VERSION ""

NS_ :

BS_:

BU_: WPC2 RLPSU DPSU APSU PSB SHVU_RR vHS_B2 FCS EMCU SLB ARS RCM CGW_CCU vDummy_HS_B ATS RLHV SGU PFSU ALBCU DSAU SWRC SHVU_FR RCS RRPSU BLTN_CAM SCM DLBCU OHCL RWPC RRHV WPC HOD ASAU

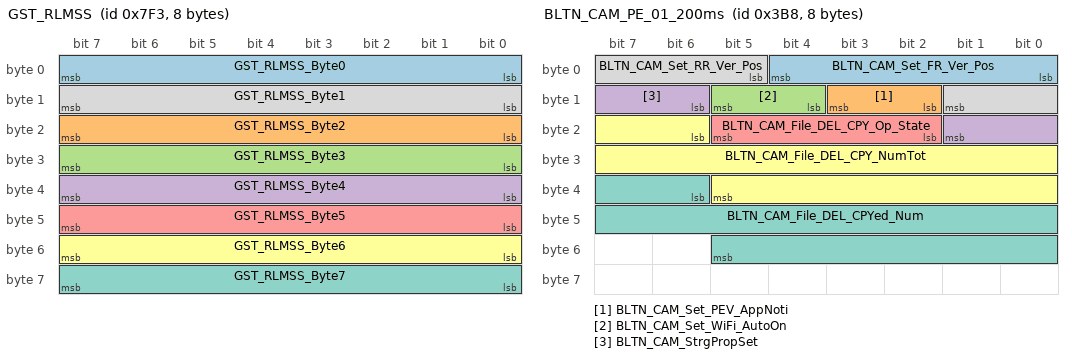
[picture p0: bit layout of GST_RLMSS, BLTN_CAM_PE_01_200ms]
BO_ 2035 GST_RLMSS: 8 CGW_CCU
 SG_ GST_RLMSS_Byte0 : 0|8@1+ (1,0) [0|0] ""  RLPSU
 SG_ GST_RLMSS_Byte2 : 16|8@1+ (1,0) [0|0] ""  RLPSU
 SG_ GST_RLMSS_Byte3 : 24|8@1+ (1,0) [0|0] ""  RLPSU
 SG_ GST_RLMSS_Byte4 : 32|8@1+ (1,0) [0|0] ""  RLPSU
 SG_ GST_RLMSS_Byte5 : 40|8@1+ (1,0) [0|0] ""  RLPSU
 SG_ GST_RLMSS_Byte6 : 48|8@1+ (1,0) [0|0] ""  RLPSU
 SG_ GST_RLMSS_Byte7 : 56|8@1+ (1,0) [0|0] ""  RLPSU
 SG_ GST_RLMSS_Byte1 : 8|8@1+ (1,0) [0|0] ""  RLPSU

BO_ 952 BLTN_CAM_PE_01_200ms: 8 BLTN_CAM
 SG_ BLTN_CAM_Set_FR_Ver_Pos : 0|5@1+ (1,0) [0|0] ""  CGW_CCU
 SG_ BLTN_CAM_Set_PEV_AppNoti : 10|2@1+ (1,0) [0|0] ""  CGW_CCU
 SG_ BLTN_CAM_Set_WiFi_AutoOn : 12|2@1+ (1,0) [0|0] ""  CGW_CCU
 SG_ BLTN_CAM_StrgPropSet : 14|4@1+ (1,0) [0|0] ""  CGW_CCU
 SG_ BLTN_CAM_File_DEL_CPY_Op_State : 18|4@1+ (1,0) [0|0] ""  CGW_CCU
 SG_ BLTN_CAM_File_DEL_CPY_NumTot : 22|16@1+ (1,0) [0|0] ""  CGW_CCU
 SG_ BLTN_CAM_File_DEL_CPYed_Num : 38|16@1+ (1,0) [0|0] ""  CGW_CCU
 SG_ BLTN_CAM_Set_RR_Ver_Pos : 5|5@1+ (1,0) [0|0] ""  CGW_CCU

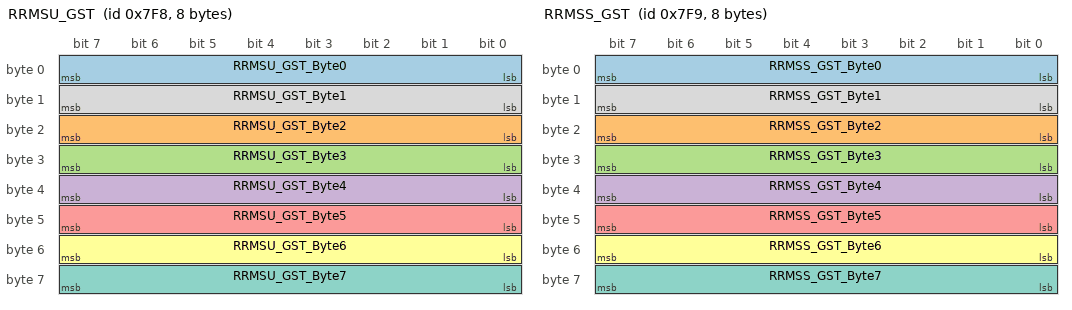
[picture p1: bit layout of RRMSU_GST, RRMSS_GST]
BO_ 2040 RRMSU_GST: 8 RRPSU
 SG_ RRMSU_GST_Byte0 : 0|8@1+ (1,0) [0|0] ""  CGW_CCU
 SG_ RRMSU_GST_Byte2 : 16|8@1+ (1,0) [0|0] ""  CGW_CCU
 SG_ RRMSU_GST_Byte3 : 24|8@1+ (1,0) [0|0] ""  CGW_CCU
 SG_ RRMSU_GST_Byte4 : 32|8@1+ (1,0) [0|0] ""  CGW_CCU
 SG_ RRMSU_GST_Byte5 : 40|8@1+ (1,0) [0|0] ""  CGW_CCU
 SG_ RRMSU_GST_Byte6 : 48|8@1+ (1,0) [0|0] ""  CGW_CCU
 SG_ RRMSU_GST_Byte7 : 56|8@1+ (1,0) [0|0] ""  CGW_CCU
 SG_ RRMSU_GST_Byte1 : 8|8@1+ (1,0) [0|0] ""  CGW_CCU

BO_ 2041 RRMSS_GST: 8 RRPSU
 SG_ RRMSS_GST_Byte0 : 0|8@1+ (1,0) [0|0] ""  CGW_CCU
 SG_ RRMSS_GST_Byte2 : 16|8@1+ (1,0) [0|0] ""  CGW_CCU
 SG_ RRMSS_GST_Byte3 : 24|8@1+ (1,0) [0|0] ""  CGW_CCU
 SG_ RRMSS_GST_Byte4 : 32|8@1+ (1,0) [0|0] ""  CGW_CCU
 SG_ RRMSS_GST_Byte5 : 40|8@1+ (1,0) [0|0] ""  CGW_CCU
 SG_ RRMSS_GST_Byte6 : 48|8@1+ (1,0) [0|0] ""  CGW_CCU
 SG_ RRMSS_GST_Byte7 : 56|8@1+ (1,0) [0|0] ""  CGW_CCU
 SG_ RRMSS_GST_Byte1 : 8|8@1+ (1,0) [0|0] ""  CGW_CCU

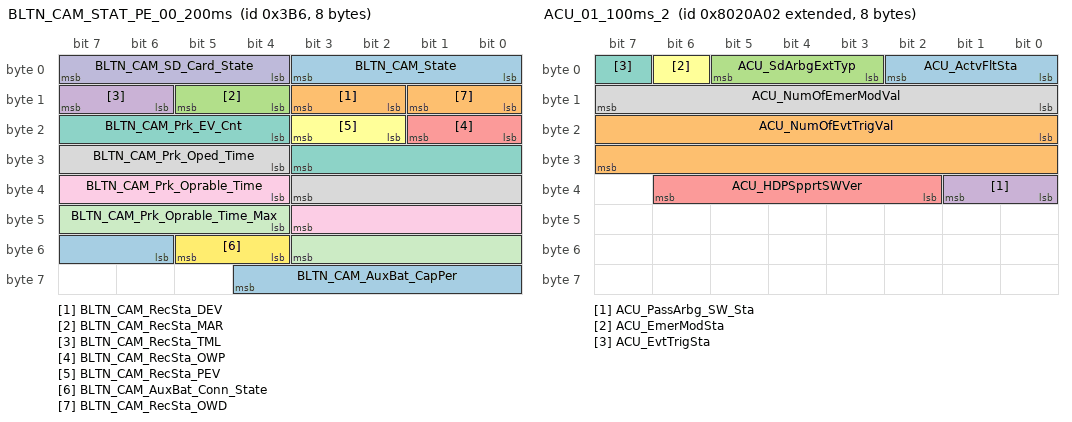
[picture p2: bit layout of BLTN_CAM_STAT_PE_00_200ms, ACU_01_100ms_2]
BO_ 950 BLTN_CAM_STAT_PE_00_200ms: 8 BLTN_CAM
 SG_ BLTN_CAM_State : 0|4@1+ (1,0) [0|0] ""  CGW_CCU
 SG_ BLTN_CAM_RecSta_DEV : 10|2@1+ (1,0) [0|0] ""  CGW_CCU
 SG_ BLTN_CAM_RecSta_MAR : 12|2@1+ (1,0) [0|0] ""  CGW_CCU
 SG_ BLTN_CAM_RecSta_TML : 14|2@1+ (1,0) [0|0] ""  CGW_CCU
 SG_ BLTN_CAM_RecSta_OWP : 16|2@1+ (1,0) [0|0] ""  CGW_CCU
 SG_ BLTN_CAM_RecSta_PEV : 18|2@1+ (1,0) [0|0] ""  CGW_CCU
 SG_ BLTN_CAM_Prk_EV_Cnt : 20|8@1+ (1,0) [0|0] ""  CGW_CCU
 SG_ BLTN_CAM_Prk_Oped_Time : 28|8@1+ (1,0) [0|0] "Hour"  CGW_CCU
 SG_ BLTN_CAM_Prk_Oprable_Time : 36|8@1+ (1,0) [0|0] "Hour"  CGW_CCU
 SG_ BLTN_CAM_SD_Card_State : 4|4@1+ (1,0) [0|0] ""  CGW_CCU
 SG_ BLTN_CAM_Prk_Oprable_Time_Max : 44|8@1+ (1,0) [0|0] "Hour"  CGW_CCU
 SG_ BLTN_CAM_AuxBat_Conn_State : 52|2@1+ (1,0) [0|0] ""  CGW_CCU
 SG_ BLTN_CAM_AuxBat_CapPer : 54|7@1+ (1,0) [0|0] "%"  CGW_CCU
 SG_ BLTN_CAM_RecSta_OWD : 8|2@1+ (1,0) [0|0] ""  CGW_CCU

BO_ 951 BLTN_CAM_PE_00_200ms: 8 BLTN_CAM
 SG_ BLTN_CAM_RecSet_OWD : 0|2@1+ (1,0) [0|0] ""  CGW_CCU
 SG_ BLTN_CAM_Set_Tim_Stm : 10|2@1+ (1,0) [0|0] ""  CGW_CCU
 SG_ BLTN_CAM_Set_Spd_Stm : 12|2@1+ (1,0) [0|0] ""  CGW_CCU
 SG_ BLTN_CAM_Set_Locatn_Stm : 14|2@1+ (1,0) [0|0] ""  CGW_CCU
 SG_ BLTN_CAM_Set_TrnSig_Stm : 16|2@1+ (1,0) [0|0] ""  CGW_CCU
 SG_ BLTN_CAM_Set_AclBrk_Stm : 18|2@1+ (1,0) [0|0] ""  CGW_CCU
 SG_ BLTN_CAM_RecSet_DEV : 2|2@1+ (1,0) [0|0] ""  CGW_CCU
 SG_ BLTN_CAM_Set_GearPos_Stm : 20|2@1+ (1,0) [0|0] ""  CGW_CCU
 SG_ BLTN_CAM_Set_EVSen_Stm : 22|2@1+ (1,0) [0|0] ""  CGW_CCU
 SG_ BLTN_CAM_Set_StrAngl_Stm : 24|2@1+ (1,0) [0|0] ""  CGW_CCU
 SG_ BLTN_CAM_Set_PrkTime : 30|8@1+ (1,0) [0|0] "Hour"  CGW_CCU
 SG_ BLTN_CAM_Set_EV_BfrTime : 38|5@1+ (1,0) [0|0] ""  CGW_CCU
 SG_ BLTN_CAM_RecSet_OWP : 4|2@1+ (1,0) [0|0] ""  CGW_CCU
 SG_ BLTN_CAM_Set_EV_AftTime : 43|5@1+ (1,0) [0|0] ""  CGW_CCU
 SG_ BLTN_CAM_Set_Drv_TML_Int : 48|4@1+ (1,0) [0|0] ""  CGW_CCU
 SG_ BLTN_CAM_SenSet_DEV : 52|4@1+ (1,0) [0|0] ""  CGW_CCU
 SG_ BLTN_CAM_SenSet_PEV : 56|4@1+ (1,0) [0|0] ""  CGW_CCU
 SG_ BLTN_CAM_RecSet_PEV : 6|2@1+ (1,0) [0|0] ""  CGW_CCU
 SG_ BLTN_CAM_AudRec_Set : 8|2@1+ (1,0) [0|0] ""  CGW_CCU

BO_ 2281835010 ACU_01_100ms_2: 8 CGW_CCU
 SG_ ACU_ActvFltSta : 0|3@1+ (1,0) [0|0] "" Vector__XXX
 SG_ ACU_NumOfEvtTrigVal : 16|16@1+ (1,0) [0|0] "" Vector__XXX
 SG_ ACU_SdArbgExtTyp : 3|3@1+ (1,0) [0|0] "" Vector__XXX
 SG_ ACU_PassArbg_SW_Sta : 32|2@1+ (1,0) [0|0] "" Vector__XXX
 SG_ ACU_HDPSpprtSWVer : 34|5@1+ (1,0) [0|0] "" Vector__XXX
 SG_ ACU_EmerModSta : 6|1@1+ (1,0) [0|0] "" Vector__XXX
 SG_ ACU_EvtTrigSta : 7|1@1+ (1,0) [0|0] "" Vector__XXX
 SG_ ACU_NumOfEmerModVal : 8|8@1+ (1,0) [0|0] "" Vector__XXX

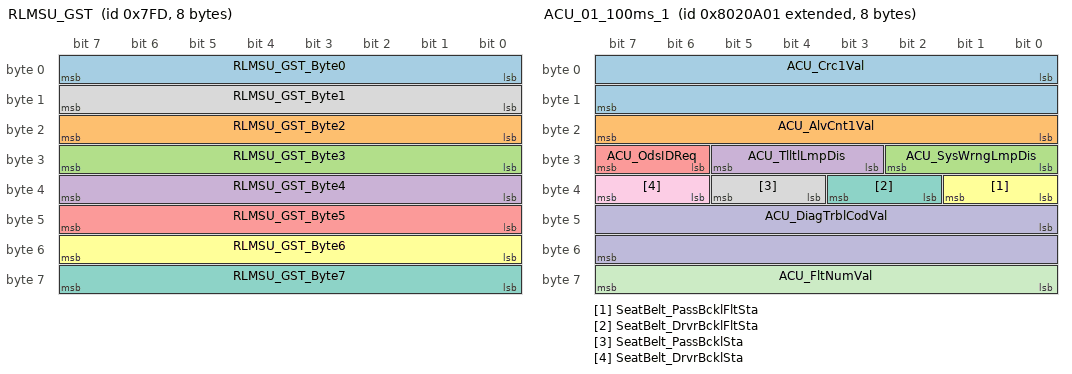
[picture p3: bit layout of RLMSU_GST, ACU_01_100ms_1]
BO_ 2045 RLMSU_GST: 8 RLPSU
 SG_ RLMSU_GST_Byte0 : 0|8@1+ (1,0) [0|0] ""  CGW_CCU
 SG_ RLMSU_GST_Byte2 : 16|8@1+ (1,0) [0|0] ""  CGW_CCU
 SG_ RLMSU_GST_Byte3 : 24|8@1+ (1,0) [0|0] ""  CGW_CCU
 SG_ RLMSU_GST_Byte4 : 32|8@1+ (1,0) [0|0] ""  CGW_CCU
 SG_ RLMSU_GST_Byte5 : 40|8@1+ (1,0) [0|0] ""  CGW_CCU
 SG_ RLMSU_GST_Byte6 : 48|8@1+ (1,0) [0|0] ""  CGW_CCU
 SG_ RLMSU_GST_Byte7 : 56|8@1+ (1,0) [0|0] ""  CGW_CCU
 SG_ RLMSU_GST_Byte1 : 8|8@1+ (1,0) [0|0] ""  CGW_CCU

BO_ 2281835009 ACU_01_100ms_1: 8 CGW_CCU
 SG_ ACU_Crc1Val : 0|16@1+ (1,0) [0|0] ""  OHCL
 SG_ ACU_AlvCnt1Val : 16|8@1+ (1,0) [0|0] ""  OHCL
 SG_ ACU_SysWrngLmpDis : 24|3@1+ (1,0) [0|0] "" Vector__XXX
 SG_ ACU_TlltlLmpDis : 27|3@1+ (1,0) [0|0] ""  OHCL
 SG_ ACU_OdsIDReq : 30|2@1+ (1,0) [0|0] "" Vector__XXX
 SG_ SeatBelt_PassBcklFltSta : 32|2@1+ (1,0) [0|0] ""  PSB
 SG_ SeatBelt_DrvrBcklFltSta : 34|2@1+ (1,0) [0|0] ""  PSB
 SG_ SeatBelt_PassBcklSta : 36|2@1+ (1,0) [0|0] ""  PSB,APSU,ATS
 SG_ SeatBelt_DrvrBcklSta : 38|2@1+ (1,0) [0|0] ""  PSB
 SG_ ACU_DiagTrblCodVal : 40|16@1+ (1,0) [0|0] "" Vector__XXX
 SG_ ACU_FltNumVal : 56|8@1+ (1,0) [0|0] "" Vector__XXX

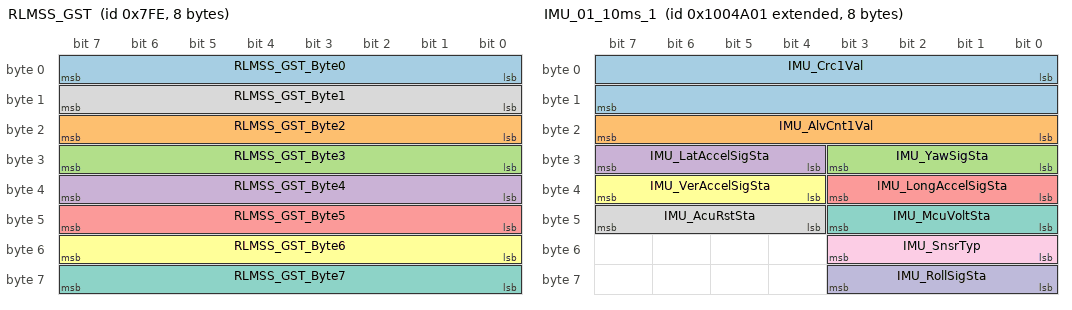
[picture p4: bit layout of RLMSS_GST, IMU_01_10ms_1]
BO_ 2046 RLMSS_GST: 8 RLPSU
 SG_ RLMSS_GST_Byte0 : 0|8@1+ (1,0) [0|0] ""  CGW_CCU
 SG_ RLMSS_GST_Byte2 : 16|8@1+ (1,0) [0|0] ""  CGW_CCU
 SG_ RLMSS_GST_Byte3 : 24|8@1+ (1,0) [0|0] ""  CGW_CCU
 SG_ RLMSS_GST_Byte4 : 32|8@1+ (1,0) [0|0] ""  CGW_CCU
 SG_ RLMSS_GST_Byte5 : 40|8@1+ (1,0) [0|0] ""  CGW_CCU
 SG_ RLMSS_GST_Byte6 : 48|8@1+ (1,0) [0|0] ""  CGW_CCU
 SG_ RLMSS_GST_Byte7 : 56|8@1+ (1,0) [0|0] ""  CGW_CCU
 SG_ RLMSS_GST_Byte1 : 8|8@1+ (1,0) [0|0] ""  CGW_CCU

BO_ 2164279809 IMU_01_10ms_1: 8 CGW_CCU
 SG_ IMU_Crc1Val : 0|16@1+ (1,0) [0|0] "" Vector__XXX
 SG_ IMU_AlvCnt1Val : 16|8@1+ (1,0) [0|0] "" Vector__XXX
 SG_ IMU_YawSigSta : 24|4@1+ (1,0) [0|0] ""  PSB
 SG_ IMU_LatAccelSigSta : 28|4@1+ (1,0) [0|0] ""  PSB
 SG_ IMU_LongAccelSigSta : 32|4@1+ (1,0) [0|0] ""  PSB
 SG_ IMU_VerAccelSigSta : 36|4@1+ (1,0) [0|0] "" Vector__XXX
 SG_ IMU_McuVoltSta : 40|4@1+ (1,0) [0|0] "" Vector__XXX
 SG_ IMU_AcuRstSta : 44|4@1+ (1,0) [0|0] "" Vector__XXX
 SG_ IMU_SnsrTyp : 48|4@1+ (1,0) [0|0] "" Vector__XXX
 SG_ IMU_RollSigSta : 56|4@1+ (1,0) [0|0] "" Vector__XXX

BO_ 2164279811 IMU_01_10ms_3: 8 CGW_CCU
 SG_ IMU_SeralNumVal : 0|48@1+ (1,0) [0|0] "" Vector__XXX

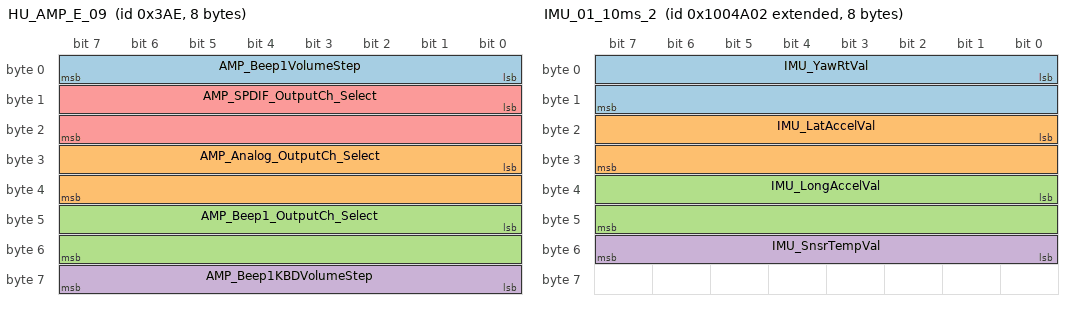
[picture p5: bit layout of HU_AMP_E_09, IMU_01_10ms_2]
BO_ 942 HU_AMP_E_09: 8 CGW_CCU
 SG_ AMP_Beep1VolumeStep : 0|8@1+ (1,0) [0|0] ""  ATS
 SG_ AMP_Analog_OutputCh_Select : 24|16@1+ (1,0) [0|0] "" Vector__XXX
 SG_ AMP_Beep1_OutputCh_Select : 40|16@1+ (1,0) [0|0] "" Vector__XXX
 SG_ AMP_Beep1KBDVolumeStep : 56|8@1+ (1,0) [0|0] "" Vector__XXX
 SG_ AMP_SPDIF_OutputCh_Select : 8|16@1+ (1,0) [0|0] "" Vector__XXX

BO_ 2164279810 IMU_01_10ms_2: 8 CGW_CCU
 SG_ IMU_YawRtVal : 0|16@1+ (0.005,-163.84) [0|0] "¢ª/s"  PSB
 SG_ IMU_LatAccelVal : 16|16@1+ (0.000127465,-4.17677312) [0|0] "g"  PSB
 SG_ IMU_LongAccelVal : 32|16@1+ (0.000127465,-4.17677312) [0|0] "g"  PSB
 SG_ IMU_SnsrTempVal : 48|8@1+ (1,-68) [0|0] "¡É" Vector__XXX

BO_ 2164279812 IMU_01_10ms_4: 8 CGW_CCU
 SG_ IMU_RollRtVal : 0|16@1+ (0.005,-163.84) [0|0] "¢ª/s" Vector__XXX
 SG_ IMU_VerAccelVal : 16|16@1+ (0.000127465,-4.17677312) [0|0] "g" Vector__XXX

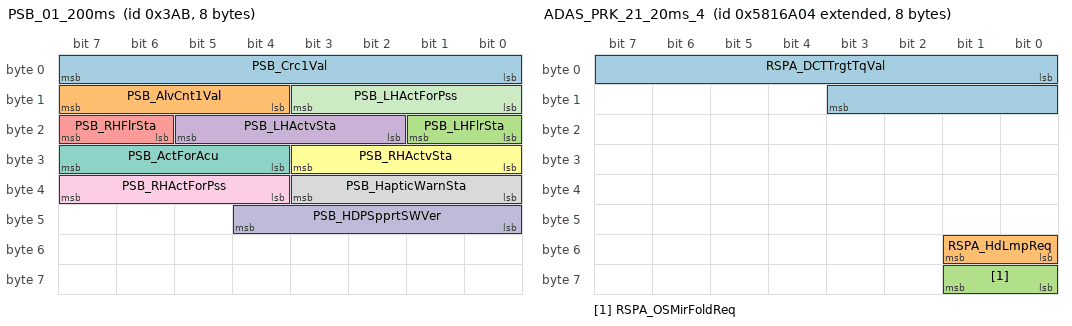
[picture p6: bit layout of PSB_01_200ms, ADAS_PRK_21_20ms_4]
BO_ 939 PSB_01_200ms: 8 PSB
 SG_ PSB_Crc1Val : 0|8@1+ (1,0) [0|0] ""  CGW_CCU
 SG_ PSB_AlvCnt1Val : 12|4@1+ (1,0) [0|0] ""  CGW_CCU
 SG_ PSB_LHFlrSta : 16|2@1+ (1,0) [0|0] ""  CGW_CCU
 SG_ PSB_LHActvSta : 18|4@1+ (1,0) [0|0] ""  CGW_CCU
 SG_ PSB_RHFlrSta : 22|2@1+ (1,0) [0|0] ""  CGW_CCU
 SG_ PSB_RHActvSta : 24|4@1+ (1,0) [0|0] ""  APSU,CGW_CCU
 SG_ PSB_ActForAcu : 28|4@1+ (1,0) [0|0] ""  CGW_CCU
 SG_ PSB_HapticWarnSta : 32|4@1+ (1,0) [0|0] ""  CGW_CCU
 SG_ PSB_RHActForPss : 36|4@1+ (1,0) [0|0] ""  APSU,RLPSU,RRPSU
 SG_ PSB_HDPSpprtSWVer : 40|5@1+ (1,0) [0|0] ""  CGW_CCU
 SG_ PSB_LHActForPss : 8|4@1+ (1,0) [0|0] ""  RLPSU,RRPSU

BO_ 2239851012 ADAS_PRK_21_20ms_4: 8 CGW_CCU
 SG_ RSPA_DCTTrgtTqVal : 0|12@1- (1,0) [0|0] "Nm" Vector__XXX
 SG_ RSPA_HdLmpReq : 48|2@1+ (1,0) [0|0] "" Vector__XXX
 SG_ RSPA_OSMirFoldReq : 56|2@1+ (1,0) [0|0] "" Vector__XXX

BO_ 934 PTGM_01_200ms: 8 CGW_CCU
 SG_ PTGM_Crc1Val : 0|8@1+ (1,0) [0|0] "" Vector__XXX
 SG_ PTGM_AlvCnt1Val : 12|4@1+ (1,0) [0|0] "" Vector__XXX
 SG_ PTGM_HazardSta : 16|2@1+ (1,0) [0|0] "" Vector__XXX
 SG_ PTGM_ModSta : 18|2@1+ (1,0) [0|0] "" Vector__XXX
 SG_ PTGM_MovSta : 20|2@1+ (1,0) [0|0] "" Vector__XXX
 SG_ PTGM_OptTyp : 22|2@1+ (1,0) [0|0] "" Vector__XXX
 SG_ PTGM_ReleaseRlySta : 24|2@1+ (1,0) [0|0] ""  APSU,PFSU
 SG_ PTGM_TrnkLkSwSta : 26|2@1+ (1,0) [0|0] "" Vector__XXX
 SG_ PTGM_UsmSetSta : 28|2@1+ (1,0) [0|0] "" Vector__XXX
 SG_ PTGM_HeightRValue : 32|3@1+ (1,0) [0|0] "" Vector__XXX
 SG_ PTGM_OpnClsState : 35|4@1+ (1,0) [0|0] "" Vector__XXX
 SG_ PTGM_CmdWarn : 40|3@1+ (1,0) [0|0] "" Vector__XXX
 SG_ PTGM_AntiPinchSnsr : 43|2@1+ (1,0) [0|0] "" Vector__XXX
 SG_ PTGM_AutoWashModeSta : 45|3@1+ (1,0) [0|0] "" Vector__XXX
 SG_ PTGM_FobSrch_Req : 52|2@1+ (1,0) [0|0] "" Vector__XXX
 SG_ PTGM_TlgtAwayCloseRValue : 54|2@1+ (1,0) [0|0] "" Vector__XXX
 SG_ PTGM_TrnkTlgtOption : 56|2@1+ (1,0) [0|0] "" Vector__XXX
 SG_ PTGM_LatchType : 58|2@1+ (1,0) [0|0] "" Vector__XXX
 SG_ PTGM_SpeedRValue : 8|4@1+ (1,0) [0|0] "" Vector__XXX

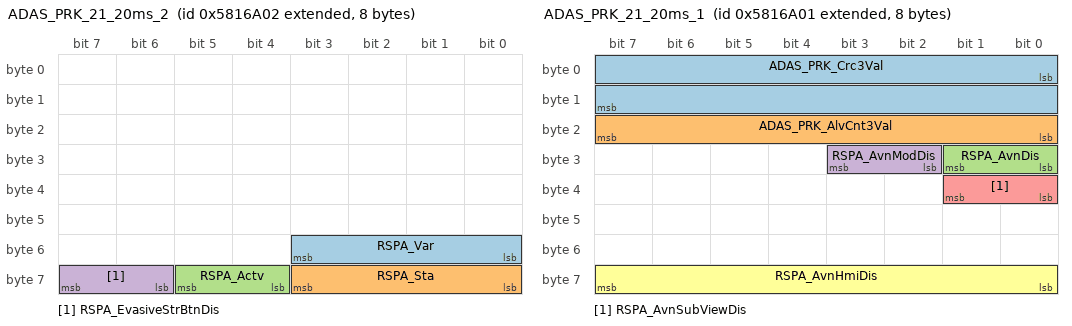
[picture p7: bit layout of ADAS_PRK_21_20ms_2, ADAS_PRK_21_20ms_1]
BO_ 2239851010 ADAS_PRK_21_20ms_2: 8 CGW_CCU
 SG_ RSPA_Var : 48|4@1+ (1,0) [0|0] "" Vector__XXX
 SG_ RSPA_Sta : 56|4@1+ (1,0) [0|0] "" Vector__XXX
 SG_ RSPA_Actv : 60|2@1+ (1,0) [0|0] "" Vector__XXX
 SG_ RSPA_EvasiveStrBtnDis : 62|2@1+ (1,0) [0|0] "" Vector__XXX

BO_ 929 SCM_03_200ms: 8 SCM
 SG_ SCM_Opt : 0|2@1+ (1,0) [0|0] ""  DPSU,CGW_CCU
 SG_ Tilt_VirtualLimExist : 10|2@1+ (1,0) [0|0] ""  CGW_CCU
 SG_ Tele_SnsrErr : 12|2@1+ (1,0) [0|0] ""  CGW_CCU
 SG_ Tele_VirtualLim : 14|2@1+ (1,0) [0|0] ""  CGW_CCU
 SG_ Tele_VirtualLimExist : 16|2@1+ (1,0) [0|0] ""  CGW_CCU
 SG_ TiltTele_Profile1MemoryExist : 18|2@1+ (1,0) [0|0] ""  CGW_CCU
 SG_ Tilt_MnlSwSta : 2|2@1+ (1,0) [0|0] ""  CGW_CCU
 SG_ TiltTele_Profile2MemoryExist : 20|2@1+ (1,0) [0|0] ""  CGW_CCU
 SG_ TiltTele_GuestMemoryExist : 22|2@1+ (1,0) [0|0] ""  CGW_CCU
 SG_ TiltTele_IMS1MemoryExist : 24|2@1+ (1,0) [0|0] ""  CGW_CCU
 SG_ TiltTele_IMS2MemoryExist : 26|2@1+ (1,0) [0|0] ""  CGW_CCU
 SG_ TiltTele_IMS3MemoryExist : 28|2@1+ (1,0) [0|0] ""  CGW_CCU
 SG_ TiltTele_ReturnMemoryExist : 30|2@1+ (1,0) [0|0] ""  CGW_CCU
 SG_ Tilt_OpSta : 32|2@1+ (1,0) [0|0] ""  CGW_CCU
 SG_ Tele_OpSta : 34|2@1+ (1,0) [0|0] ""  CGW_CCU
 SG_ Tele_MnlSwSta : 4|2@1+ (1,0) [0|0] ""  CGW_CCU
 SG_ Tilt_SnsrErr : 6|2@1+ (1,0) [0|0] ""  CGW_CCU
 SG_ Tilt_VirtualLim : 8|2@1+ (1,0) [0|0] ""  CGW_CCU

BO_ 2239851011 ADAS_PRK_21_20ms_3: 8 CGW_CCU
 SG_ RSPA_TrgtGearSta : 0|3@1+ (1,0) [0|0] "" Vector__XXX
 SG_ RSPA_IdOutWarnReq : 10|2@1+ (1,0) [0|0] ""  DPSU
 SG_ RSPA_IndBlnkReq : 12|3@1+ (1,0) [0|0] "" Vector__XXX
 SG_ RSPA_SysOff : 15|1@1+ (1,0) [0|0] "" Vector__XXX
 SG_ RSPA_DccCmd : 16|2@1+ (1,0) [0|0] "" Vector__XXX
 SG_ RSPA_StopReq : 18|2@1+ (1,0) [0|0] "" Vector__XXX
 SG_ RSPA_SelDevInfo : 20|2@1+ (1,0) [0|0] "" Vector__XXX
 SG_ RSPA_SelFuncInfo : 22|2@1+ (1,0) [0|0] "" Vector__XXX
 SG_ RSPA_TrgtVehSpdVal : 24|10@1+ (0.01,0) [0|0] "km/h" Vector__XXX
 SG_ RSPA_EpbReq : 3|2@1+ (1,0) [0|0] "" Vector__XXX
 SG_ RSPA_AddtnlAccelActv : 34|2@1+ (1,0) [0|0] "" Vector__XXX
 SG_ RSPA_Opt : 36|2@1+ (1,0) [0|0] "" Vector__XXX
 SG_ RSPA_RmtPrlExitDis : 38|2@1+ (1,0) [0|0] "" Vector__XXX
 SG_ RSPA_TrgtTqVal : 40|12@1- (1,0) [0|0] "Nm" Vector__XXX
 SG_ RSPA_ExtLampReq : 5|3@1+ (1,0) [0|0] "" Vector__XXX
 SG_ RSPA_UppLtTypDis : 52|3@1+ (1,0) [0|0] "" Vector__XXX
 SG_ RSPA_LwrLtTypDis : 55|3@1+ (1,0) [0|0] "" Vector__XXX
 SG_ RSPA_UppRtTypDis : 58|3@1+ (1,0) [0|0] "" Vector__XXX
 SG_ RSPA_LwrRtTypDis : 61|3@1+ (1,0) [0|0] "" Vector__XXX
 SG_ RSPA_CrankingReq : 8|2@1+ (1,0) [0|0] "" Vector__XXX

BO_ 2239851009 ADAS_PRK_21_20ms_1: 8 CGW_CCU
 SG_ ADAS_PRK_Crc3Val : 0|16@1+ (1,0) [0|0] "" Vector__XXX
 SG_ ADAS_PRK_AlvCnt3Val : 16|8@1+ (1,0) [0|0] "" Vector__XXX
 SG_ RSPA_AvnDis : 24|2@1+ (1,0) [0|0] "" Vector__XXX
 SG_ RSPA_AvnModDis : 26|2@1+ (1,0) [0|0] "" Vector__XXX
 SG_ RSPA_AvnSubViewDis : 32|2@1+ (1,0) [0|0] "" Vector__XXX
 SG_ RSPA_AvnHmiDis : 56|8@1+ (1,0) [0|0] "" Vector__XXX

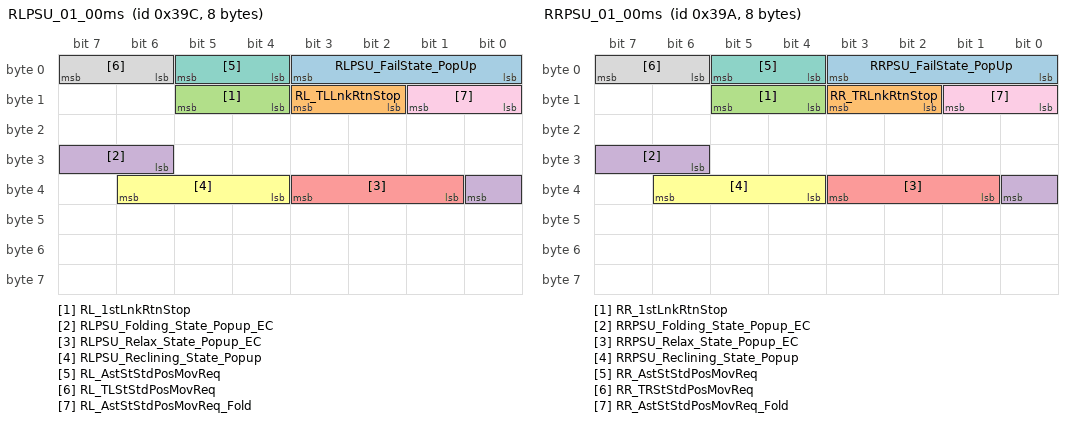
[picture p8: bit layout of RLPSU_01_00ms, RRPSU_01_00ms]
BO_ 924 RLPSU_01_00ms: 8 RRPSU
 SG_ RLPSU_FailState_PopUp : 0|4@1+ (1,0) [0|0] ""  CGW_CCU
 SG_ RL_TLLnkRtnStop : 10|2@1+ (1,0) [0|0] ""  PFSU
 SG_ RL_1stLnkRtnStop : 12|2@1+ (1,0) [0|0] ""  APSU,DPSU
 SG_ RLPSU_Folding_State_Popup_EC : 30|3@1+ (1,0) [0|0] ""  CGW_CCU
 SG_ RLPSU_Relax_State_Popup_EC : 33|3@1+ (1,0) [0|0] "" Vector__XXX
 SG_ RLPSU_Reclining_State_Popup : 36|3@1+ (1,0) [0|0] "" Vector__XXX
 SG_ RL_AstStStdPosMovReq : 4|2@1+ (1,0) [0|0] ""  APSU
 SG_ RL_TLStStdPosMovReq : 6|2@1+ (1,0) [0|0] ""  PFSU
 SG_ RL_AstStStdPosMovReq_Fold : 8|2@1+ (1,0) [0|0] ""  APSU

BO_ 922 RRPSU_01_00ms: 8 RRPSU
 SG_ RRPSU_FailState_PopUp : 0|4@1+ (1,0) [0|0] ""  CGW_CCU
 SG_ RR_TRLnkRtnStop : 10|2@1+ (1,0) [0|0] ""  PFSU
 SG_ RR_1stLnkRtnStop : 12|2@1+ (1,0) [0|0] ""  APSU,DPSU
 SG_ RRPSU_Folding_State_Popup_EC : 30|3@1+ (1,0) [0|0] ""  CGW_CCU
 SG_ RRPSU_Relax_State_Popup_EC : 33|3@1+ (1,0) [0|0] "" Vector__XXX
 SG_ RRPSU_Reclining_State_Popup : 36|3@1+ (1,1) [0|0] "" Vector__XXX
 SG_ RR_AstStStdPosMovReq : 4|2@1+ (1,0) [0|0] ""  APSU
 SG_ RR_TRStStdPosMovReq : 6|2@1+ (1,0) [0|0] ""  PFSU
 SG_ RR_AstStStdPosMovReq_Fold : 8|2@1+ (1,0) [0|0] ""  APSU

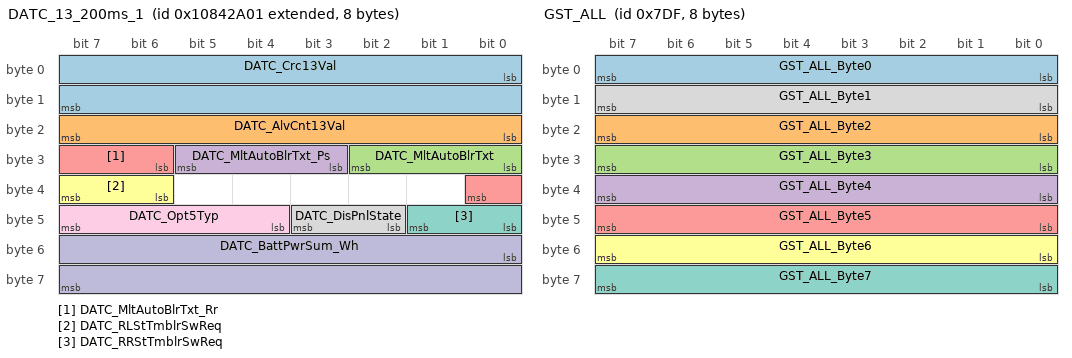
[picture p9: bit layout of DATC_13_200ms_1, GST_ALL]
BO_ 2424580609 DATC_13_200ms_1: 8 CGW_CCU
 SG_ DATC_Crc13Val : 0|16@1+ (1,0) [0|0] "" Vector__XXX
 SG_ DATC_AlvCnt13Val : 16|8@1+ (1,0) [0|0] "" Vector__XXX
 SG_ DATC_MltAutoBlrTxt : 24|3@1+ (1,0) [0|0] ""  ATS
 SG_ DATC_MltAutoBlrTxt_Ps : 27|3@1+ (1,0) [0|0] ""  ATS
 SG_ DATC_MltAutoBlrTxt_Rr : 30|3@1+ (1,0) [0|0] ""  ATS
 SG_ DATC_RLStTmblrSwReq : 38|2@1+ (1,0) [0|0] ""  RLHV,RRHV,SHVU_FR,SHVU_RR,RLPSU
 SG_ DATC_RRStTmblrSwReq : 40|2@1+ (1,0) [0|0] ""  RRHV,SHVU_FR,SHVU_RR,RRPSU
 SG_ DATC_DisPnlState : 42|2@1+ (1,0) [0|0] "" Vector__XXX
 SG_ DATC_Opt5Typ : 44|4@1+ (1,0) [0|0] ""  ATS
 SG_ DATC_BattPwrSum_Wh : 48|16@1+ (1,0) [0|0] "Wh" Vector__XXX

BO_ 2015 GST_ALL: 8 CGW_CCU
 SG_ GST_ALL_Byte0 : 0|8@1+ (1,0) [0|0] ""  FCS,SCM,WPC,RWPC,PSB,SLB,ARS,SWRC,APSU,RLHV,RRHV,SHVU_FR,SHVU_RR,DPSU,DLBCU,PFSU,RCS,RRPSU,RLPSU,HOD,ATS,DSAU,ASAU,RCM,EMCU,SGU,ALBCU,WPC2
 SG_ GST_ALL_Byte2 : 16|8@1+ (1,0) [0|0] ""  FCS,SCM,WPC,RWPC,PSB,SLB,ARS,SWRC,APSU,RLHV,RRHV,SHVU_FR,SHVU_RR,DPSU,DLBCU,PFSU,RCS,RRPSU,RLPSU,HOD,ATS,DSAU,ASAU,RCM,EMCU,SGU,ALBCU,WPC2
 SG_ GST_ALL_Byte3 : 24|8@1+ (1,0) [0|0] ""  FCS,SCM,WPC,RWPC,PSB,SLB,ARS,SWRC,APSU,RLHV,RRHV,SHVU_FR,SHVU_RR,DPSU,DLBCU,PFSU,RCS,RRPSU,RLPSU,HOD,ATS,DSAU,ASAU,RCM,EMCU,SGU,ALBCU,WPC2
 SG_ GST_ALL_Byte4 : 32|8@1+ (1,0) [0|0] ""  FCS,SCM,WPC,RWPC,PSB,SLB,ARS,SWRC,APSU,RLHV,RRHV,SHVU_FR,SHVU_RR,DPSU,DLBCU,PFSU,RCS,RRPSU,RLPSU,HOD,ATS,DSAU,ASAU,RCM,EMCU,SGU,ALBCU,WPC2
 SG_ GST_ALL_Byte5 : 40|8@1+ (1,0) [0|0] ""  FCS,SCM,WPC,RWPC,PSB,SLB,ARS,SWRC,APSU,RLHV,RRHV,SHVU_FR,SHVU_RR,DPSU,DLBCU,PFSU,RCS,RRPSU,RLPSU,HOD,ATS,DSAU,ASAU,RCM,EMCU,SGU,ALBCU,WPC2
 SG_ GST_ALL_Byte6 : 48|8@1+ (1,0) [0|0] ""  FCS,SCM,WPC,RWPC,PSB,SLB,ARS,SWRC,APSU,RLHV,RRHV,SHVU_FR,SHVU_RR,DPSU,DLBCU,PFSU,RCS,RRPSU,RLPSU,HOD,ATS,DSAU,ASAU,RCM,EMCU,SGU,ALBCU,WPC2
 SG_ GST_ALL_Byte7 : 56|8@1+ (1,0) [0|0] ""  FCS,SCM,WPC,RWPC,PSB,SLB,ARS,SWRC,APSU,RLHV,RRHV,SHVU_FR,SHVU_RR,DPSU,DLBCU,PFSU,RCS,RRPSU,RLPSU,HOD,ATS,DSAU,ASAU,RCM,EMCU,SGU,ALBCU,WPC2
 SG_ GST_ALL_Byte1 : 8|8@1+ (1,0) [0|0] ""  FCS,SCM,WPC,RWPC,PSB,SLB,ARS,SWRC,APSU,RLHV,RRHV,SHVU_FR,SHVU_RR,DPSU,DLBCU,PFSU,RCS,RRPSU,RLPSU,HOD,ATS,DSAU,ASAU,RCM,EMCU,SGU,ALBCU,WPC2

BO_ 915 BCM_18_200ms: 8 CGW_CCU
 SG_ BCM_Crc18Val : 0|8@1+ (1,0) [0|0] "" Vector__XXX
 SG_ BCM_AlvCnt18Val : 12|4@1+ (1,0) [0|0] "" Vector__XXX
 SG_ Trunk_IBU_OpnDiagSetSta : 16|2@1+ (1,0) [0|0] "" Vector__XXX
 SG_ Trunk_TrnkTlgtReleaseRly : 18|2@1+ (1,0) [0|0] "" Vector__XXX
 SG_ Trunk_TrnkTlgtOpenOutput_PTGM : 20|2@1+ (1,0) [0|0] "" Vector__XXX
 SG_ Trunk_TrnkTlgtOpenOutput_ICU : 22|2@1+ (1,0) [0|0] "" Vector__XXX
 SG_ Trunk_TrnkPassiveOpenOutput : 24|2@1+ (1,0) [0|0] "" Vector__XXX
 SG_ TiltTele_CurProfileState : 26|3@1+ (1,0) [0|0] ""  SCM
 SG_ TiltTele_USMEsyAcsSetState : 29|2@1+ (1,0) [0|0] ""  DPSU
 SG_ TiltTele_PreEsyAcsProfile : 31|3@1+ (1,0) [0|0] ""  SCM
 SG_ Tilt_MnlInitCmd : 34|2@1+ (1,0) [0|0] ""  SCM
 SG_ Tilt_MnlOpCmd : 36|2@1+ (1,0) [0|0] ""  SCM
 SG_ Tele_MnlInitCmd : 38|2@1+ (1,0) [0|0] ""  SCM
 SG_ Tilt_AutoOpCmd : 40|4@1+ (1,0) [0|0] ""  SCM
 SG_ TiltTele_PlyBckState : 44|4@1+ (1,0) [0|0] ""  DPSU
 SG_ Tele_MnlOpCmd : 48|2@1+ (1,0) [0|0] ""  SCM
 SG_ Tele_AutoOpCmd : 52|4@1+ (1,0) [0|0] ""  SCM

BO_ 912 HU_BLTN_CAM_PE_00_200ms: 8 CGW_CCU
 SG_ HU_BLTN_CAM_UI_Mode : 0|4@1+ (1,0) [0|0] ""  BLTN_CAM
 SG_ HU_BLTN_CAM_Display : 4|3@1+ (1,0) [0|0] ""  BLTN_CAM

BO_TX_BU_ 924 : RRPSU,RLPSU;
CM_ BO_ 2035 "[TP] Transport Protocol";
CM_ BO_ 952 "[PE] Periodic and On Event";
CM_ SG_ 952 BLTN_CAM_Set_FR_Ver_Pos "Front Camera Vertical position setting value.";
CM_ SG_ 952 BLTN_CAM_Set_PEV_AppNoti "Parked Event notification to Connectivity Phone App. On/Off";
CM_ SG_ 952 BLTN_CAM_Set_WiFi_AutoOn "Wifi On/Off User setting";
CM_ SG_ 952 BLTN_CAM_StrgPropSet "Propotion of built-in Cam SD card Propotion set of the Recording Categories";
CM_ SG_ 952 BLTN_CAM_File_DEL_CPY_Op_State "Bulil in Cam Fily copy and delete operating state.";
CM_ SG_ 952 BLTN_CAM_File_DEL_CPY_NumTot "Number of Copied or Deleted files.";
CM_ SG_ 952 BLTN_CAM_File_DEL_CPYed_Num "Total number of the copy or delete file.";
CM_ SG_ 952 BLTN_CAM_Set_RR_Ver_Pos "Rear Camera Vertical position setting value.";
CM_ BO_ 2040 "[TP] Transport Protocol";
CM_ BO_ 2041 "[TP] Transport Protocol";
CM_ BO_ 950 "[PE] Periodic and On Event";
CM_ SG_ 950 BLTN_CAM_State "This Signal is for cluster warning popup.";
CM_ SG_ 950 BLTN_CAM_RecSta_DEV "This Signal inform recording status of Driving Event.";
CM_ SG_ 950 BLTN_CAM_RecSta_MAR "This Signal inform recording status of Manual Recording.";
CM_ SG_ 950 BLTN_CAM_RecSta_TML "This Signal inform recording status of Time-lapse.";
CM_ SG_ 950 BLTN_CAM_RecSta_OWP "This Signal inform recording status of On While Parked.";
CM_ SG_ 950 BLTN_CAM_RecSta_PEV "This Signal inform recording status of Parked Event.";
CM_ SG_ 950 BLTN_CAM_Prk_EV_Cnt "The count number of a parked Event.";
CM_ SG_ 950 BLTN_CAM_Prk_Oped_Time "The Parked Opreated time ingormation";
CM_ SG_ 950 BLTN_CAM_Prk_Oprable_Time "The hours of Park Mode Operatable, the time is limited by user max oper. Set.";
CM_ SG_ 950 BLTN_CAM_SD_Card_State "This Signal is for SD card Status in Built-in App menu and CCS Phone App.";
CM_ SG_ 950 BLTN_CAM_Prk_Oprable_Time_Max "The hours of Park Mode Operatable, the time has no limit.";
CM_ SG_ 950 BLTN_CAM_AuxBat_Conn_State "0x0 : Default / 0x1 : Auxiliary Battery is connected.(P-LBM or B-LBM) / 0x2 : Auxiliary Battery Is not connected. - Auxiliary Battery applicable on this vehicle model / 0x3:  Auxiliary Battery is not connected. ? Auxiliary Battery not applicable on this vehicle model";
CM_ SG_ 950 BLTN_CAM_AuxBat_CapPer "The percentage of Aux. Bat.";
CM_ SG_ 950 BLTN_CAM_RecSta_OWD "This Signal inform recording status of On While Driving.";
CM_ BO_ 951 "[PE] Periodic and On Event";
CM_ SG_ 951 BLTN_CAM_RecSet_OWD "Record On/Off Set of On While Driving";
CM_ SG_ 951 BLTN_CAM_Set_Tim_Stm "Record Set of Date and Time Stamp";
CM_ SG_ 951 BLTN_CAM_Set_Spd_Stm "Record Set of Speed Stamp";
CM_ SG_ 951 BLTN_CAM_Set_Locatn_Stm "Record Set of Location Stamp";
CM_ SG_ 951 BLTN_CAM_Set_TrnSig_Stm "Record Set of Turn Signal Stamp";
CM_ SG_ 951 BLTN_CAM_Set_AclBrk_Stm "Record Set of Accelerator Brake Stamp";
CM_ SG_ 951 BLTN_CAM_RecSet_DEV "Record On/Off Set of Driving Event";
CM_ SG_ 951 BLTN_CAM_Set_GearPos_Stm "Record Set of Gear Position Stamp";
CM_ SG_ 951 BLTN_CAM_Set_EVSen_Stm "Record Set of Event Sensitivity Stamp";
CM_ SG_ 951 BLTN_CAM_Set_StrAngl_Stm "Record Set of Steering Angle Stamp";
CM_ SG_ 951 BLTN_CAM_Set_PrkTime "Parking Operation Setting Time, Resolution : hr";
CM_ SG_ 951 BLTN_CAM_Set_EV_BfrTime "Driving Event Time Setting - Before, Resolution : sec";
CM_ SG_ 951 BLTN_CAM_RecSet_OWP "Record On/Off Set of On While Parked, 0x0(Default) : Parking recording function not supported";
CM_ SG_ 951 BLTN_CAM_Set_EV_AftTime "Driving Event Time Setting - After, Resolution : sec";
CM_ SG_ 951 BLTN_CAM_Set_Drv_TML_Int "Record Set of Time-lapse Interval, Resolution : sec";
CM_ SG_ 951 BLTN_CAM_SenSet_DEV "Set of Event  Detection Sensitivity of Driving Mode";
CM_ SG_ 951 BLTN_CAM_SenSet_PEV "Set of Event  Detection Sensitivity of Parking Mode";
CM_ SG_ 951 BLTN_CAM_RecSet_PEV "Record Set of Parked Event, 0x0(Default) : Parking recording function not supported";
CM_ SG_ 951 BLTN_CAM_AudRec_Set "Audio Record On/Off Set";
CM_ BO_ 2281835010 "[P] Periodic";
CM_ SG_ 2281835010 ACU_ActvFltSta "ACU_ActiveFaultStatus ##2G##ACU - ACU11 - CF_Acu_FltStat";
CM_ SG_ 2281835010 ACU_NumOfEvtTrigVal "EDR trigger counter";
CM_ SG_ 2281835010 ACU_SdArbgExtTyp "ACU_SideAirbagExistanceType ##2G##ACU - ACU11 - CF_Acu_ExtOfSab";
CM_ SG_ 2281835010 ACU_PassArbg_SW_Sta "PAB ON_OFF S/W state for USM";
CM_ SG_ 2281835010 ACU_HDPSpprtSWVer "Software version information of signals related to HDP cooperative control";
CM_ SG_ 2281835010 ACU_EvtTrigSta "EDR triggered information bit";
CM_ SG_ 2281835010 ACU_NumOfEmerModVal "Emergency mode counter";
CM_ BO_ 2045 "[TP] Transport Protocol";
CM_ BO_ 2281835009 "[P] Periodic";
CM_ SG_ 2281835009 ACU_Crc1Val "ACU_CyclicRedundancyCheck1Value";
CM_ SG_ 2281835009 ACU_AlvCnt1Val "ACU_AliveCounter1Value";
CM_ SG_ 2281835009 ACU_SysWrngLmpDis "ACU_SystemWarningLampDisplay ##2G##ACU - ACU14 - CF_SWL_Ind";
CM_ SG_ 2281835009 ACU_TlltlLmpDis "PAB ON OFF Lamp indication bit. 00X : PAB OFF LAMP, 0YO : PAB ON LAMP";
CM_ SG_ 2281835009 ACU_OdsIDReq "ACU_OdsIDRequest ##2G##ACU - ACU11 - CF_Ods_IDRcv";
CM_ SG_ 2281835009 SeatBelt_PassBcklFltSta "SeatBelt_PassengerBuckleFaultStatus ##2G##ACU - ACU11 - CF_PasBkl_FltStat";
CM_ SG_ 2281835009 SeatBelt_DrvrBcklFltSta "SeatBelt_DriverBuckleFaultStatus ##2G##ACU - ACU11 - CF_DriBkl_FltStat";
CM_ SG_ 2281835009 SeatBelt_PassBcklSta "SeatBelt_PassengerBuckleStatus ##2G##ACU - ACU11 - CF_PasBkl_Stat";
CM_ SG_ 2281835009 SeatBelt_DrvrBcklSta "SeatBelt_DriverBuckleStatus ##2G##ACU - ACU11 - CF_DriBkl_Stat";
CM_ SG_ 2281835009 ACU_DiagTrblCodVal "ACU_DiagnosticTroubleCodeValue ##2G##ACU - ACU11 - CF_Acu_Dtc";
CM_ SG_ 2281835009 ACU_FltNumVal "ACU_FaultNumberValue ##2G##ACU - ACU11 - CF_Acu_NumOfFlt";
CM_ BO_ 2046 "[TP] Transport Protocol";
CM_ BO_ 2164279809 "[P] Periodic";
CM_ SG_ 2164279809 IMU_Crc1Val "IMU_CyclicRedundancyCheck1Value";
CM_ SG_ 2164279809 IMU_AlvCnt1Val "IMU_AliveCounter1Value";
CM_ SG_ 2164279809 IMU_YawSigSta "IMU_YawSignalStatus ##2G##YRS - YRS11 - CF_Yrs_YrStat";
CM_ SG_ 2164279809 IMU_LatAccelSigSta "IMU_LateralAccelerationSignalStatus ##2G##YRS - YRS11 - CF_Yrs_LatAcStat";
CM_ SG_ 2164279809 IMU_LongAccelSigSta "IMU_LongitudinalAccelerationSignalStatus ##2G##YRS - YRS12 - CF_Yrs_LongAcStat";
CM_ SG_ 2164279809 IMU_VerAccelSigSta "IMU_Vertial Acceleration Signal Status";
CM_ SG_ 2164279809 IMU_McuVoltSta "IMU_McuVoltageStatus ##2G##YRS - YRS11 - CF_Yrs_MCUStat";
CM_ SG_ 2164279809 IMU_AcuRstSta "IMU_AcuResetStatus ##2G##YRS - YRS12 - CF_IMU_ResetStat";
CM_ SG_ 2164279809 IMU_SnsrTyp "IMU SensorType (Axis information)##2G##YRS - YRS12 - CF_Yrs_Type";
CM_ SG_ 2164279809 IMU_RollSigSta "IMU Rollrate signal status";
CM_ BO_ 2164279811 "[P] Periodic";
CM_ SG_ 2164279811 IMU_SeralNumVal "IMU_SerialNumberValue ##2G##YRS - YRS13 - YRS_SeralNo";
CM_ BO_ 942 "[EC] On Event and On Change";
CM_ SG_ 942 AMP_Beep1VolumeStep "Command for Touch Beep Sound Volume Setting 
-range : 0 ~ max
-max : value of AMP_MaxBeep1VolumeState(0x087)
Harman AMP Only
-This Signal's Feedback is AMP_Beep1VolumeState(0x08A)@AMP";
CM_ BO_ 2164279810 "[P] Periodic";
CM_ SG_ 2164279810 IMU_YawRtVal "IMU_YawRateValue ##2G##YRS - YRS11 - CR_Yrs_Yr";
CM_ SG_ 2164279810 IMU_LatAccelVal "IMU_LateralAccelerationValue ##2G##YRS - YRS11 - CR_Yrs_LatAc";
CM_ SG_ 2164279810 IMU_LongAccelVal "IMU_LongitudinalAccelerationValue ##2G##YRS - YRS12 - CR_Yrs_LongAc";
CM_ SG_ 2164279810 IMU_SnsrTempVal "IMU_SensorTemperatureValue ##2G##YRS - YRS12 - YRS_Temp";
CM_ BO_ 2164279812 "[P] Periodic";
CM_ SG_ 2164279812 IMU_RollRtVal "IMU_Roll rate signal value";
CM_ SG_ 2164279812 IMU_VerAccelVal "IMU_Vertial Acceleration value";
CM_ BO_ 939 "[P] Periodic";
CM_ SG_ 939 PSB_Crc1Val "PSB_CyclicRedundancyCheck1Value";
CM_ SG_ 939 PSB_AlvCnt1Val "PSB_AliveCounter1Value";
CM_ SG_ 939 PSB_LHFlrSta "PSB_LeftHandedFailureStatus";
CM_ SG_ 939 PSB_LHActvSta "PSB_LeftHandedActiveStatus";
CM_ SG_ 939 PSB_RHFlrSta "PSB_RightHandedFailureStatus";
CM_ SG_ 939 PSB_RHActvSta "PSB_RightHandedActiveStatus";
CM_ SG_ 939 PSB_ActForAcu "PSB_ActiveForAcu";
CM_ SG_ 939 PSB_HapticWarnSta "PSB_Haptic_Warning_Status";
CM_ SG_ 939 PSB_RHActForPss "PSB_RightHandedActiveStatus_forPss";
CM_ SG_ 939 PSB_HDPSpprtSWVer "Requirement Spec Version about PSB haptic active by HDP";
CM_ SG_ 939 PSB_LHActForPss "PSB_LeftHandedActiveStatus_forPss";
CM_ BO_ 2239851012 "[P] Periodic";
CM_ SG_ 2239851012 RSPA_DCTTrgtTqVal "RSPA_DCTTargetTorqueValue";
CM_ SG_ 2239851012 RSPA_HdLmpReq "RSPA Head Lamp Request";
CM_ SG_ 2239851012 RSPA_OSMirFoldReq "RSPA_OSMirrorFoldRequest";
CM_ BO_ 934 "[PE] Periodic and On Event";
CM_ SG_ 934 PTGM_Crc1Val "PTGM_CyclicRedundancyCheck1Value";
CM_ SG_ 934 PTGM_AlvCnt1Val "PTGM_AliveCounter1Value";
CM_ SG_ 934 PTGM_HazardSta "PTGM_HazardStatus";
CM_ SG_ 934 PTGM_ModSta "PTGM_ModuleStatus";
CM_ SG_ 934 PTGM_MovSta "PTGM_MovingStatus";
CM_ SG_ 934 PTGM_OptTyp "PTGM_OptionType";
CM_ SG_ 934 PTGM_ReleaseRlySta "PTGM_ReleaseRelayStatus";
CM_ SG_ 934 PTGM_TrnkLkSwSta "PTGM_TrunkLockSwitchStatus";
CM_ SG_ 934 PTGM_UsmSetSta "PTGM_UsmSettingStatus";
CM_ SG_ 934 PTGM_FobSrch_Req "FOB Search Request";
CM_ SG_ 934 PTGM_TlgtAwayCloseRValue "PTGM_TailgateAwayCloseRValue";
CM_ SG_ 934 PTGM_TrnkTlgtOption "PTGM_TrnkTlgtOption";
CM_ SG_ 934 PTGM_LatchType "PTGM_LatchType";
CM_ BO_ 2239851010 "[P] Periodic";
CM_ SG_ 2239851010 RSPA_Var "RSPA_Variation";
CM_ SG_ 2239851010 RSPA_Sta "RSPA_Status";
CM_ SG_ 2239851010 RSPA_Actv "RSPA_Actvation";
CM_ SG_ 2239851010 RSPA_EvasiveStrBtnDis "RSPA_EvasiveSteeringButtonDisplay";
CM_ BO_ 929 "[PE] Periodic and On Event";
CM_ BO_ 2239851011 "[P] Periodic";
CM_ SG_ 2239851011 RSPA_TrgtGearSta "RSPA_TargetGearStatus";
CM_ SG_ 2239851011 RSPA_IdOutWarnReq "RSPA_IdOutWarningRequest";
CM_ SG_ 2239851011 RSPA_IndBlnkReq "RSPA_IndicatorBlinkingRequest";
CM_ SG_ 2239851011 RSPA_SysOff "RSPA System status flag";
CM_ SG_ 2239851011 RSPA_DccCmd "RSPA_DccelerationCommand";
CM_ SG_ 2239851011 RSPA_StopReq "RSPA_StopRequest";
CM_ SG_ 2239851011 RSPA_SelDevInfo "Selected Remote Device Information";
CM_ SG_ 2239851011 RSPA_SelFuncInfo "Selected RSPA Function Information";
CM_ SG_ 2239851011 RSPA_TrgtVehSpdVal "RSPA_TargetVehicleSpeedValue";
CM_ SG_ 2239851011 RSPA_EpbReq "RSPA_EPBRequest";
CM_ SG_ 2239851011 RSPA_AddtnlAccelActv "RSPA_AdditionalAccelarationActivation";
CM_ SG_ 2239851011 RSPA_Opt "RSPA_Option";
CM_ SG_ 2239851011 RSPA_RmtPrlExitDis "RSPA_RemoteParallelExitDisplay";
CM_ SG_ 2239851011 RSPA_TrgtTqVal "RSPA_TargetTorqueValue";
CM_ SG_ 2239851011 RSPA_ExtLampReq "RSPA_ExternalLampRequest";
CM_ SG_ 2239851011 RSPA_UppLtTypDis "RSPA_UpperLeftTypeDisplay";
CM_ SG_ 2239851011 RSPA_LwrLtTypDis "RSPA_LowerLeftTypeDisplay";
CM_ SG_ 2239851011 RSPA_UppRtTypDis "RSPA_UpperRightTypeDisplay";
CM_ SG_ 2239851011 RSPA_LwrRtTypDis "RSPA_LowerRightTypeDisplay";
CM_ SG_ 2239851011 RSPA_CrankingReq "RSPA_CrankingRequest";
CM_ BO_ 2239851009 "[P] Periodic";
CM_ SG_ 2239851009 ADAS_PRK_Crc3Val "ADAS_PRK_CyclicRedundancyCheck3Value";
CM_ SG_ 2239851009 ADAS_PRK_AlvCnt3Val "ADAS_PRK_AliveCounter3Value";
CM_ SG_ 2239851009 RSPA_AvnDis "RSPA_AvnDisplay";
CM_ SG_ 2239851009 RSPA_AvnModDis "RSPA_AvnModeDisplay";
CM_ SG_ 2239851009 RSPA_AvnSubViewDis "RSPA_AvnSubViewDisplay";
CM_ SG_ 2239851009 RSPA_AvnHmiDis "RSPA_AvnHmiDisplay";
CM_ BO_ 924 "[EC] On Event and On Change";
CM_ SG_ 924 RLPSU_FailState_PopUp "Rear LH Seat Operating Finish or Operating Disable Information for AVN Display";
CM_ SG_ 924 RLPSU_Folding_State_Popup_EC "Rear LH seat Folding State information";
CM_ SG_ 924 RLPSU_Relax_State_Popup_EC "Rear LH seat Relax State information";
CM_ SG_ 924 RLPSU_Reclining_State_Popup "(2nd Left Seat Power Seat) OSD Indicator Signal for Inoperable State";
CM_ BO_ 922 "[EC] On Event and On Change";
CM_ SG_ 922 RRPSU_FailState_PopUp "2nd RH Seat Operating Finish or Operating Disable Information for AVN Display";
CM_ SG_ 922 RRPSU_Folding_State_Popup_EC "Rear RH seat Folding State information";
CM_ SG_ 922 RRPSU_Relax_State_Popup_EC "Rear RH seat Relax State information";
CM_ SG_ 922 RRPSU_Reclining_State_Popup "(2nd Right Seat Power Seat) ODS Indicator Siganl for Inoperable State";
CM_ BO_ 2424580609 "[PE] Periodic and On Event";
CM_ SG_ 2424580609 DATC_Crc13Val "DATC_CyclicRedundancyCheck13Value";
CM_ SG_ 2424580609 DATC_AlvCnt13Val "DATC_AliveCounter13Value";
CM_ SG_ 2424580609 DATC_MltAutoBlrTxt "This signal is to display text of Multi Auto Blower step";
CM_ SG_ 2424580609 DATC_MltAutoBlrTxt_Ps "This signal is to display text of Multi Auto Blower step";
CM_ SG_ 2424580609 DATC_MltAutoBlrTxt_Rr "This signal is to display text of Multi Auto Blower step";
CM_ SG_ 2424580609 DATC_RLStTmblrSwReq "DATC_RearLeftSeatTumblerSwitchRequest";
CM_ SG_ 2424580609 DATC_RRStTmblrSwReq "DATC_RearRightSeatTumblerSwitchRequest";
CM_ SG_ 2424580609 DATC_DisPnlState "This signal indicate whether FRONT Climate Display State or REAR Climate Display State";
CM_ SG_ 2424580609 DATC_Opt5Typ "HTR CONTROL OPTION";
CM_ SG_ 2424580609 DATC_BattPwrSum_Wh "accumulated energy consumption of battery while driving(200ms)";
CM_ BO_ 2015 "[TP] Transport Protocol";
CM_ BO_ 915 "[PE] Periodic and On Event";
CM_ SG_ 915 BCM_Crc18Val "BCM_CyclicRedundancyCheck18Value";
CM_ SG_ 915 BCM_AlvCnt18Val "BCM_AliveCounter18Value";
CM_ SG_ 915 Trunk_IBU_OpnDiagSetSta "Trunk_OpenDiagnosticSettingStatus ##2G## -  - C_TrunkOpenDiagSet";
CM_ SG_ 915 Trunk_TrnkTlgtOpenOutput_PTGM "Trunk_TrunkTailgateOpenOutput for PTGM Trunk/Tailgate Open Command";
CM_ SG_ 915 Trunk_TrnkTlgtOpenOutput_ICU "Trunk_TrunkTailgateOpenOutput for ICU Trunk/Tailgate Open Command in PTG";
CM_ SG_ 915 Trunk_TrnkPassiveOpenOutput "Passive Trunk Open Output for ICU Passive Trunk Release Relay Command";
CM_ BO_ 912 "[PE] Periodic and On Event";
CM_ SG_ 912 HU_BLTN_CAM_UI_Mode "Display control of Built-in Cam UI mode. This Signal for Ethernet Type Built-in Cam.";
CM_ SG_ 912 HU_BLTN_CAM_Display "Display control of Built-in Cam UI mode. This Signal for CAN Type Built-in Cam.(with Standard 5th Wide AVNT)";
BA_DEF_ BO_  "DiagState" ENUM  "No","Yes";
BA_DEF_ BO_  "DiagResponse" ENUM  "No","Yes";
BA_DEF_ BO_  "DiagRequest" ENUM  "No","Yes";
BA_DEF_ BO_  "TpMessage" ENUM  "No","Yes";
BA_DEF_ BO_  "UsrMsgIDSforwardDeviation" INT 0 100;
BA_DEF_ BO_  "UsrMsgIDSbackwardDeviation" INT 50 1000;
BA_DEF_ BO_  "GenMsgCycleTime" INT 0 2000;
BA_DEF_ BO_  "GenMsgStartDelayTime" INT 0 2000;
BA_DEF_ BO_  "GenMsgSendType" ENUM  "Cyclic","NoMsgSendType";
BA_DEF_ BO_  "GenMsgCycleTimeFast" INT 0 500;
BA_DEF_ BO_  "GenMsgDelayTime" INT 0 20;
BA_DEF_ BO_  "GenMsgILSupport" ENUM  "No","Yes";
BA_DEF_ BO_  "GenMsgNrOfRepetition" INT 0 3;
BA_DEF_ BO_  "NmMessage" ENUM  "No","Yes";
BA_DEF_ BO_  "NWM-Botschaft" ENUM  "No","Yes";
BA_DEF_ BO_  "TpTxIndex" INT 0 65535;
BA_DEF_ BO_  "VFrameFormat" ENUM  "StandardCAN","ExtendedCAN","reserved","reserved","reserved","reserved","reserved","reserved","reserved","reserved","reserved","reserved","reserved","reserved","StandardCAN_FD","ExtendedCAN_FD";
BA_DEF_ SG_  "UserSigValidity" ENUM  "B+","ACC","IG","IG1","IG2","IG3","IG1 or IG2","IG1 or IG3","Undef";
BA_DEF_ SG_  "TimeoutValue" STRING ;
BA_DEF_ SG_  "UsrSigPurpose" ENUM  "Undef","FN","DIAG","DIAG(Req)","DIAG(Res)","DIAG(Phy)","DEV","CCP(Req)","CCP(Res)","NM","TP";
BA_DEF_ SG_  "GenSigStartValue" INT 0 1215752192;
BA_DEF_ SG_  "NetworkRequest" ENUM  "Yes","No";
BA_DEF_ SG_  "NetworkRequestHoldingTime" INT 0 65535;
BA_DEF_ SG_  "Description" STRING ;
BA_DEF_ SG_  "Version" STRING ;
BA_DEF_ SG_  "GenSigEnvVarType" ENUM  "Int","Float","Undef";
BA_DEF_ SG_  "GenSigSendType" ENUM  "Cyclic","OnWrite","OnWriteWithRepetition","OnChange","OnChangeWithRepetition","IfActive","IfActiveWithRepetition","NoSigSendType","OnChangeAndIfActive","OnChangeAndIfActiveWithRepetition";
BA_DEF_ SG_  "GwSigLatencyTime" INT 0 65536;
BA_DEF_ SG_  "GwSigMissingSourceType" ENUM  "Undef","OldValue","DefaultValue","InitialValue";
BA_DEF_ SG_  "NWM-WakeupAllowed" ENUM  "<n.a.>";
BA_DEF_ SG_  "RoutingFactor" INT 1 1215752192;
BA_DEF_ SG_  "SystemSignalLongSymbol" STRING ;
BA_DEF_REL_ BU_SG_REL_  "GenSigTimeoutTime" INT 0 7000;
BA_DEF_DEF_  "DiagState" "No";
BA_DEF_DEF_  "DiagResponse" "No";
BA_DEF_DEF_  "DiagRequest" "No";
BA_DEF_DEF_  "TpMessage" "No";
BA_DEF_DEF_  "UsrMsgIDSforwardDeviation" 10;
BA_DEF_DEF_  "UsrMsgIDSbackwardDeviation" 100;
BA_DEF_DEF_  "GenMsgCycleTime" 200;
BA_DEF_DEF_  "GenMsgStartDelayTime" 0;
BA_DEF_DEF_  "GenMsgSendType" "NoMsgSendType";
BA_DEF_DEF_  "GenMsgCycleTimeFast" 40;
BA_DEF_DEF_  "GenMsgDelayTime" 20;
BA_DEF_DEF_  "GenMsgILSupport" "Yes";
BA_DEF_DEF_  "GenMsgNrOfRepetition" 3;
BA_DEF_DEF_  "NmMessage" "No";
BA_DEF_DEF_  "NWM-Botschaft" "No";
BA_DEF_DEF_  "TpTxIndex" 0;
BA_DEF_DEF_  "VFrameFormat" "StandardCAN";
BA_DEF_DEF_  "UserSigValidity" "IG";
BA_DEF_DEF_  "TimeoutValue" "";
BA_DEF_DEF_  "UsrSigPurpose" "FN";
BA_DEF_DEF_  "GenSigStartValue" 0;
BA_DEF_DEF_  "NetworkRequest" "No";
BA_DEF_DEF_  "NetworkRequestHoldingTime" 0;
BA_DEF_DEF_  "Description" "";
BA_DEF_DEF_  "Version" "";
BA_DEF_DEF_  "GenSigEnvVarType" "Undef";
BA_DEF_DEF_  "GenSigSendType" "NoSigSendType";
BA_DEF_DEF_  "GwSigLatencyTime" 40;
BA_DEF_DEF_  "GwSigMissingSourceType" "Undef";
BA_DEF_DEF_  "NWM-WakeupAllowed" "<n.a.>";
BA_DEF_DEF_  "RoutingFactor" 1;
BA_DEF_DEF_REL_ "GenSigTimeoutTime" 500;
BA_DEF_DEF_  "SystemSignalLongSymbol" "";
BA_ "GenMsgCycleTime" BO_ 2035 0;
BA_ "GenMsgCycleTimeFast" BO_ 2035 0;
BA_ "GenMsgNrOfRepetition" BO_ 2035 0;
BA_ "DiagRequest" BO_ 2035 1;
BA_ "GenMsgILSupport" BO_ 2035 0;
BA_ "TpMessage" BO_ 2035 1;
BA_ "TpTxIndex" BO_ 2035 263;
BA_ "GenMsgSendType" BO_ 952 0;
BA_ "GenMsgCycleTime" BO_ 2040 0;
BA_ "GenMsgCycleTimeFast" BO_ 2040 0;
BA_ "GenMsgNrOfRepetition" BO_ 2040 0;
BA_ "DiagResponse" BO_ 2040 1;
BA_ "GenMsgILSupport" BO_ 2040 0;
BA_ "TpMessage" BO_ 2040 1;
BA_ "TpTxIndex" BO_ 2040 260;
BA_ "GenMsgCycleTime" BO_ 2041 0;
BA_ "GenMsgCycleTimeFast" BO_ 2041 0;
BA_ "GenMsgNrOfRepetition" BO_ 2041 0;
BA_ "DiagResponse" BO_ 2041 1;
BA_ "GenMsgILSupport" BO_ 2041 0;
BA_ "TpMessage" BO_ 2041 1;
BA_ "TpTxIndex" BO_ 2041 261;
BA_ "GenMsgSendType" BO_ 950 0;
BA_ "GenMsgSendType" BO_ 951 0;
BA_ "GenMsgSendType" BO_ 2281835010 0;
BA_ "GenMsgCycleTime" BO_ 2281835010 100;
BA_ "GenMsgCycleTimeFast" BO_ 2281835010 0;
BA_ "GenMsgNrOfRepetition" BO_ 2281835010 0;
BA_ "VFrameFormat" BO_ 2281835010 1;
BA_ "GenMsgCycleTime" BO_ 2045 0;
BA_ "GenMsgCycleTimeFast" BO_ 2045 0;
BA_ "GenMsgNrOfRepetition" BO_ 2045 0;
BA_ "DiagResponse" BO_ 2045 1;
BA_ "GenMsgILSupport" BO_ 2045 0;
BA_ "TpMessage" BO_ 2045 1;
BA_ "TpTxIndex" BO_ 2045 262;
BA_ "GenMsgSendType" BO_ 2281835009 0;
BA_ "GenMsgCycleTime" BO_ 2281835009 100;
BA_ "GenMsgCycleTimeFast" BO_ 2281835009 0;
BA_ "GenMsgNrOfRepetition" BO_ 2281835009 0;
BA_ "VFrameFormat" BO_ 2281835009 1;
BA_ "GenMsgCycleTime" BO_ 2046 0;
BA_ "GenMsgCycleTimeFast" BO_ 2046 0;
BA_ "GenMsgNrOfRepetition" BO_ 2046 0;
BA_ "DiagResponse" BO_ 2046 1;
BA_ "GenMsgILSupport" BO_ 2046 0;
BA_ "TpMessage" BO_ 2046 1;
BA_ "TpTxIndex" BO_ 2046 263;
BA_ "GenMsgSendType" BO_ 2164279809 0;
BA_ "GenMsgCycleTime" BO_ 2164279809 50;
BA_ "GenMsgCycleTimeFast" BO_ 2164279809 0;
BA_ "GenMsgNrOfRepetition" BO_ 2164279809 0;
BA_ "VFrameFormat" BO_ 2164279809 1;
BA_ "GenMsgSendType" BO_ 2164279811 0;
BA_ "GenMsgCycleTime" BO_ 2164279811 50;
BA_ "GenMsgCycleTimeFast" BO_ 2164279811 0;
BA_ "GenMsgNrOfRepetition" BO_ 2164279811 0;
BA_ "VFrameFormat" BO_ 2164279811 1;
BA_ "GenMsgCycleTime" BO_ 942 0;
BA_ "GenMsgSendType" BO_ 2164279810 0;
BA_ "GenMsgCycleTime" BO_ 2164279810 50;
BA_ "GenMsgCycleTimeFast" BO_ 2164279810 0;
BA_ "GenMsgNrOfRepetition" BO_ 2164279810 0;
BA_ "VFrameFormat" BO_ 2164279810 1;
BA_ "GenMsgSendType" BO_ 2164279812 0;
BA_ "GenMsgCycleTime" BO_ 2164279812 50;
BA_ "GenMsgCycleTimeFast" BO_ 2164279812 0;
BA_ "GenMsgNrOfRepetition" BO_ 2164279812 0;
BA_ "VFrameFormat" BO_ 2164279812 1;
BA_ "GenMsgSendType" BO_ 939 0;
BA_ "GenMsgCycleTimeFast" BO_ 939 0;
BA_ "GenMsgNrOfRepetition" BO_ 939 0;
BA_ "GenMsgSendType" BO_ 2239851012 0;
BA_ "GenMsgCycleTime" BO_ 2239851012 100;
BA_ "GenMsgCycleTimeFast" BO_ 2239851012 0;
BA_ "GenMsgNrOfRepetition" BO_ 2239851012 0;
BA_ "VFrameFormat" BO_ 2239851012 1;
BA_ "GenMsgSendType" BO_ 934 0;
BA_ "GenMsgSendType" BO_ 2239851010 0;
BA_ "GenMsgCycleTime" BO_ 2239851010 100;
BA_ "GenMsgCycleTimeFast" BO_ 2239851010 0;
BA_ "GenMsgNrOfRepetition" BO_ 2239851010 0;
BA_ "VFrameFormat" BO_ 2239851010 1;
BA_ "GenMsgSendType" BO_ 929 0;
BA_ "GenMsgSendType" BO_ 2239851011 0;
BA_ "GenMsgCycleTime" BO_ 2239851011 100;
BA_ "GenMsgCycleTimeFast" BO_ 2239851011 0;
BA_ "GenMsgNrOfRepetition" BO_ 2239851011 0;
BA_ "VFrameFormat" BO_ 2239851011 1;
BA_ "GenMsgSendType" BO_ 2239851009 0;
BA_ "GenMsgCycleTime" BO_ 2239851009 100;
BA_ "GenMsgCycleTimeFast" BO_ 2239851009 0;
BA_ "GenMsgNrOfRepetition" BO_ 2239851009 0;
BA_ "VFrameFormat" BO_ 2239851009 1;
BA_ "GenMsgCycleTime" BO_ 924 0;
BA_ "GenMsgCycleTime" BO_ 922 0;
BA_ "GenMsgSendType" BO_ 2424580609 0;
BA_ "VFrameFormat" BO_ 2424580609 1;
BA_ "GenMsgCycleTime" BO_ 2015 0;
BA_ "GenMsgCycleTimeFast" BO_ 2015 0;
BA_ "GenMsgNrOfRepetition" BO_ 2015 0;
BA_ "DiagState" BO_ 2015 1;
BA_ "GenMsgILSupport" BO_ 2015 0;
BA_ "TpMessage" BO_ 2015 1;
BA_ "GenMsgSendType" BO_ 915 0;
BA_ "GenMsgSendType" BO_ 912 0;
BA_ "Description" SG_ 2035 GST_RLMSS_Byte0 "TP Index : 263";
BA_ "UsrSigPurpose" SG_ 2035 GST_RLMSS_Byte0 3;
BA_ "UserSigValidity" SG_ 2035 GST_RLMSS_Byte0 0;
BA_ "NetworkRequest" SG_ 2035 GST_RLMSS_Byte0 0;
BA_ "NetworkRequestHoldingTime" SG_ 2035 GST_RLMSS_Byte0 5000;
BA_ "Version" SG_ 2035 GST_RLMSS_Byte0 "22.04.02";
BA_ "Description" SG_ 2035 GST_RLMSS_Byte2 "TP Index : 263";
BA_ "UsrSigPurpose" SG_ 2035 GST_RLMSS_Byte2 3;
BA_ "UserSigValidity" SG_ 2035 GST_RLMSS_Byte2 0;
BA_ "NetworkRequest" SG_ 2035 GST_RLMSS_Byte2 0;
BA_ "NetworkRequestHoldingTime" SG_ 2035 GST_RLMSS_Byte2 5000;
BA_ "Version" SG_ 2035 GST_RLMSS_Byte2 "22.04.02";
BA_ "Description" SG_ 2035 GST_RLMSS_Byte3 "TP Index : 263";
BA_ "UsrSigPurpose" SG_ 2035 GST_RLMSS_Byte3 3;
BA_ "UserSigValidity" SG_ 2035 GST_RLMSS_Byte3 0;
BA_ "NetworkRequest" SG_ 2035 GST_RLMSS_Byte3 0;
BA_ "NetworkRequestHoldingTime" SG_ 2035 GST_RLMSS_Byte3 5000;
BA_ "Version" SG_ 2035 GST_RLMSS_Byte3 "22.04.02";
BA_ "Description" SG_ 2035 GST_RLMSS_Byte4 "TP Index : 263";
BA_ "UsrSigPurpose" SG_ 2035 GST_RLMSS_Byte4 3;
BA_ "UserSigValidity" SG_ 2035 GST_RLMSS_Byte4 0;
BA_ "NetworkRequest" SG_ 2035 GST_RLMSS_Byte4 0;
BA_ "NetworkRequestHoldingTime" SG_ 2035 GST_RLMSS_Byte4 5000;
BA_ "Version" SG_ 2035 GST_RLMSS_Byte4 "22.04.02";
BA_ "Description" SG_ 2035 GST_RLMSS_Byte5 "TP Index : 263";
BA_ "UsrSigPurpose" SG_ 2035 GST_RLMSS_Byte5 3;
BA_ "UserSigValidity" SG_ 2035 GST_RLMSS_Byte5 0;
BA_ "NetworkRequest" SG_ 2035 GST_RLMSS_Byte5 0;
BA_ "NetworkRequestHoldingTime" SG_ 2035 GST_RLMSS_Byte5 5000;
BA_ "Version" SG_ 2035 GST_RLMSS_Byte5 "22.04.02";
BA_ "Description" SG_ 2035 GST_RLMSS_Byte6 "TP Index : 263";
BA_ "UsrSigPurpose" SG_ 2035 GST_RLMSS_Byte6 3;
BA_ "UserSigValidity" SG_ 2035 GST_RLMSS_Byte6 0;
BA_ "NetworkRequest" SG_ 2035 GST_RLMSS_Byte6 0;
BA_ "NetworkRequestHoldingTime" SG_ 2035 GST_RLMSS_Byte6 5000;
BA_ "Version" SG_ 2035 GST_RLMSS_Byte6 "22.04.02";
BA_ "Description" SG_ 2035 GST_RLMSS_Byte7 "TP Index : 263";
BA_ "UsrSigPurpose" SG_ 2035 GST_RLMSS_Byte7 3;
BA_ "UserSigValidity" SG_ 2035 GST_RLMSS_Byte7 0;
BA_ "NetworkRequest" SG_ 2035 GST_RLMSS_Byte7 0;
BA_ "NetworkRequestHoldingTime" SG_ 2035 GST_RLMSS_Byte7 5000;
BA_ "Version" SG_ 2035 GST_RLMSS_Byte7 "22.04.02";
BA_ "Description" SG_ 2035 GST_RLMSS_Byte1 "TP Index : 263";
BA_ "UsrSigPurpose" SG_ 2035 GST_RLMSS_Byte1 3;
BA_ "UserSigValidity" SG_ 2035 GST_RLMSS_Byte1 0;
BA_ "NetworkRequest" SG_ 2035 GST_RLMSS_Byte1 0;
BA_ "NetworkRequestHoldingTime" SG_ 2035 GST_RLMSS_Byte1 5000;
BA_ "Version" SG_ 2035 GST_RLMSS_Byte1 "22.04.02";
BA_ "Description" SG_ 952 BLTN_CAM_Set_FR_Ver_Pos "Front Camera Vertical position setting value.";
BA_ "GenSigSendType" SG_ 952 BLTN_CAM_Set_FR_Ver_Pos 4;
BA_ "UserSigValidity" SG_ 952 BLTN_CAM_Set_FR_Ver_Pos 0;
BA_ "RoutingFactor" SG_ 952 BLTN_CAM_Set_FR_Ver_Pos 0;
BA_ "Version" SG_ 952 BLTN_CAM_Set_FR_Ver_Pos "22.07.06";
BA_ "Description" SG_ 952 BLTN_CAM_Set_PEV_AppNoti "Parked Event notification to Connectivity Phone App. On/Off";
BA_ "GenSigSendType" SG_ 952 BLTN_CAM_Set_PEV_AppNoti 4;
BA_ "UserSigValidity" SG_ 952 BLTN_CAM_Set_PEV_AppNoti 0;
BA_ "RoutingFactor" SG_ 952 BLTN_CAM_Set_PEV_AppNoti 0;
BA_ "Version" SG_ 952 BLTN_CAM_Set_PEV_AppNoti "21.05.02";
BA_ "Description" SG_ 952 BLTN_CAM_Set_WiFi_AutoOn "Wifi On/Off User setting";
BA_ "GenSigSendType" SG_ 952 BLTN_CAM_Set_WiFi_AutoOn 4;
BA_ "UserSigValidity" SG_ 952 BLTN_CAM_Set_WiFi_AutoOn 0;
BA_ "RoutingFactor" SG_ 952 BLTN_CAM_Set_WiFi_AutoOn 0;
BA_ "Version" SG_ 952 BLTN_CAM_Set_WiFi_AutoOn "21.05.02";
BA_ "Description" SG_ 952 BLTN_CAM_StrgPropSet "Propotion of built-in Cam SD card Propotion set of the Recording Categories";
BA_ "GenSigSendType" SG_ 952 BLTN_CAM_StrgPropSet 4;
BA_ "UserSigValidity" SG_ 952 BLTN_CAM_StrgPropSet 0;
BA_ "RoutingFactor" SG_ 952 BLTN_CAM_StrgPropSet 0;
BA_ "Version" SG_ 952 BLTN_CAM_StrgPropSet "21.05.02";
BA_ "Description" SG_ 952 BLTN_CAM_File_DEL_CPY_Op_State "Bulil in Cam Fily copy and delete operating state.";
BA_ "GenSigSendType" SG_ 952 BLTN_CAM_File_DEL_CPY_Op_State 4;
BA_ "UserSigValidity" SG_ 952 BLTN_CAM_File_DEL_CPY_Op_State 0;
BA_ "RoutingFactor" SG_ 952 BLTN_CAM_File_DEL_CPY_Op_State 0;
BA_ "Version" SG_ 952 BLTN_CAM_File_DEL_CPY_Op_State "21.05.02";
BA_ "Description" SG_ 952 BLTN_CAM_File_DEL_CPY_NumTot "Number of Copied or Deleted files.";
BA_ "GenSigSendType" SG_ 952 BLTN_CAM_File_DEL_CPY_NumTot 4;
BA_ "UserSigValidity" SG_ 952 BLTN_CAM_File_DEL_CPY_NumTot 0;
BA_ "RoutingFactor" SG_ 952 BLTN_CAM_File_DEL_CPY_NumTot 0;
BA_ "Version" SG_ 952 BLTN_CAM_File_DEL_CPY_NumTot "21.05.02";
BA_ "Description" SG_ 952 BLTN_CAM_File_DEL_CPYed_Num "Total number of the copy or delete file.";
BA_ "GenSigSendType" SG_ 952 BLTN_CAM_File_DEL_CPYed_Num 4;
BA_ "UserSigValidity" SG_ 952 BLTN_CAM_File_DEL_CPYed_Num 0;
BA_ "RoutingFactor" SG_ 952 BLTN_CAM_File_DEL_CPYed_Num 0;
BA_ "Version" SG_ 952 BLTN_CAM_File_DEL_CPYed_Num "21.05.02";
BA_ "Description" SG_ 952 BLTN_CAM_Set_RR_Ver_Pos "Rear Camera Vertical position setting value.";
BA_ "GenSigSendType" SG_ 952 BLTN_CAM_Set_RR_Ver_Pos 4;
BA_ "UserSigValidity" SG_ 952 BLTN_CAM_Set_RR_Ver_Pos 0;
BA_ "RoutingFactor" SG_ 952 BLTN_CAM_Set_RR_Ver_Pos 0;
BA_ "Version" SG_ 952 BLTN_CAM_Set_RR_Ver_Pos "22.07.06";
BA_ "Description" SG_ 2040 RRMSU_GST_Byte0 "TP Index : 260";
BA_ "UsrSigPurpose" SG_ 2040 RRMSU_GST_Byte0 4;
BA_ "UserSigValidity" SG_ 2040 RRMSU_GST_Byte0 0;
BA_ "Version" SG_ 2040 RRMSU_GST_Byte0 "22.04.02";
BA_ "Description" SG_ 2040 RRMSU_GST_Byte2 "TP Index : 260";
BA_ "UsrSigPurpose" SG_ 2040 RRMSU_GST_Byte2 4;
BA_ "UserSigValidity" SG_ 2040 RRMSU_GST_Byte2 0;
BA_ "Version" SG_ 2040 RRMSU_GST_Byte2 "22.04.02";
BA_ "Description" SG_ 2040 RRMSU_GST_Byte3 "TP Index : 260";
BA_ "UsrSigPurpose" SG_ 2040 RRMSU_GST_Byte3 4;
BA_ "UserSigValidity" SG_ 2040 RRMSU_GST_Byte3 0;
BA_ "Version" SG_ 2040 RRMSU_GST_Byte3 "22.04.02";
BA_ "Description" SG_ 2040 RRMSU_GST_Byte4 "TP Index : 260";
BA_ "UsrSigPurpose" SG_ 2040 RRMSU_GST_Byte4 4;
BA_ "UserSigValidity" SG_ 2040 RRMSU_GST_Byte4 0;
BA_ "Version" SG_ 2040 RRMSU_GST_Byte4 "22.04.02";
BA_ "Description" SG_ 2040 RRMSU_GST_Byte5 "TP Index : 260";
BA_ "UsrSigPurpose" SG_ 2040 RRMSU_GST_Byte5 4;
BA_ "UserSigValidity" SG_ 2040 RRMSU_GST_Byte5 0;
BA_ "Version" SG_ 2040 RRMSU_GST_Byte5 "22.04.02";
BA_ "Description" SG_ 2040 RRMSU_GST_Byte6 "TP Index : 260";
BA_ "UsrSigPurpose" SG_ 2040 RRMSU_GST_Byte6 4;
BA_ "UserSigValidity" SG_ 2040 RRMSU_GST_Byte6 0;
BA_ "Version" SG_ 2040 RRMSU_GST_Byte6 "22.04.02";
BA_ "Description" SG_ 2040 RRMSU_GST_Byte7 "TP Index : 260";
BA_ "UsrSigPurpose" SG_ 2040 RRMSU_GST_Byte7 4;
BA_ "UserSigValidity" SG_ 2040 RRMSU_GST_Byte7 0;
BA_ "Version" SG_ 2040 RRMSU_GST_Byte7 "22.04.02";
BA_ "Description" SG_ 2040 RRMSU_GST_Byte1 "TP Index : 260";
BA_ "UsrSigPurpose" SG_ 2040 RRMSU_GST_Byte1 4;
BA_ "UserSigValidity" SG_ 2040 RRMSU_GST_Byte1 0;
BA_ "Version" SG_ 2040 RRMSU_GST_Byte1 "22.04.02";
BA_ "Description" SG_ 2041 RRMSS_GST_Byte0 "TP Index : 261";
BA_ "UsrSigPurpose" SG_ 2041 RRMSS_GST_Byte0 4;
BA_ "UserSigValidity" SG_ 2041 RRMSS_GST_Byte0 0;
BA_ "Version" SG_ 2041 RRMSS_GST_Byte0 "22.04.02";
BA_ "Description" SG_ 2041 RRMSS_GST_Byte2 "TP Index : 261";
BA_ "UsrSigPurpose" SG_ 2041 RRMSS_GST_Byte2 4;
BA_ "UserSigValidity" SG_ 2041 RRMSS_GST_Byte2 0;
BA_ "Version" SG_ 2041 RRMSS_GST_Byte2 "22.04.02";
BA_ "Description" SG_ 2041 RRMSS_GST_Byte3 "TP Index : 261";
BA_ "UsrSigPurpose" SG_ 2041 RRMSS_GST_Byte3 4;
BA_ "UserSigValidity" SG_ 2041 RRMSS_GST_Byte3 0;
BA_ "Version" SG_ 2041 RRMSS_GST_Byte3 "22.04.02";
BA_ "Description" SG_ 2041 RRMSS_GST_Byte4 "TP Index : 261";
BA_ "UsrSigPurpose" SG_ 2041 RRMSS_GST_Byte4 4;
BA_ "UserSigValidity" SG_ 2041 RRMSS_GST_Byte4 0;
BA_ "Version" SG_ 2041 RRMSS_GST_Byte4 "22.04.02";
BA_ "Description" SG_ 2041 RRMSS_GST_Byte5 "TP Index : 261";
BA_ "UsrSigPurpose" SG_ 2041 RRMSS_GST_Byte5 4;
BA_ "UserSigValidity" SG_ 2041 RRMSS_GST_Byte5 0;
BA_ "Version" SG_ 2041 RRMSS_GST_Byte5 "22.04.02";
BA_ "Description" SG_ 2041 RRMSS_GST_Byte6 "TP Index : 261";
BA_ "UsrSigPurpose" SG_ 2041 RRMSS_GST_Byte6 4;
BA_ "UserSigValidity" SG_ 2041 RRMSS_GST_Byte6 0;
BA_ "Version" SG_ 2041 RRMSS_GST_Byte6 "22.04.02";
BA_ "Description" SG_ 2041 RRMSS_GST_Byte7 "TP Index : 261";
BA_ "UsrSigPurpose" SG_ 2041 RRMSS_GST_Byte7 4;
BA_ "UserSigValidity" SG_ 2041 RRMSS_GST_Byte7 0;
BA_ "Version" SG_ 2041 RRMSS_GST_Byte7 "22.04.02";
BA_ "Description" SG_ 2041 RRMSS_GST_Byte1 "TP Index : 261";
BA_ "UsrSigPurpose" SG_ 2041 RRMSS_GST_Byte1 4;
BA_ "UserSigValidity" SG_ 2041 RRMSS_GST_Byte1 0;
BA_ "Version" SG_ 2041 RRMSS_GST_Byte1 "22.04.02";
BA_ "Description" SG_ 950 BLTN_CAM_State "This Signal is for cluster warning popup.";
BA_ "UsrSigPurpose" SG_ 950 BLTN_CAM_State 0;
BA_ "GenSigSendType" SG_ 950 BLTN_CAM_State 4;
BA_ "UserSigValidity" SG_ 950 BLTN_CAM_State 1;
BA_ "RoutingFactor" SG_ 950 BLTN_CAM_State 0;
BA_ "Version" SG_ 950 BLTN_CAM_State "21.05.02";
BA_ "Description" SG_ 950 BLTN_CAM_RecSta_DEV "This Signal inform recording status of Driving Event.";
BA_ "UsrSigPurpose" SG_ 950 BLTN_CAM_RecSta_DEV 0;
BA_ "GenSigSendType" SG_ 950 BLTN_CAM_RecSta_DEV 4;
BA_ "UserSigValidity" SG_ 950 BLTN_CAM_RecSta_DEV 1;
BA_ "RoutingFactor" SG_ 950 BLTN_CAM_RecSta_DEV 0;
BA_ "Version" SG_ 950 BLTN_CAM_RecSta_DEV "21.05.02";
BA_ "Description" SG_ 950 BLTN_CAM_RecSta_MAR "This Signal inform recording status of Manual Recording.";
BA_ "UsrSigPurpose" SG_ 950 BLTN_CAM_RecSta_MAR 0;
BA_ "GenSigSendType" SG_ 950 BLTN_CAM_RecSta_MAR 4;
BA_ "UserSigValidity" SG_ 950 BLTN_CAM_RecSta_MAR 1;
BA_ "RoutingFactor" SG_ 950 BLTN_CAM_RecSta_MAR 0;
BA_ "Version" SG_ 950 BLTN_CAM_RecSta_MAR "21.05.02";
BA_ "Description" SG_ 950 BLTN_CAM_RecSta_TML "This Signal inform recording status of Time-lapse.";
BA_ "UsrSigPurpose" SG_ 950 BLTN_CAM_RecSta_TML 0;
BA_ "GenSigSendType" SG_ 950 BLTN_CAM_RecSta_TML 4;
BA_ "UserSigValidity" SG_ 950 BLTN_CAM_RecSta_TML 1;
BA_ "RoutingFactor" SG_ 950 BLTN_CAM_RecSta_TML 0;
BA_ "Version" SG_ 950 BLTN_CAM_RecSta_TML "21.05.02";
BA_ "Description" SG_ 950 BLTN_CAM_RecSta_OWP "This Signal inform recording status of On While Parked.";
BA_ "UsrSigPurpose" SG_ 950 BLTN_CAM_RecSta_OWP 0;
BA_ "GenSigSendType" SG_ 950 BLTN_CAM_RecSta_OWP 4;
BA_ "UserSigValidity" SG_ 950 BLTN_CAM_RecSta_OWP 1;
BA_ "RoutingFactor" SG_ 950 BLTN_CAM_RecSta_OWP 0;
BA_ "Version" SG_ 950 BLTN_CAM_RecSta_OWP "21.05.02";
BA_ "Description" SG_ 950 BLTN_CAM_RecSta_PEV "This Signal inform recording status of Parked Event.";
BA_ "UsrSigPurpose" SG_ 950 BLTN_CAM_RecSta_PEV 0;
BA_ "GenSigSendType" SG_ 950 BLTN_CAM_RecSta_PEV 4;
BA_ "UserSigValidity" SG_ 950 BLTN_CAM_RecSta_PEV 1;
BA_ "RoutingFactor" SG_ 950 BLTN_CAM_RecSta_PEV 0;
BA_ "Version" SG_ 950 BLTN_CAM_RecSta_PEV "21.05.02";
BA_ "Description" SG_ 950 BLTN_CAM_Prk_EV_Cnt "The count number of a parked Event.";
BA_ "UsrSigPurpose" SG_ 950 BLTN_CAM_Prk_EV_Cnt 0;
BA_ "GenSigSendType" SG_ 950 BLTN_CAM_Prk_EV_Cnt 4;
BA_ "UserSigValidity" SG_ 950 BLTN_CAM_Prk_EV_Cnt 1;
BA_ "RoutingFactor" SG_ 950 BLTN_CAM_Prk_EV_Cnt 0;
BA_ "Version" SG_ 950 BLTN_CAM_Prk_EV_Cnt "21.05.02";
BA_ "Description" SG_ 950 BLTN_CAM_Prk_Oped_Time "The Parked Opreated time ingormation";
BA_ "UsrSigPurpose" SG_ 950 BLTN_CAM_Prk_Oped_Time 0;
BA_ "GenSigSendType" SG_ 950 BLTN_CAM_Prk_Oped_Time 4;
BA_ "UserSigValidity" SG_ 950 BLTN_CAM_Prk_Oped_Time 1;
BA_ "RoutingFactor" SG_ 950 BLTN_CAM_Prk_Oped_Time 0;
BA_ "Version" SG_ 950 BLTN_CAM_Prk_Oped_Time "22.07.05";
BA_ "Description" SG_ 950 BLTN_CAM_Prk_Oprable_Time "The hours of Park Mode Operatable, the time is limited by user max oper. Set.";
BA_ "UsrSigPurpose" SG_ 950 BLTN_CAM_Prk_Oprable_Time 0;
BA_ "GenSigSendType" SG_ 950 BLTN_CAM_Prk_Oprable_Time 4;
BA_ "UserSigValidity" SG_ 950 BLTN_CAM_Prk_Oprable_Time 1;
BA_ "RoutingFactor" SG_ 950 BLTN_CAM_Prk_Oprable_Time 0;
BA_ "Version" SG_ 950 BLTN_CAM_Prk_Oprable_Time "22.07.05";
BA_ "Description" SG_ 950 BLTN_CAM_SD_Card_State "This Signal is for SD card Status in Built-in App menu and CCS Phone App.";
BA_ "UsrSigPurpose" SG_ 950 BLTN_CAM_SD_Card_State 0;
BA_ "GenSigSendType" SG_ 950 BLTN_CAM_SD_Card_State 4;
BA_ "UserSigValidity" SG_ 950 BLTN_CAM_SD_Card_State 0;
BA_ "NetworkRequest" SG_ 950 BLTN_CAM_SD_Card_State 0;
BA_ "NetworkRequestHoldingTime" SG_ 950 BLTN_CAM_SD_Card_State 1000;
BA_ "RoutingFactor" SG_ 950 BLTN_CAM_SD_Card_State 0;
BA_ "Version" SG_ 950 BLTN_CAM_SD_Card_State "22.05.02";
BA_ "Description" SG_ 950 BLTN_CAM_Prk_Oprable_Time_Max "The hours of Park Mode Operatable, the time has no limit.";
BA_ "UsrSigPurpose" SG_ 950 BLTN_CAM_Prk_Oprable_Time_Max 0;
BA_ "GenSigSendType" SG_ 950 BLTN_CAM_Prk_Oprable_Time_Max 4;
BA_ "UserSigValidity" SG_ 950 BLTN_CAM_Prk_Oprable_Time_Max 1;
BA_ "RoutingFactor" SG_ 950 BLTN_CAM_Prk_Oprable_Time_Max 0;
BA_ "Version" SG_ 950 BLTN_CAM_Prk_Oprable_Time_Max "22.07.05";
BA_ "Description" SG_ 950 BLTN_CAM_AuxBat_Conn_State "The auxiliary Battery conntction information.";
BA_ "UsrSigPurpose" SG_ 950 BLTN_CAM_AuxBat_Conn_State 0;
BA_ "GenSigSendType" SG_ 950 BLTN_CAM_AuxBat_Conn_State 4;
BA_ "UserSigValidity" SG_ 950 BLTN_CAM_AuxBat_Conn_State 0;
BA_ "RoutingFactor" SG_ 950 BLTN_CAM_AuxBat_Conn_State 0;
BA_ "Version" SG_ 950 BLTN_CAM_AuxBat_Conn_State "21.07.04";
BA_ "Description" SG_ 950 BLTN_CAM_AuxBat_CapPer "The percentage of Aux. Bat.";
BA_ "UsrSigPurpose" SG_ 950 BLTN_CAM_AuxBat_CapPer 0;
BA_ "GenSigSendType" SG_ 950 BLTN_CAM_AuxBat_CapPer 4;
BA_ "UserSigValidity" SG_ 950 BLTN_CAM_AuxBat_CapPer 1;
BA_ "RoutingFactor" SG_ 950 BLTN_CAM_AuxBat_CapPer 0;
BA_ "Version" SG_ 950 BLTN_CAM_AuxBat_CapPer "21.05.02";
BA_ "Description" SG_ 950 BLTN_CAM_RecSta_OWD "This Signal inform recording status of On While Driving.";
BA_ "UsrSigPurpose" SG_ 950 BLTN_CAM_RecSta_OWD 0;
BA_ "GenSigSendType" SG_ 950 BLTN_CAM_RecSta_OWD 4;
BA_ "UserSigValidity" SG_ 950 BLTN_CAM_RecSta_OWD 1;
BA_ "RoutingFactor" SG_ 950 BLTN_CAM_RecSta_OWD 0;
BA_ "Version" SG_ 950 BLTN_CAM_RecSta_OWD "21.05.02";
BA_ "Description" SG_ 951 BLTN_CAM_RecSet_OWD "Record On/Off Set of On While Driving";
BA_ "GenSigSendType" SG_ 951 BLTN_CAM_RecSet_OWD 4;
BA_ "UserSigValidity" SG_ 951 BLTN_CAM_RecSet_OWD 0;
BA_ "Version" SG_ 951 BLTN_CAM_RecSet_OWD "21.05.02";
BA_ "Description" SG_ 951 BLTN_CAM_Set_Tim_Stm "Record Set of Date and Time Stamp";
BA_ "GenSigSendType" SG_ 951 BLTN_CAM_Set_Tim_Stm 4;
BA_ "UserSigValidity" SG_ 951 BLTN_CAM_Set_Tim_Stm 0;
BA_ "Version" SG_ 951 BLTN_CAM_Set_Tim_Stm "21.05.02";
BA_ "Description" SG_ 951 BLTN_CAM_Set_Spd_Stm "Record Set of Speed Stamp";
BA_ "GenSigSendType" SG_ 951 BLTN_CAM_Set_Spd_Stm 4;
BA_ "UserSigValidity" SG_ 951 BLTN_CAM_Set_Spd_Stm 0;
BA_ "Version" SG_ 951 BLTN_CAM_Set_Spd_Stm "21.11.07";
BA_ "Description" SG_ 951 BLTN_CAM_Set_Locatn_Stm "Record Set of Location Stamp";
BA_ "GenSigSendType" SG_ 951 BLTN_CAM_Set_Locatn_Stm 4;
BA_ "UserSigValidity" SG_ 951 BLTN_CAM_Set_Locatn_Stm 0;
BA_ "Version" SG_ 951 BLTN_CAM_Set_Locatn_Stm "21.05.02";
BA_ "Description" SG_ 951 BLTN_CAM_Set_TrnSig_Stm "Record Set of Turn Signal Stamp";
BA_ "GenSigSendType" SG_ 951 BLTN_CAM_Set_TrnSig_Stm 4;
BA_ "UserSigValidity" SG_ 951 BLTN_CAM_Set_TrnSig_Stm 0;
BA_ "Version" SG_ 951 BLTN_CAM_Set_TrnSig_Stm "21.05.02";
BA_ "Description" SG_ 951 BLTN_CAM_Set_AclBrk_Stm "Record Set of Accelerator Brake Stamp";
BA_ "GenSigSendType" SG_ 951 BLTN_CAM_Set_AclBrk_Stm 4;
BA_ "UserSigValidity" SG_ 951 BLTN_CAM_Set_AclBrk_Stm 0;
BA_ "Version" SG_ 951 BLTN_CAM_Set_AclBrk_Stm "21.11.07";
BA_ "Description" SG_ 951 BLTN_CAM_RecSet_DEV "Record On/Off Set of Driving Event";
BA_ "GenSigSendType" SG_ 951 BLTN_CAM_RecSet_DEV 4;
BA_ "UserSigValidity" SG_ 951 BLTN_CAM_RecSet_DEV 0;
BA_ "Version" SG_ 951 BLTN_CAM_RecSet_DEV "21.05.02";
BA_ "Description" SG_ 951 BLTN_CAM_Set_GearPos_Stm "Record Set of Gear Position Stamp";
BA_ "GenSigSendType" SG_ 951 BLTN_CAM_Set_GearPos_Stm 4;
BA_ "UserSigValidity" SG_ 951 BLTN_CAM_Set_GearPos_Stm 0;
BA_ "Version" SG_ 951 BLTN_CAM_Set_GearPos_Stm "21.05.02";
BA_ "Description" SG_ 951 BLTN_CAM_Set_EVSen_Stm "Record Set of Event Sensitivity Stamp";
BA_ "GenSigSendType" SG_ 951 BLTN_CAM_Set_EVSen_Stm 4;
BA_ "UserSigValidity" SG_ 951 BLTN_CAM_Set_EVSen_Stm 0;
BA_ "Version" SG_ 951 BLTN_CAM_Set_EVSen_Stm "21.05.02";
BA_ "Description" SG_ 951 BLTN_CAM_Set_StrAngl_Stm "Record Set of Steering Angle Stamp";
BA_ "GenSigSendType" SG_ 951 BLTN_CAM_Set_StrAngl_Stm 4;
BA_ "UserSigValidity" SG_ 951 BLTN_CAM_Set_StrAngl_Stm 0;
BA_ "Version" SG_ 951 BLTN_CAM_Set_StrAngl_Stm "21.07.05";
BA_ "Description" SG_ 951 BLTN_CAM_Set_PrkTime "Parking Operation Setting Time, Resolution : hr";
BA_ "GenSigSendType" SG_ 951 BLTN_CAM_Set_PrkTime 4;
BA_ "UserSigValidity" SG_ 951 BLTN_CAM_Set_PrkTime 0;
BA_ "Version" SG_ 951 BLTN_CAM_Set_PrkTime "21.11.07";
BA_ "Description" SG_ 951 BLTN_CAM_Set_EV_BfrTime "Driving Event Time Setting - Before, Resolution : sec";
BA_ "GenSigSendType" SG_ 951 BLTN_CAM_Set_EV_BfrTime 4;
BA_ "UserSigValidity" SG_ 951 BLTN_CAM_Set_EV_BfrTime 0;
BA_ "Version" SG_ 951 BLTN_CAM_Set_EV_BfrTime "21.05.02";
BA_ "Description" SG_ 951 BLTN_CAM_RecSet_OWP "Record On/Off Set of On While Parked, 0x0(Default) : Parking recording function not supported";
BA_ "GenSigSendType" SG_ 951 BLTN_CAM_RecSet_OWP 4;
BA_ "UserSigValidity" SG_ 951 BLTN_CAM_RecSet_OWP 0;
BA_ "Version" SG_ 951 BLTN_CAM_RecSet_OWP "21.05.02";
BA_ "Description" SG_ 951 BLTN_CAM_Set_EV_AftTime "Driving Event Time Setting - After, Resolution : sec";
BA_ "GenSigSendType" SG_ 951 BLTN_CAM_Set_EV_AftTime 4;
BA_ "UserSigValidity" SG_ 951 BLTN_CAM_Set_EV_AftTime 0;
BA_ "Version" SG_ 951 BLTN_CAM_Set_EV_AftTime "21.05.02";
BA_ "Description" SG_ 951 BLTN_CAM_Set_Drv_TML_Int "Record Set of Time-lapse Interval, Resolution : sec";
BA_ "GenSigSendType" SG_ 951 BLTN_CAM_Set_Drv_TML_Int 4;
BA_ "UserSigValidity" SG_ 951 BLTN_CAM_Set_Drv_TML_Int 0;
BA_ "Version" SG_ 951 BLTN_CAM_Set_Drv_TML_Int "21.05.02";
BA_ "Description" SG_ 951 BLTN_CAM_SenSet_DEV "Set of Event  Detection Sensitivity of Driving Mode";
BA_ "GenSigSendType" SG_ 951 BLTN_CAM_SenSet_DEV 4;
BA_ "UserSigValidity" SG_ 951 BLTN_CAM_SenSet_DEV 0;
BA_ "Version" SG_ 951 BLTN_CAM_SenSet_DEV "21.05.02";
BA_ "Description" SG_ 951 BLTN_CAM_SenSet_PEV "Set of Event  Detection Sensitivity of Parking Mode";
BA_ "GenSigSendType" SG_ 951 BLTN_CAM_SenSet_PEV 4;
BA_ "UserSigValidity" SG_ 951 BLTN_CAM_SenSet_PEV 0;
BA_ "Version" SG_ 951 BLTN_CAM_SenSet_PEV "21.05.02";
BA_ "Description" SG_ 951 BLTN_CAM_RecSet_PEV "Record Set of Parked Event, 0x0(Default) : Parking recording function not supported";
BA_ "GenSigSendType" SG_ 951 BLTN_CAM_RecSet_PEV 4;
BA_ "UserSigValidity" SG_ 951 BLTN_CAM_RecSet_PEV 0;
BA_ "Version" SG_ 951 BLTN_CAM_RecSet_PEV "21.05.02";
BA_ "Description" SG_ 951 BLTN_CAM_AudRec_Set "Audio Record On/Off Set";
BA_ "GenSigSendType" SG_ 951 BLTN_CAM_AudRec_Set 4;
BA_ "UserSigValidity" SG_ 951 BLTN_CAM_AudRec_Set 0;
BA_ "Version" SG_ 951 BLTN_CAM_AudRec_Set "21.05.02";
BA_ "Description" SG_ 2281835010 ACU_ActvFltSta "This signal means information regarding fault status, whether it is an active fault or not.



1) Default value : 0x2

2) Default value Transmit condition

    - When the input condition is not supported.";
BA_ "GenSigStartValue" SG_ 2281835010 ACU_ActvFltSta 2;
BA_ "UserSigValidity" SG_ 2281835010 ACU_ActvFltSta 3;
BA_ "Version" SG_ 2281835010 ACU_ActvFltSta "17.12.00";
BA_ "Description" SG_ 2281835010 ACU_NumOfEvtTrigVal "This signal is incremented by one each time when ACU meet EDR trigger condition

The last value is kept in the next cycle.



1) Value in EOL : always 0x0";
BA_ "UserSigValidity" SG_ 2281835010 ACU_NumOfEvtTrigVal 3;
BA_ "Version" SG_ 2281835010 ACU_NumOfEvtTrigVal "18.04.00";
BA_ "Description" SG_ 2281835010 ACU_SdArbgExtTyp "This signal does not specify the types or variations of the side restraints such as the front side airbag only or both the front and the rear side airbag. If any side restraint is equipped, the signal responds as 'exists'.

¡ØInitial value shall be actua";
BA_ "UserSigValidity" SG_ 2281835010 ACU_SdArbgExtTyp 3;
BA_ "Version" SG_ 2281835010 ACU_SdArbgExtTyp "19.07.06";
BA_ "Description" SG_ 2281835010 ACU_PassArbg_SW_Sta "This signal indicates that the state of passenger airbag on/off switch

¡ØBefore EOL : 0x0(NOT APPLIED) transmit,    (Default value : 0x0)";
BA_ "UserSigValidity" SG_ 2281835010 ACU_PassArbg_SW_Sta 3;
BA_ "Version" SG_ 2281835010 ACU_PassArbg_SW_Sta "20.08.07";
BA_ "Description" SG_ 2281835010 ACU_HDPSpprtSWVer "This signal means the software version information of signals related to HDP cooperative control.

If the ACU signal related to HDP cooperative control is modified, this signal is changed.

0x0 : Not Support(intit)

After IGN On, 0x0 is transmitted in th";
BA_ "UserSigValidity" SG_ 2281835010 ACU_HDPSpprtSWVer 3;
BA_ "Version" SG_ 2281835010 ACU_HDPSpprtSWVer "21.12.07";
BA_ "Description" SG_ 2281835010 ACU_EmerModSta "This signal is set when  ACU detect Emergency mode status 

 (e.g : During driving, IGN1+ is disconnected)  

1)Value in EOL :  always 0x0 

2)Emergency mode details in ES95910-02";
BA_ "UserSigValidity" SG_ 2281835010 ACU_EmerModSta 3;
BA_ "Version" SG_ 2281835010 ACU_EmerModSta "18.04.00";
BA_ "Description" SG_ 2281835010 ACU_EvtTrigSta "This signal is set when  ACU meet EDR trigger condition.

Event trigger condition is same as EDR Regulation definition(49 CFR PART 563)

This signal is set to '1'  then kept for the current IGN cycle as '1'



1)Value in EOL :  always 0x0";
BA_ "UserSigValidity" SG_ 2281835010 ACU_EvtTrigSta 3;
BA_ "Version" SG_ 2281835010 ACU_EvtTrigSta "18.04.00";
BA_ "Description" SG_ 2281835010 ACU_NumOfEmerModVal "This signal is incremented by one each time when ACU enters into emergency mode.

The last value is kept in the next cycle.



1) Value in EOL : always 0x0

2)Emergency mode details in ES95910-02";
BA_ "UserSigValidity" SG_ 2281835010 ACU_NumOfEmerModVal 3;
BA_ "Version" SG_ 2281835010 ACU_NumOfEmerModVal "18.04.00";
BA_ "Description" SG_ 2045 RLMSU_GST_Byte0 "TP Index : 262";
BA_ "UsrSigPurpose" SG_ 2045 RLMSU_GST_Byte0 4;
BA_ "UserSigValidity" SG_ 2045 RLMSU_GST_Byte0 0;
BA_ "Version" SG_ 2045 RLMSU_GST_Byte0 "22.04.02";
BA_ "Description" SG_ 2045 RLMSU_GST_Byte2 "TP Index : 262";
BA_ "UsrSigPurpose" SG_ 2045 RLMSU_GST_Byte2 4;
BA_ "UserSigValidity" SG_ 2045 RLMSU_GST_Byte2 0;
BA_ "Version" SG_ 2045 RLMSU_GST_Byte2 "22.04.02";
BA_ "Description" SG_ 2045 RLMSU_GST_Byte3 "TP Index : 262";
BA_ "UsrSigPurpose" SG_ 2045 RLMSU_GST_Byte3 4;
BA_ "UserSigValidity" SG_ 2045 RLMSU_GST_Byte3 0;
BA_ "Version" SG_ 2045 RLMSU_GST_Byte3 "22.04.02";
BA_ "Description" SG_ 2045 RLMSU_GST_Byte4 "TP Index : 262";
BA_ "UsrSigPurpose" SG_ 2045 RLMSU_GST_Byte4 4;
BA_ "UserSigValidity" SG_ 2045 RLMSU_GST_Byte4 0;
BA_ "Version" SG_ 2045 RLMSU_GST_Byte4 "22.04.02";
BA_ "Description" SG_ 2045 RLMSU_GST_Byte5 "TP Index : 262";
BA_ "UsrSigPurpose" SG_ 2045 RLMSU_GST_Byte5 4;
BA_ "UserSigValidity" SG_ 2045 RLMSU_GST_Byte5 0;
BA_ "Version" SG_ 2045 RLMSU_GST_Byte5 "22.04.02";
BA_ "Description" SG_ 2045 RLMSU_GST_Byte6 "TP Index : 262";
BA_ "UsrSigPurpose" SG_ 2045 RLMSU_GST_Byte6 4;
BA_ "UserSigValidity" SG_ 2045 RLMSU_GST_Byte6 0;
BA_ "Version" SG_ 2045 RLMSU_GST_Byte6 "22.04.02";
BA_ "Description" SG_ 2045 RLMSU_GST_Byte7 "TP Index : 262";
BA_ "UsrSigPurpose" SG_ 2045 RLMSU_GST_Byte7 4;
BA_ "UserSigValidity" SG_ 2045 RLMSU_GST_Byte7 0;
BA_ "Version" SG_ 2045 RLMSU_GST_Byte7 "22.04.02";
BA_ "Description" SG_ 2045 RLMSU_GST_Byte1 "TP Index : 262";
BA_ "UsrSigPurpose" SG_ 2045 RLMSU_GST_Byte1 4;
BA_ "UserSigValidity" SG_ 2045 RLMSU_GST_Byte1 0;
BA_ "Version" SG_ 2045 RLMSU_GST_Byte1 "22.04.02";
BA_ "Description" SG_ 2281835009 ACU_Crc1Val "The data area for CRC calculation is based on the data length (DLC) of the message DB.

The CRC shall be calculated over the entire data block (excluding the CRC bytes) including the user data, alive counter and Data ID



- CRC Polynomial (0x1021) , Ini";
BA_ "GenSigStartValue" SG_ 2281835009 ACU_Crc1Val 65535;
BA_ "UserSigValidity" SG_ 2281835009 ACU_Crc1Val 3;
BA_ "Version" SG_ 2281835009 ACU_Crc1Val "21.09.03";
BA_ "Description" SG_ 2281835009 ACU_AlvCnt1Val "For the first transmission request for a data element the counter shall be initialized with 0 and shall be incremented by 1 for every subsequent send request. 

When the counter reaches the maximum value(0xFF), then it shall restart with 0 for the next s";
BA_ "UserSigValidity" SG_ 2281835009 ACU_AlvCnt1Val 3;
BA_ "Version" SG_ 2281835009 ACU_AlvCnt1Val "21.09.03";
BA_ "Description" SG_ 2281835009 ACU_SysWrngLmpDis "This signal means information regarding ACU diagnostic information result & discrimination.



1) Default value : 0x1

2) Default value Transmit condition

    - When the input condition is not determined.

    - When the input condition is not supported";
BA_ "GenSigStartValue" SG_ 2281835009 ACU_SysWrngLmpDis 1;
BA_ "UserSigValidity" SG_ 2281835009 ACU_SysWrngLmpDis 3;
BA_ "Version" SG_ 2281835009 ACU_SysWrngLmpDis "18.11.05";
BA_ "Description" SG_ 2281835009 ACU_TlltlLmpDis "This signal means information regarding Occupant status.

0) 00Xb : X position means PAB OFF Lamp indication. When this bit set as 1 PAB OFF lamp turns ON. 

    0Y0b : Y position means PAB ON Lamp indication. When this bit set as 1 PAB ON lamp turns ON.";
BA_ "GenSigStartValue" SG_ 2281835009 ACU_TlltlLmpDis 3;
BA_ "UserSigValidity" SG_ 2281835009 ACU_TlltlLmpDis 3;
BA_ "Version" SG_ 2281835009 ACU_TlltlLmpDis "20.03.02";
BA_ "Description" SG_ 2281835009 ACU_OdsIDReq "It s a Request to send ODS Identifier. If the Bit is equal to `0` the ODS-B module will transmit the ODS identifier message. ACU sets ¡°ODS ID Received¡± to ¡®1¡¯ after getting the valid ODS ID two times.



1) Default value : 0x0

2) Default value Trans";
BA_ "UserSigValidity" SG_ 2281835009 ACU_OdsIDReq 3;
BA_ "Version" SG_ 2281835009 ACU_OdsIDReq "17.12.00";
BA_ "Description" SG_ 2281835009 SeatBelt_PassBcklFltSta "Information of Passenger Seat Belt Buckle switch Fault condition.



1) Default value : 0x0

2) Default value Transmit condition

    - When the input condition is not supported.

¡ØThis signal is valid (updated) only that buckle is connected to ACU dire";
BA_ "UserSigValidity" SG_ 2281835009 SeatBelt_PassBcklFltSta 3;
BA_ "Version" SG_ 2281835009 SeatBelt_PassBcklFltSta "19.01.08";
BA_ "Description" SG_ 2281835009 SeatBelt_DrvrBcklFltSta "Information of Driver Seat Belt Buckle switch Fault condition.



1) Default value : 0x0

2) Default value Transmit condition

    - When the input condition is not supported.

¡ØThis signal is valid (updated) only that buckle is connected to ACU directl";
BA_ "UserSigValidity" SG_ 2281835009 SeatBelt_DrvrBcklFltSta 3;
BA_ "Version" SG_ 2281835009 SeatBelt_DrvrBcklFltSta "19.01.08";
BA_ "Description" SG_ 2281835009 SeatBelt_PassBcklSta "Information of Passenger Seat Belt Buckle switch Status, whether its Latched or Not .



1) Default value : 0x1

2) Default value Transmit condition

    - When the input condition is not determined.

    - When the input condition is not supported.

¡ØT";
BA_ "GenSigStartValue" SG_ 2281835009 SeatBelt_PassBcklSta 1;
BA_ "UserSigValidity" SG_ 2281835009 SeatBelt_PassBcklSta 3;
BA_ "Version" SG_ 2281835009 SeatBelt_PassBcklSta "19.01.08";
BA_ "Description" SG_ 2281835009 SeatBelt_DrvrBcklSta "Information of Driver Seat Belt Buckle switch Status, whether its Latched or Not.



1) Default value : 0x1

2) Default value Transmit condition

    - When the input condition is not determined.

    - When the input condition is not supported.

¡ØThis ";
BA_ "GenSigStartValue" SG_ 2281835009 SeatBelt_DrvrBcklSta 1;
BA_ "UserSigValidity" SG_ 2281835009 SeatBelt_DrvrBcklSta 3;
BA_ "Version" SG_ 2281835009 SeatBelt_DrvrBcklSta "19.01.08";
BA_ "Description" SG_ 2281835009 ACU_DiagTrblCodVal "This signal means information regarding a diagnostic trouble code number.



1) Default value : 0x0

2) Default value Transmit condition

    - When Fault does not exist.";
BA_ "UserSigValidity" SG_ 2281835009 ACU_DiagTrblCodVal 3;
BA_ "Version" SG_ 2281835009 ACU_DiagTrblCodVal "17.12.00";
BA_ "Description" SG_ 2281835009 ACU_FltNumVal "This signal means information regarding number of fault in ACU memory, including active and historic faults.



1) Default value : 0x0

2) Default value Transmit condition

    - When Fault does not exist.";
BA_ "UserSigValidity" SG_ 2281835009 ACU_FltNumVal 3;
BA_ "Version" SG_ 2281835009 ACU_FltNumVal "17.12.00";
BA_ "Description" SG_ 2046 RLMSS_GST_Byte0 "TP Index : 263";
BA_ "UsrSigPurpose" SG_ 2046 RLMSS_GST_Byte0 4;
BA_ "UserSigValidity" SG_ 2046 RLMSS_GST_Byte0 0;
BA_ "Version" SG_ 2046 RLMSS_GST_Byte0 "22.04.02";
BA_ "Description" SG_ 2046 RLMSS_GST_Byte2 "TP Index : 263";
BA_ "UsrSigPurpose" SG_ 2046 RLMSS_GST_Byte2 4;
BA_ "UserSigValidity" SG_ 2046 RLMSS_GST_Byte2 0;
BA_ "Version" SG_ 2046 RLMSS_GST_Byte2 "22.04.02";
BA_ "Description" SG_ 2046 RLMSS_GST_Byte3 "TP Index : 263";
BA_ "UsrSigPurpose" SG_ 2046 RLMSS_GST_Byte3 4;
BA_ "UserSigValidity" SG_ 2046 RLMSS_GST_Byte3 0;
BA_ "Version" SG_ 2046 RLMSS_GST_Byte3 "22.04.02";
BA_ "Description" SG_ 2046 RLMSS_GST_Byte4 "TP Index : 263";
BA_ "UsrSigPurpose" SG_ 2046 RLMSS_GST_Byte4 4;
BA_ "UserSigValidity" SG_ 2046 RLMSS_GST_Byte4 0;
BA_ "Version" SG_ 2046 RLMSS_GST_Byte4 "22.04.02";
BA_ "Description" SG_ 2046 RLMSS_GST_Byte5 "TP Index : 263";
BA_ "UsrSigPurpose" SG_ 2046 RLMSS_GST_Byte5 4;
BA_ "UserSigValidity" SG_ 2046 RLMSS_GST_Byte5 0;
BA_ "Version" SG_ 2046 RLMSS_GST_Byte5 "22.04.02";
BA_ "Description" SG_ 2046 RLMSS_GST_Byte6 "TP Index : 263";
BA_ "UsrSigPurpose" SG_ 2046 RLMSS_GST_Byte6 4;
BA_ "UserSigValidity" SG_ 2046 RLMSS_GST_Byte6 0;
BA_ "Version" SG_ 2046 RLMSS_GST_Byte6 "22.04.02";
BA_ "Description" SG_ 2046 RLMSS_GST_Byte7 "TP Index : 263";
BA_ "UsrSigPurpose" SG_ 2046 RLMSS_GST_Byte7 4;
BA_ "UserSigValidity" SG_ 2046 RLMSS_GST_Byte7 0;
BA_ "Version" SG_ 2046 RLMSS_GST_Byte7 "22.04.02";
BA_ "Description" SG_ 2046 RLMSS_GST_Byte1 "TP Index : 263";
BA_ "UsrSigPurpose" SG_ 2046 RLMSS_GST_Byte1 4;
BA_ "UserSigValidity" SG_ 2046 RLMSS_GST_Byte1 0;
BA_ "Version" SG_ 2046 RLMSS_GST_Byte1 "22.04.02";
BA_ "Description" SG_ 2164279809 IMU_Crc1Val "The data area for CRC calculation is based on the data length (DLC) of the message DB.

The CRC shall be calculated over the entire data block (excluding the CRC bytes) including the user data, alive counter and Data ID



- CRC Polynomial (0x1021) , Ini";
BA_ "GenSigStartValue" SG_ 2164279809 IMU_Crc1Val 65535;
BA_ "UserSigValidity" SG_ 2164279809 IMU_Crc1Val 3;
BA_ "RoutingFactor" SG_ 2164279809 IMU_Crc1Val 5;
BA_ "Version" SG_ 2164279809 IMU_Crc1Val "21.09.03";
BA_ "Description" SG_ 2164279809 IMU_AlvCnt1Val "For the first transmission request for a data element the counter shall be initialized with 0 and shall be incremented by 1 for every subsequent send request. 

When the counter reaches the maximum value(0xFF), then it shall restart with 0 for the next s";
BA_ "UserSigValidity" SG_ 2164279809 IMU_AlvCnt1Val 3;
BA_ "RoutingFactor" SG_ 2164279809 IMU_AlvCnt1Val 5;
BA_ "Version" SG_ 2164279809 IMU_AlvCnt1Val "21.09.03";
BA_ "Description" SG_ 2164279809 IMU_YawSigSta "This signal indicates failure status of yaw rate signal and yaw rate sensing element.



0000B : No failure 



xxx1B : IMU_Yawrate_failure



xx1xB : Initialization is running



x1xxB : Reserved



1xxxB : Reserved



This signal represents the physica";
BA_ "GenSigStartValue" SG_ 2164279809 IMU_YawSigSta 2;
BA_ "UserSigValidity" SG_ 2164279809 IMU_YawSigSta 3;
BA_ "RoutingFactor" SG_ 2164279809 IMU_YawSigSta 5;
BA_ "Version" SG_ 2164279809 IMU_YawSigSta "20.03.05";
BA_ "Description" SG_ 2164279809 IMU_LatAccelSigSta "This signal indicates failure status of lateral acceleration signal and sensing element.



0000B : No failure



xxx1B : IMU_Lateral acceleration failure



xx1xB : Initialization is running



x1xxB : Reserved



1xxxB : Reserved



This signal represe";
BA_ "GenSigStartValue" SG_ 2164279809 IMU_LatAccelSigSta 2;
BA_ "UserSigValidity" SG_ 2164279809 IMU_LatAccelSigSta 3;
BA_ "RoutingFactor" SG_ 2164279809 IMU_LatAccelSigSta 5;
BA_ "Version" SG_ 2164279809 IMU_LatAccelSigSta "20.03.05";
BA_ "Description" SG_ 2164279809 IMU_LongAccelSigSta "This signal indicates failure status of longitudinal acceleration signal and sensing element.



0000B : No failure 



xxx1B : IMU_Longitudial acceleration failure



xx1xB : Initialization is running



x1xxB : Reserved



1xxxB : Reserved



This sign";
BA_ "GenSigStartValue" SG_ 2164279809 IMU_LongAccelSigSta 2;
BA_ "UserSigValidity" SG_ 2164279809 IMU_LongAccelSigSta 3;
BA_ "RoutingFactor" SG_ 2164279809 IMU_LongAccelSigSta 5;
BA_ "Version" SG_ 2164279809 IMU_LongAccelSigSta "20.03.05";
BA_ "Description" SG_ 2164279809 IMU_VerAccelSigSta "This signal indicates failure status of  vertial acceleration signal and yaw rate sensing element.



0000B : No failure 



xxx1B : IMU_Vertial acceleration failure



xx1xB : Initialization is running



x1xxB : Reserved



1xxxB : Reserved



This sig";
BA_ "GenSigStartValue" SG_ 2164279809 IMU_VerAccelSigSta 2;
BA_ "UserSigValidity" SG_ 2164279809 IMU_VerAccelSigSta 3;
BA_ "RoutingFactor" SG_ 2164279809 IMU_VerAccelSigSta 5;
BA_ "Version" SG_ 2164279809 IMU_VerAccelSigSta "20.03.05";
BA_ "Description" SG_ 2164279809 IMU_McuVoltSta "This signal indicates the failure status of MCU.



0000B : No failure



xxx1B : MCU failure



xx1xB : Under voltage detected



x1xxB : Over voltage detected



1xxxB : Bus off failure



The status information(xxx1B) occurs when MCU error is detected";
BA_ "UserSigValidity" SG_ 2164279809 IMU_McuVoltSta 3;
BA_ "RoutingFactor" SG_ 2164279809 IMU_McuVoltSta 5;
BA_ "Version" SG_ 2164279809 IMU_McuVoltSta "20.03.05";
BA_ "Description" SG_ 2164279809 IMU_AcuRstSta "This signal indicates the status of IMU.



0000B : Normal mode 



xxx1B : IMU Reset mode



xx1xB : Reserved



x1xxB : Reserved



1xxxB : Reserved



If ACU reset is required, ACU will send IMU RESET bit(XXX1B) up to 30 times and perform a reset. If ";
BA_ "UserSigValidity" SG_ 2164279809 IMU_AcuRstSta 3;
BA_ "RoutingFactor" SG_ 2164279809 IMU_AcuRstSta 5;
BA_ "Version" SG_ 2164279809 IMU_AcuRstSta "20.03.05";
BA_ "Description" SG_ 2164279809 IMU_SnsrTyp "This signal indicates supported signals that are correspond to sensor type.

0001B = IMU (yaw rate and lateral acceleration)

0010B = IMU (yaw rate, lateral and longitudinal acceleration)

0100B = IMU (yaw / roll rate, lateral and longitudinal accelerati";
BA_ "GenSigStartValue" SG_ 2164279809 IMU_SnsrTyp 2;
BA_ "UserSigValidity" SG_ 2164279809 IMU_SnsrTyp 3;
BA_ "RoutingFactor" SG_ 2164279809 IMU_SnsrTyp 5;
BA_ "Version" SG_ 2164279809 IMU_SnsrTyp "20.03.05";
BA_ "Description" SG_ 2164279809 IMU_RollSigSta "This signal indicates failure status of roll rate signal and roll rate sensing element.



0000B : No failure 



xxx1B : IMU_Roll rate failure



xx1xB : Initialization is running



x1xxB : Reserved



1xxxB : Reserved



This signal represents the phy";
BA_ "GenSigStartValue" SG_ 2164279809 IMU_RollSigSta 2;
BA_ "UserSigValidity" SG_ 2164279809 IMU_RollSigSta 3;
BA_ "RoutingFactor" SG_ 2164279809 IMU_RollSigSta 5;
BA_ "Version" SG_ 2164279809 IMU_RollSigSta "20.03.05";
BA_ "Description" SG_ 2164279811 IMU_SeralNumVal "IMU serial number in range of 



0x000000000000 = 0......0xFFFFFFFFFFFF

¡ØInitial value shall be actual value

¡ØThis information is only for chipset with yaw sensor.";
BA_ "UserSigValidity" SG_ 2164279811 IMU_SeralNumVal 3;
BA_ "RoutingFactor" SG_ 2164279811 IMU_SeralNumVal 5;
BA_ "Version" SG_ 2164279811 IMU_SeralNumVal "20.03.05";
BA_ "Description" SG_ 942 AMP_Beep1VolumeStep "16.03.03_";
BA_ "GenSigSendType" SG_ 942 AMP_Beep1VolumeStep 4;
BA_ "GenSigStartValue" SG_ 942 AMP_Beep1VolumeStep 255;
BA_ "UserSigValidity" SG_ 942 AMP_Beep1VolumeStep 1;
BA_ "NetworkRequest" SG_ 942 AMP_Beep1VolumeStep 0;
BA_ "Version" SG_ 942 AMP_Beep1VolumeStep "19.02.03";
BA_ "Description" SG_ 942 AMP_Analog_OutputCh_Select "Command for Set Analog Output Channel to identify which Speakers will output Sound

- per bit, 0 means 'Not Output Channel' and 1 means 'Output Channel'

bit0 : FL / bit1 : FR / bit2 : RL / bit3 : RR / bit4 : CTR / bit5 : Surround L /

bit6 : Surround R ";
BA_ "GenSigSendType" SG_ 942 AMP_Analog_OutputCh_Select 4;
BA_ "UserSigValidity" SG_ 942 AMP_Analog_OutputCh_Select 1;
BA_ "Version" SG_ 942 AMP_Analog_OutputCh_Select "20.01.01";
BA_ "Description" SG_ 942 AMP_Beep1_OutputCh_Select "Command for Set Beep1 Output Channel to identify which Speakers will output Sound

- per bit, 0 means 'Not Output Channel' and 1 means 'Output Channel'

bit0 : FL / bit1 : FR / bit2 : RL / bit3 : RR / bit4 : CTR / bit5 : Surround L /

bit6 : Surround R /";
BA_ "GenSigSendType" SG_ 942 AMP_Beep1_OutputCh_Select 4;
BA_ "GenSigStartValue" SG_ 942 AMP_Beep1_OutputCh_Select 65535;
BA_ "UserSigValidity" SG_ 942 AMP_Beep1_OutputCh_Select 1;
BA_ "Version" SG_ 942 AMP_Beep1_OutputCh_Select "19.12.08";
BA_ "Description" SG_ 942 AMP_Beep1KBDVolumeStep "Command for AVN keyboard Touch Beep Sound Volume Setting 

-range : 0 ~ max

-max : value of AMP_MaxBeep1VolumeState

This Signal's Feedback is AMP_Beep1KBDVolumeState@AMP";
BA_ "GenSigSendType" SG_ 942 AMP_Beep1KBDVolumeStep 4;
BA_ "GenSigStartValue" SG_ 942 AMP_Beep1KBDVolumeStep 255;
BA_ "UserSigValidity" SG_ 942 AMP_Beep1KBDVolumeStep 1;
BA_ "Version" SG_ 942 AMP_Beep1KBDVolumeStep "20.06.01";
BA_ "Description" SG_ 942 AMP_SPDIF_OutputCh_Select "Command for Set SPDIF Output Channel to identify which Speakers will output Sound

- per bit, 0 means 'Not Output Channel' and 1 means 'Output Channel'

bit0 : FL / bit1 : FR / bit2 : RL / bit3 : RR / bit4 : CTR / bit5 : Surround L /

bit6 : Surround R /";
BA_ "GenSigSendType" SG_ 942 AMP_SPDIF_OutputCh_Select 4;
BA_ "GenSigStartValue" SG_ 942 AMP_SPDIF_OutputCh_Select 255;
BA_ "UserSigValidity" SG_ 942 AMP_SPDIF_OutputCh_Select 1;
BA_ "Version" SG_ 942 AMP_SPDIF_OutputCh_Select "19.12.02";
BA_ "Description" SG_ 2164279810 IMU_YawRtVal "This signal indicates Information regarding yaw rate.



physical range : -163.84..163.83 ¢ª/s = 0000H..FFFEh



Conversion : (PH) = ((HEX)-8000H)*0.005[¢ª/s/digit]



                            = (HEX)*0.005[¢ª/s/digit] - 163.84[¢ª/s]



              ";
BA_ "GenSigStartValue" SG_ 2164279810 IMU_YawRtVal 32768;
BA_ "UserSigValidity" SG_ 2164279810 IMU_YawRtVal 3;
BA_ "RoutingFactor" SG_ 2164279810 IMU_YawRtVal 5;
BA_ "Version" SG_ 2164279810 IMU_YawRtVal "20.03.05";
BA_ "Description" SG_ 2164279810 IMU_LatAccelVal "This signal indicates Information regarding lateral acceleration.



physical range : -4.1768g..4.1765g = 0000H..FFFEh



Conversion : (PH) = ((HEX)-8000H)*0.000127465[g/digit]



                            = (HEX)*0.000127465[g/digit] - 4.17677312[g]

";
BA_ "GenSigStartValue" SG_ 2164279810 IMU_LatAccelVal 32768;
BA_ "UserSigValidity" SG_ 2164279810 IMU_LatAccelVal 3;
BA_ "RoutingFactor" SG_ 2164279810 IMU_LatAccelVal 5;
BA_ "Version" SG_ 2164279810 IMU_LatAccelVal "20.03.05";
BA_ "Description" SG_ 2164279810 IMU_LongAccelVal "This signal indicates information regarding longitudinal acceleration.



physical range : -4.1768g..4.1765g = 0000H..FFFEh



Conversion : (PH) = ((HEX)-8000H)*0.000127465[g/digit]



                            = (HEX)*0.000127465[g/digit] - 4.17677312";
BA_ "GenSigStartValue" SG_ 2164279810 IMU_LongAccelVal 32768;
BA_ "UserSigValidity" SG_ 2164279810 IMU_LongAccelVal 3;
BA_ "RoutingFactor" SG_ 2164279810 IMU_LongAccelVal 5;
BA_ "Version" SG_ 2164279810 IMU_LongAccelVal "20.03.05";
BA_ "Description" SG_ 2164279810 IMU_SnsrTempVal "The temperature is measured on sensing element chip in ACU, so it may be different from the display indicator temperature of the vehicle.



Physical range: -68¡ÆC = 00h, +60 ¡ÆC = 80h, +187¡ÆC = FFh



Quantization LSB: 1[¡ÆC/digit]



Temperature [¡ÆC]";
BA_ "GenSigStartValue" SG_ 2164279810 IMU_SnsrTempVal 68;
BA_ "UserSigValidity" SG_ 2164279810 IMU_SnsrTempVal 3;
BA_ "RoutingFactor" SG_ 2164279810 IMU_SnsrTempVal 5;
BA_ "Version" SG_ 2164279810 IMU_SnsrTempVal "20.03.05";
BA_ "Description" SG_ 2164279812 IMU_RollRtVal "This signal indicates Information regarding Roll rate.



physical range : -163.84..163.83 ¢ª/s = 0000H..FFFEh



Conversion : (PH) = ((HEX)-8000H)*0.005[¢ª/s/digit]



                            = (HEX)*0.005[¢ª/s/digit] - 163.84[¢ª/s]



             ";
BA_ "GenSigStartValue" SG_ 2164279812 IMU_RollRtVal 32768;
BA_ "UserSigValidity" SG_ 2164279812 IMU_RollRtVal 3;
BA_ "RoutingFactor" SG_ 2164279812 IMU_RollRtVal 5;
BA_ "Version" SG_ 2164279812 IMU_RollRtVal "20.03.05";
BA_ "Description" SG_ 2164279812 IMU_VerAccelVal "This signal indicates Information regarding Vertical acceleration.



physical range : -4.1768g..4.1765g = 0000H..FFFEh



Conversion : (PH) = ((HEX)-8000H)*0.000127465[g/digit]



                            = (HEX)*0.000127465[g/digit] - 4.17677312[g]

";
BA_ "GenSigStartValue" SG_ 2164279812 IMU_VerAccelVal 32768;
BA_ "UserSigValidity" SG_ 2164279812 IMU_VerAccelVal 3;
BA_ "RoutingFactor" SG_ 2164279812 IMU_VerAccelVal 5;
BA_ "Version" SG_ 2164279812 IMU_VerAccelVal "20.03.05";
BA_ "Description" SG_ 939 PSB_Crc1Val "The data area for CRC calculation is based on the data length (DLC) of the message DB.

The CRC shall be calculated over the entire data block (excluding the CRC bytes) including the user data, alive counter and Data ID 

 

- CRC Polynomial (0x1D) , Ini";
BA_ "UserSigValidity" SG_ 939 PSB_Crc1Val 0;
BA_ "Version" SG_ 939 PSB_Crc1Val "18.11.08";
BA_ "Description" SG_ 939 PSB_AlvCnt1Val "For the first transmission request for a data element the counter shall be initialized with 0 and shall be incremented by 1

for every subsequent send request. When the counter reaches the maximum value(0xE), then it shall restart with 0 for the next sen";
BA_ "UserSigValidity" SG_ 939 PSB_AlvCnt1Val 0;
BA_ "Version" SG_ 939 PSB_AlvCnt1Val "18.11.08";
BA_ "Description" SG_ 939 PSB_LHFlrSta "Information about availability of PSB_LH (LH Pre-Safe S/Belt).";
BA_ "UserSigValidity" SG_ 939 PSB_LHFlrSta 0;
BA_ "Version" SG_ 939 PSB_LHFlrSta "18.02.03";
BA_ "Description" SG_ 939 PSB_LHActvSta "Seat belt active state. This signal is for the monitoring of Pre-Safe S/Belt.

If there is a request, but no realization by the Pre-Safe S/Belt -> failure entry in the SCC(Radar).";
BA_ "UserSigValidity" SG_ 939 PSB_LHActvSta 0;
BA_ "Version" SG_ 939 PSB_LHActvSta "18.02.03";
BA_ "Description" SG_ 939 PSB_RHFlrSta "Information about availability of PSB_RH (LH Pre-Safe S/Belt).";
BA_ "UserSigValidity" SG_ 939 PSB_RHFlrSta 0;
BA_ "Version" SG_ 939 PSB_RHFlrSta "18.02.03";
BA_ "Description" SG_ 939 PSB_RHActvSta "Seat belt active state. This signal is for the monitoring of Pre-Safe S/Belt.

If there is a request, but no realization by the Pre-Safe S/Belt -> failure entry in the SCC(Radar).";
BA_ "UserSigValidity" SG_ 939 PSB_RHActvSta 0;
BA_ "Version" SG_ 939 PSB_RHActvSta "18.02.03";
BA_ "Description" SG_ 939 PSB_ActForAcu "This signal indicates status of Pre-Safe S/Belt activation by ACU commends.";
BA_ "UserSigValidity" SG_ 939 PSB_ActForAcu 0;
BA_ "Version" SG_ 939 PSB_ActForAcu "18.02.03";
BA_ "Description" SG_ 939 PSB_HapticWarnSta "This signal indicates sattus of Pre-active S/Belt Haptic activation by HDP commends";
BA_ "UserSigValidity" SG_ 939 PSB_HapticWarnSta 0;
BA_ "Version" SG_ 939 PSB_HapticWarnSta "22.04.02";
BA_ "Description" SG_ 939 PSB_RHActForPss "Seat belt active state. 

This signal is for the monitoring of Pre-Safe S/Belt  in conjunction with PSS.

If there is a request, but no realization by the Pre-Safe S/Belt -> failure entry in the SCC(Radar).";
BA_ "UserSigValidity" SG_ 939 PSB_RHActForPss 0;
BA_ "Version" SG_ 939 PSB_RHActForPss "21.04.00";
BA_ "Description" SG_ 939 PSB_HDPSpprtSWVer "This signal indicates Requirement Spec Version about PSB haptic active by HDP";
BA_ "UserSigValidity" SG_ 939 PSB_HDPSpprtSWVer 0;
BA_ "Version" SG_ 939 PSB_HDPSpprtSWVer "22.04.02";
BA_ "Description" SG_ 939 PSB_LHActForPss "Seat belt active state. 

This signal is for the monitoring of Pre-Safe S/Belt in conjunction with PSS.

If there is a request, but no realization by the Pre-Safe S/Belt -> failure entry in the SCC(Radar).";
BA_ "UserSigValidity" SG_ 939 PSB_LHActForPss 0;
BA_ "Version" SG_ 939 PSB_LHActForPss "21.04.00";
BA_ "Description" SG_ 2239851012 RSPA_DCTTrgtTqVal "RSPA request DCT torque value (Nm)

Init value : 00h

If MSB is 1, this signal is - value.

else, this signal is +value.

0~10bit is used for absolute value.";
BA_ "UserSigValidity" SG_ 2239851012 RSPA_DCTTrgtTqVal 3;
BA_ "RoutingFactor" SG_ 2239851012 RSPA_DCTTrgtTqVal 5;
BA_ "Version" SG_ 2239851012 RSPA_DCTTrgtTqVal "19.06.00";
BA_ "Description" SG_ 2239851012 RSPA_HdLmpReq "Head lamp request of RSPA";
BA_ "UserSigValidity" SG_ 2239851012 RSPA_HdLmpReq 3;
BA_ "RoutingFactor" SG_ 2239851012 RSPA_HdLmpReq 5;
BA_ "Version" SG_ 2239851012 RSPA_HdLmpReq "20.10.00";
BA_ "Description" SG_ 2239851012 RSPA_OSMirFoldReq "OS Mirror folding/unfolding request of RSPA";
BA_ "UserSigValidity" SG_ 2239851012 RSPA_OSMirFoldReq 3;
BA_ "RoutingFactor" SG_ 2239851012 RSPA_OSMirFoldReq 5;
BA_ "Version" SG_ 2239851012 RSPA_OSMirFoldReq "19.08.08";
BA_ "Description" SG_ 934 PTGM_Crc1Val "The data area for CRC calculation is based on the data length (DLC) of the message DB.

The CRC shall be calculated over the entire data block (excluding the CRC bytes) including the user data, alive counter and Data ID 

 

- CRC Polynomial (0x1D) , Ini";
BA_ "GenSigSendType" SG_ 934 PTGM_Crc1Val 4;
BA_ "GenSigStartValue" SG_ 934 PTGM_Crc1Val 255;
BA_ "UserSigValidity" SG_ 934 PTGM_Crc1Val 0;
BA_ "Version" SG_ 934 PTGM_Crc1Val "18.11.08";
BA_ "Description" SG_ 934 PTGM_AlvCnt1Val "For the first transmission request for a data element the counter shall be initialized with 0 and shall be incremented by 1

for every subsequent send request. When the counter reaches the maximum value(0xE), then it shall restart with 0 for the next sen";
BA_ "GenSigSendType" SG_ 934 PTGM_AlvCnt1Val 4;
BA_ "UserSigValidity" SG_ 934 PTGM_AlvCnt1Val 0;
BA_ "Version" SG_ 934 PTGM_AlvCnt1Val "18.11.08";
BA_ "Description" SG_ 934 PTGM_HazardSta "-(Old)C_PTHazard";
BA_ "GenSigSendType" SG_ 934 PTGM_HazardSta 4;
BA_ "GenSigStartValue" SG_ 934 PTGM_HazardSta 2;
BA_ "UserSigValidity" SG_ 934 PTGM_HazardSta 0;
BA_ "NetworkRequest" SG_ 934 PTGM_HazardSta 0;
BA_ "NetworkRequestHoldingTime" SG_ 934 PTGM_HazardSta 5000;
BA_ "Version" SG_ 934 PTGM_HazardSta "21.07.05";
BA_ "Description" SG_ 934 PTGM_ModSta "PTGM Moudule Status";
BA_ "GenSigSendType" SG_ 934 PTGM_ModSta 4;
BA_ "UserSigValidity" SG_ 934 PTGM_ModSta 0;
BA_ "NetworkRequest" SG_ 934 PTGM_ModSta 0;
BA_ "NetworkRequestHoldingTime" SG_ 934 PTGM_ModSta 5000;
BA_ "Version" SG_ 934 PTGM_ModSta "21.07.05";
BA_ "Description" SG_ 934 PTGM_MovSta "PTGM Status (stop or moving)";
BA_ "GenSigSendType" SG_ 934 PTGM_MovSta 4;
BA_ "UserSigValidity" SG_ 934 PTGM_MovSta 0;
BA_ "NetworkRequest" SG_ 934 PTGM_MovSta 0;
BA_ "NetworkRequestHoldingTime" SG_ 934 PTGM_MovSta 5000;
BA_ "Version" SG_ 934 PTGM_MovSta "21.07.05";
BA_ "GenSigSendType" SG_ 934 PTGM_OptTyp 4;
BA_ "UserSigValidity" SG_ 934 PTGM_OptTyp 0;
BA_ "NetworkRequest" SG_ 934 PTGM_OptTyp 0;
BA_ "NetworkRequestHoldingTime" SG_ 934 PTGM_OptTyp 5000;
BA_ "Version" SG_ 934 PTGM_OptTyp "21.07.05";
BA_ "GenSigSendType" SG_ 934 PTGM_ReleaseRlySta 4;
BA_ "UserSigValidity" SG_ 934 PTGM_ReleaseRlySta 0;
BA_ "NetworkRequest" SG_ 934 PTGM_ReleaseRlySta 0;
BA_ "NetworkRequestHoldingTime" SG_ 934 PTGM_ReleaseRlySta 5000;
BA_ "Version" SG_ 934 PTGM_ReleaseRlySta "21.07.05";
BA_ "Description" SG_ 934 PTGM_TrnkLkSwSta "-(Old)C_Trunk_Lock_Sw";
BA_ "GenSigSendType" SG_ 934 PTGM_TrnkLkSwSta 4;
BA_ "UserSigValidity" SG_ 934 PTGM_TrnkLkSwSta 0;
BA_ "NetworkRequest" SG_ 934 PTGM_TrnkLkSwSta 0;
BA_ "NetworkRequestHoldingTime" SG_ 934 PTGM_TrnkLkSwSta 5000;
BA_ "Version" SG_ 934 PTGM_TrnkLkSwSta "21.07.05";
BA_ "Description" SG_ 934 PTGM_UsmSetSta "PTGM USM Setting Signal";
BA_ "GenSigSendType" SG_ 934 PTGM_UsmSetSta 4;
BA_ "UserSigValidity" SG_ 934 PTGM_UsmSetSta 3;
BA_ "NetworkRequest" SG_ 934 PTGM_UsmSetSta 0;
BA_ "NetworkRequestHoldingTime" SG_ 934 PTGM_UsmSetSta 5000;
BA_ "Version" SG_ 934 PTGM_UsmSetSta "17.11.00";
BA_ "Description" SG_ 934 PTGM_HeightRValue "PTG Opening Height USM Setting Signal";
BA_ "GenSigSendType" SG_ 934 PTGM_HeightRValue 4;
BA_ "UserSigValidity" SG_ 934 PTGM_HeightRValue 0;
BA_ "NetworkRequest" SG_ 934 PTGM_HeightRValue 0;
BA_ "Version" SG_ 934 PTGM_HeightRValue "21.07.05";
BA_ "Description" SG_ 934 PTGM_OpnClsState "This signal indicates PTGM Open/Close Status";
BA_ "GenSigSendType" SG_ 934 PTGM_OpnClsState 4;
BA_ "UserSigValidity" SG_ 934 PTGM_OpnClsState 0;
BA_ "Version" SG_ 934 PTGM_OpnClsState "21.07.05";
BA_ "Description" SG_ 934 PTGM_CmdWarn "This signal indicates PTGM Warning Status";
BA_ "GenSigSendType" SG_ 934 PTGM_CmdWarn 4;
BA_ "UserSigValidity" SG_ 934 PTGM_CmdWarn 3;
BA_ "Version" SG_ 934 PTGM_CmdWarn "21.07.05";
BA_ "Description" SG_ 934 PTGM_AntiPinchSnsr "This signal indicates Anti-Pinch Sensor Applied Status";
BA_ "GenSigSendType" SG_ 934 PTGM_AntiPinchSnsr 4;
BA_ "UserSigValidity" SG_ 934 PTGM_AntiPinchSnsr 0;
BA_ "Version" SG_ 934 PTGM_AntiPinchSnsr "18.02.03";
BA_ "Description" SG_ 934 PTGM_AutoWashModeSta "PTGM Auto Wash Mode Status Signal";
BA_ "GenSigSendType" SG_ 934 PTGM_AutoWashModeSta 4;
BA_ "TimeoutValue" SG_ 934 PTGM_AutoWashModeSta "0x0";
BA_ "UserSigValidity" SG_ 934 PTGM_AutoWashModeSta 0;
BA_ "Version" SG_ 934 PTGM_AutoWashModeSta "22.01.03";
BA_ "Description" SG_ 934 PTGM_FobSrch_Req "FOB Search Request";
BA_ "GenSigSendType" SG_ 934 PTGM_FobSrch_Req 4;
BA_ "UserSigValidity" SG_ 934 PTGM_FobSrch_Req 0;
BA_ "NetworkRequest" SG_ 934 PTGM_FobSrch_Req 0;
BA_ "NetworkRequestHoldingTime" SG_ 934 PTGM_FobSrch_Req 5000;
BA_ "Version" SG_ 934 PTGM_FobSrch_Req "19.01.11";
BA_ "Description" SG_ 934 PTGM_TlgtAwayCloseRValue "Tailgate Away Close USM On/Off Setting Signal";
BA_ "GenSigSendType" SG_ 934 PTGM_TlgtAwayCloseRValue 4;
BA_ "UserSigValidity" SG_ 934 PTGM_TlgtAwayCloseRValue 0;
BA_ "NetworkRequest" SG_ 934 PTGM_TlgtAwayCloseRValue 0;
BA_ "NetworkRequestHoldingTime" SG_ 934 PTGM_TlgtAwayCloseRValue 5000;
BA_ "Version" SG_ 934 PTGM_TlgtAwayCloseRValue "19.01.10";
BA_ "Description" SG_ 934 PTGM_TrnkTlgtOption "PTGM(Power Tail Gate Module) Option Signal";
BA_ "GenSigSendType" SG_ 934 PTGM_TrnkTlgtOption 4;
BA_ "UserSigValidity" SG_ 934 PTGM_TrnkTlgtOption 0;
BA_ "NetworkRequest" SG_ 934 PTGM_TrnkTlgtOption 0;
BA_ "NetworkRequestHoldingTime" SG_ 934 PTGM_TrnkTlgtOption 5000;
BA_ "Version" SG_ 934 PTGM_TrnkTlgtOption "19.05.00";
BA_ "Description" SG_ 934 PTGM_LatchType "This signal indicates the Tailgate/Trunk Latch Type. (Integrated / Separated)";
BA_ "GenSigSendType" SG_ 934 PTGM_LatchType 4;
BA_ "UserSigValidity" SG_ 934 PTGM_LatchType 0;
BA_ "Version" SG_ 934 PTGM_LatchType "19.07.01";
BA_ "Description" SG_ 934 PTGM_SpeedRValue "PTG Speed USM Setting Signal";
BA_ "GenSigSendType" SG_ 934 PTGM_SpeedRValue 4;
BA_ "UserSigValidity" SG_ 934 PTGM_SpeedRValue 0;
BA_ "NetworkRequest" SG_ 934 PTGM_SpeedRValue 0;
BA_ "Version" SG_ 934 PTGM_SpeedRValue "18.02.03";
BA_ "Description" SG_ 2239851010 RSPA_Var "RSPA variation";
BA_ "UserSigValidity" SG_ 2239851010 RSPA_Var 3;
BA_ "RoutingFactor" SG_ 2239851010 RSPA_Var 5;
BA_ "Version" SG_ 2239851010 RSPA_Var "19.08.08";
BA_ "Description" SG_ 2239851010 RSPA_Sta "ÇöÀç RSPAÀÇ »óÅÂ";
BA_ "GenSigStartValue" SG_ 2239851010 RSPA_Sta 1;
BA_ "UserSigValidity" SG_ 2239851010 RSPA_Sta 3;
BA_ "RoutingFactor" SG_ 2239851010 RSPA_Sta 5;
BA_ "Version" SG_ 2239851010 RSPA_Sta "19.03.11";
BA_ "Description" SG_ 2239851010 RSPA_Actv "RSPA's activation information";
BA_ "UserSigValidity" SG_ 2239851010 RSPA_Actv 3;
BA_ "RoutingFactor" SG_ 2239851010 RSPA_Actv 5;
BA_ "Version" SG_ 2239851010 RSPA_Actv "17.11.00";
BA_ "Description" SG_ 2239851010 RSPA_EvasiveStrBtnDis "Display evasive steering on/off button (RSPA II)";
BA_ "UserSigValidity" SG_ 2239851010 RSPA_EvasiveStrBtnDis 3;
BA_ "RoutingFactor" SG_ 2239851010 RSPA_EvasiveStrBtnDis 5;
BA_ "Version" SG_ 2239851010 RSPA_EvasiveStrBtnDis "19.08.08";
BA_ "Description" SG_ 929 SCM_Opt "SCM option";
BA_ "GenSigSendType" SG_ 929 SCM_Opt 4;
BA_ "UserSigValidity" SG_ 929 SCM_Opt 0;
BA_ "NetworkRequest" SG_ 929 SCM_Opt 0;
BA_ "NetworkRequestHoldingTime" SG_ 929 SCM_Opt 5000;
BA_ "Version" SG_ 929 SCM_Opt "21.02.00";
BA_ "Description" SG_ 929 Tilt_VirtualLimExist "Tilt virtual limit existence";
BA_ "GenSigSendType" SG_ 929 Tilt_VirtualLimExist 4;
BA_ "UserSigValidity" SG_ 929 Tilt_VirtualLimExist 0;
BA_ "NetworkRequest" SG_ 929 Tilt_VirtualLimExist 0;
BA_ "NetworkRequestHoldingTime" SG_ 929 Tilt_VirtualLimExist 5000;
BA_ "Version" SG_ 929 Tilt_VirtualLimExist "21.02.00";
BA_ "Description" SG_ 929 Tele_SnsrErr "Telescopic operating error by Hall Sensor";
BA_ "GenSigSendType" SG_ 929 Tele_SnsrErr 4;
BA_ "TimeoutValue" SG_ 929 Tele_SnsrErr "0x0";
BA_ "UserSigValidity" SG_ 929 Tele_SnsrErr 0;
BA_ "NetworkRequest" SG_ 929 Tele_SnsrErr 0;
BA_ "NetworkRequestHoldingTime" SG_ 929 Tele_SnsrErr 5000;
BA_ "Version" SG_ 929 Tele_SnsrErr "22.02.02";
BA_ "Description" SG_ 929 Tele_VirtualLim "Reached to Telescopic Virtual Limit";
BA_ "GenSigSendType" SG_ 929 Tele_VirtualLim 4;
BA_ "TimeoutValue" SG_ 929 Tele_VirtualLim "0x0";
BA_ "UserSigValidity" SG_ 929 Tele_VirtualLim 0;
BA_ "NetworkRequest" SG_ 929 Tele_VirtualLim 0;
BA_ "NetworkRequestHoldingTime" SG_ 929 Tele_VirtualLim 5000;
BA_ "Version" SG_ 929 Tele_VirtualLim "21.02.00";
BA_ "Description" SG_ 929 Tele_VirtualLimExist "Telescopic virtual limit existence";
BA_ "GenSigSendType" SG_ 929 Tele_VirtualLimExist 4;
BA_ "UserSigValidity" SG_ 929 Tele_VirtualLimExist 0;
BA_ "NetworkRequest" SG_ 929 Tele_VirtualLimExist 0;
BA_ "NetworkRequestHoldingTime" SG_ 929 Tele_VirtualLimExist 5000;
BA_ "Version" SG_ 929 Tele_VirtualLimExist "21.02.00";
BA_ "Description" SG_ 929 TiltTele_Profile1MemoryExist "Profile1 memory existence";
BA_ "GenSigSendType" SG_ 929 TiltTele_Profile1MemoryExist 4;
BA_ "UserSigValidity" SG_ 929 TiltTele_Profile1MemoryExist 0;
BA_ "NetworkRequest" SG_ 929 TiltTele_Profile1MemoryExist 0;
BA_ "NetworkRequestHoldingTime" SG_ 929 TiltTele_Profile1MemoryExist 5000;
BA_ "Version" SG_ 929 TiltTele_Profile1MemoryExist "21.02.00";
BA_ "Description" SG_ 929 Tilt_MnlSwSta "Tilt manual switch state";
BA_ "GenSigSendType" SG_ 929 Tilt_MnlSwSta 4;
BA_ "TimeoutValue" SG_ 929 Tilt_MnlSwSta "0x0";
BA_ "UserSigValidity" SG_ 929 Tilt_MnlSwSta 0;
BA_ "NetworkRequest" SG_ 929 Tilt_MnlSwSta 0;
BA_ "NetworkRequestHoldingTime" SG_ 929 Tilt_MnlSwSta 5000;
BA_ "Version" SG_ 929 Tilt_MnlSwSta "21.02.00";
BA_ "Description" SG_ 929 TiltTele_Profile2MemoryExist "Profile2 memory existence";
BA_ "GenSigSendType" SG_ 929 TiltTele_Profile2MemoryExist 4;
BA_ "UserSigValidity" SG_ 929 TiltTele_Profile2MemoryExist 0;
BA_ "NetworkRequest" SG_ 929 TiltTele_Profile2MemoryExist 0;
BA_ "NetworkRequestHoldingTime" SG_ 929 TiltTele_Profile2MemoryExist 5000;
BA_ "Version" SG_ 929 TiltTele_Profile2MemoryExist "21.02.00";
BA_ "Description" SG_ 929 TiltTele_GuestMemoryExist "Guest memory existence";
BA_ "GenSigSendType" SG_ 929 TiltTele_GuestMemoryExist 4;
BA_ "UserSigValidity" SG_ 929 TiltTele_GuestMemoryExist 0;
BA_ "NetworkRequest" SG_ 929 TiltTele_GuestMemoryExist 0;
BA_ "NetworkRequestHoldingTime" SG_ 929 TiltTele_GuestMemoryExist 5000;
BA_ "Version" SG_ 929 TiltTele_GuestMemoryExist "21.02.00";
BA_ "Description" SG_ 929 TiltTele_IMS1MemoryExist "IMS1 memory existence";
BA_ "GenSigSendType" SG_ 929 TiltTele_IMS1MemoryExist 4;
BA_ "UserSigValidity" SG_ 929 TiltTele_IMS1MemoryExist 0;
BA_ "NetworkRequest" SG_ 929 TiltTele_IMS1MemoryExist 0;
BA_ "NetworkRequestHoldingTime" SG_ 929 TiltTele_IMS1MemoryExist 5000;
BA_ "Version" SG_ 929 TiltTele_IMS1MemoryExist "21.02.00";
BA_ "Description" SG_ 929 TiltTele_IMS2MemoryExist "IMS2 memory existence";
BA_ "GenSigSendType" SG_ 929 TiltTele_IMS2MemoryExist 4;
BA_ "UserSigValidity" SG_ 929 TiltTele_IMS2MemoryExist 0;
BA_ "NetworkRequest" SG_ 929 TiltTele_IMS2MemoryExist 0;
BA_ "NetworkRequestHoldingTime" SG_ 929 TiltTele_IMS2MemoryExist 5000;
BA_ "Version" SG_ 929 TiltTele_IMS2MemoryExist "21.02.00";
BA_ "Description" SG_ 929 TiltTele_IMS3MemoryExist "IMS3 memory existence";
BA_ "GenSigSendType" SG_ 929 TiltTele_IMS3MemoryExist 4;
BA_ "UserSigValidity" SG_ 929 TiltTele_IMS3MemoryExist 0;
BA_ "NetworkRequest" SG_ 929 TiltTele_IMS3MemoryExist 0;
BA_ "NetworkRequestHoldingTime" SG_ 929 TiltTele_IMS3MemoryExist 5000;
BA_ "Version" SG_ 929 TiltTele_IMS3MemoryExist "21.02.00";
BA_ "Description" SG_ 929 TiltTele_ReturnMemoryExist "Auto Return memory existence";
BA_ "GenSigSendType" SG_ 929 TiltTele_ReturnMemoryExist 4;
BA_ "UserSigValidity" SG_ 929 TiltTele_ReturnMemoryExist 0;
BA_ "NetworkRequest" SG_ 929 TiltTele_ReturnMemoryExist 0;
BA_ "NetworkRequestHoldingTime" SG_ 929 TiltTele_ReturnMemoryExist 5000;
BA_ "Version" SG_ 929 TiltTele_ReturnMemoryExist "21.02.00";
BA_ "Description" SG_ 929 Tilt_OpSta "Tilt operating state (Motor output command, not real motor output)";
BA_ "GenSigSendType" SG_ 929 Tilt_OpSta 4;
BA_ "TimeoutValue" SG_ 929 Tilt_OpSta "0x0";
BA_ "UserSigValidity" SG_ 929 Tilt_OpSta 0;
BA_ "NetworkRequest" SG_ 929 Tilt_OpSta 0;
BA_ "NetworkRequestHoldingTime" SG_ 929 Tilt_OpSta 5000;
BA_ "Version" SG_ 929 Tilt_OpSta "22.02.02";
BA_ "Description" SG_ 929 Tele_OpSta "Telescopic operating state (Motor output command, not real motor output)";
BA_ "GenSigSendType" SG_ 929 Tele_OpSta 4;
BA_ "TimeoutValue" SG_ 929 Tele_OpSta "0x0";
BA_ "UserSigValidity" SG_ 929 Tele_OpSta 0;
BA_ "NetworkRequest" SG_ 929 Tele_OpSta 0;
BA_ "NetworkRequestHoldingTime" SG_ 929 Tele_OpSta 5000;
BA_ "Version" SG_ 929 Tele_OpSta "22.02.02";
BA_ "Description" SG_ 929 Tele_MnlSwSta "Telescopic manual switch state";
BA_ "GenSigSendType" SG_ 929 Tele_MnlSwSta 4;
BA_ "TimeoutValue" SG_ 929 Tele_MnlSwSta "0x0";
BA_ "UserSigValidity" SG_ 929 Tele_MnlSwSta 0;
BA_ "NetworkRequest" SG_ 929 Tele_MnlSwSta 0;
BA_ "NetworkRequestHoldingTime" SG_ 929 Tele_MnlSwSta 5000;
BA_ "Version" SG_ 929 Tele_MnlSwSta "21.02.02";
BA_ "Description" SG_ 929 Tilt_SnsrErr "Tilt operating error by Hall Sensor";
BA_ "GenSigSendType" SG_ 929 Tilt_SnsrErr 4;
BA_ "TimeoutValue" SG_ 929 Tilt_SnsrErr "0x0";
BA_ "UserSigValidity" SG_ 929 Tilt_SnsrErr 0;
BA_ "NetworkRequest" SG_ 929 Tilt_SnsrErr 0;
BA_ "NetworkRequestHoldingTime" SG_ 929 Tilt_SnsrErr 5000;
BA_ "Version" SG_ 929 Tilt_SnsrErr "22.02.02";
BA_ "Description" SG_ 929 Tilt_VirtualLim "Reached to Tilt virtual limit";
BA_ "GenSigSendType" SG_ 929 Tilt_VirtualLim 4;
BA_ "TimeoutValue" SG_ 929 Tilt_VirtualLim "0x0";
BA_ "UserSigValidity" SG_ 929 Tilt_VirtualLim 0;
BA_ "NetworkRequest" SG_ 929 Tilt_VirtualLim 0;
BA_ "NetworkRequestHoldingTime" SG_ 929 Tilt_VirtualLim 5000;
BA_ "Version" SG_ 929 Tilt_VirtualLim "21.02.00";
BA_ "Description" SG_ 2239851011 RSPA_TrgtGearSta "¸ñÇ¥ º¯¼Ó´Ü 

(¸ñÇ¥ º¯¼Ó´Ü 100ms À¯ÁöÈÄ Idle °ª ¼ÛÃâ, ¸ñÇ¥°ª rising ÀÌÈÄ 500ms ´ë±â)";
BA_ "UserSigValidity" SG_ 2239851011 RSPA_TrgtGearSta 3;
BA_ "RoutingFactor" SG_ 2239851011 RSPA_TrgtGearSta 5;
BA_ "Version" SG_ 2239851011 RSPA_TrgtGearSta "17.11.00";
BA_ "Description" SG_ 2239851011 RSPA_IdOutWarnReq "ID out ÆÐÅÏ º¯°æ ¿äÃ» (RSPA ¿ë)";
BA_ "UserSigValidity" SG_ 2239851011 RSPA_IdOutWarnReq 3;
BA_ "RoutingFactor" SG_ 2239851011 RSPA_IdOutWarnReq 5;
BA_ "Version" SG_ 2239851011 RSPA_IdOutWarnReq "17.11.00";
BA_ "Description" SG_ 2239851011 RSPA_IndBlnkReq "FOB blinking request during RSPA mode";
BA_ "UserSigValidity" SG_ 2239851011 RSPA_IndBlnkReq 3;
BA_ "RoutingFactor" SG_ 2239851011 RSPA_IndBlnkReq 5;
BA_ "Version" SG_ 2239851011 RSPA_IndBlnkReq "17.11.00";
BA_ "Description" SG_ 2239851011 RSPA_SysOff "System off status for Smartphone display before RSPA control";
BA_ "UserSigValidity" SG_ 2239851011 RSPA_SysOff 3;
BA_ "RoutingFactor" SG_ 2239851011 RSPA_SysOff 5;
BA_ "Version" SG_ 2239851011 RSPA_SysOff "18.12.07";
BA_ "Description" SG_ 2239851011 RSPA_DccCmd "¸ñÇ¥ °¨¼Óµµ, Â÷·® Á¤Â÷ ½Ã¿¡¸¸(when RSPA_VS=0) °¨¼Óµµ Á¦¾î¸ñÀû";
BA_ "UserSigValidity" SG_ 2239851011 RSPA_DccCmd 3;
BA_ "RoutingFactor" SG_ 2239851011 RSPA_DccCmd 5;
BA_ "Version" SG_ 2239851011 RSPA_DccCmd "17.11.00";
BA_ "Description" SG_ 2239851011 RSPA_StopReq "A control request flag for vehicle stop. RSPA expects vehicle to be controlled to a complete stop and hold its state.";
BA_ "UserSigValidity" SG_ 2239851011 RSPA_StopReq 3;
BA_ "RoutingFactor" SG_ 2239851011 RSPA_StopReq 5;
BA_ "Version" SG_ 2239851011 RSPA_StopReq "17.11.00";
BA_ "Description" SG_ 2239851011 RSPA_SelDevInfo "Device information for Remote Control in operation of RSPA";
BA_ "UserSigValidity" SG_ 2239851011 RSPA_SelDevInfo 3;
BA_ "RoutingFactor" SG_ 2239851011 RSPA_SelDevInfo 5;
BA_ "Version" SG_ 2239851011 RSPA_SelDevInfo "18.12.07";
BA_ "Description" SG_ 2239851011 RSPA_SelFuncInfo "Function information in operation of RSPA for SmartPhone control";
BA_ "UserSigValidity" SG_ 2239851011 RSPA_SelFuncInfo 3;
BA_ "RoutingFactor" SG_ 2239851011 RSPA_SelFuncInfo 5;
BA_ "Version" SG_ 2239851011 RSPA_SelFuncInfo "18.12.07";
BA_ "Description" SG_ 2239851011 RSPA_TrgtVehSpdVal "Â÷¼Ó ¿äÃ»°ª, Â÷¼Ó ÇÁ·ÎÆÄÀÏ Àü¼Û (0 ¡¦ 10.23)";
BA_ "UserSigValidity" SG_ 2239851011 RSPA_TrgtVehSpdVal 3;
BA_ "RoutingFactor" SG_ 2239851011 RSPA_TrgtVehSpdVal 5;
BA_ "Version" SG_ 2239851011 RSPA_TrgtVehSpdVal "18.07.01";
BA_ "Description" SG_ 2239851011 RSPA_EpbReq "EPB Ã¼°á/ÇØÁ¦ ¿äÃ» (AHB ¿ìÈ¸)";
BA_ "UserSigValidity" SG_ 2239851011 RSPA_EpbReq 3;
BA_ "RoutingFactor" SG_ 2239851011 RSPA_EpbReq 5;
BA_ "Version" SG_ 2239851011 RSPA_EpbReq "19.03.11";
BA_ "Description" SG_ 2239851011 RSPA_AddtnlAccelActv "RSPA additional acceleration control ON";
BA_ "UserSigValidity" SG_ 2239851011 RSPA_AddtnlAccelActv 3;
BA_ "RoutingFactor" SG_ 2239851011 RSPA_AddtnlAccelActv 5;
BA_ "Version" SG_ 2239851011 RSPA_AddtnlAccelActv "17.11.00";
BA_ "Description" SG_ 2239851011 RSPA_Opt "RSPA Option applied information";
BA_ "UserSigValidity" SG_ 2239851011 RSPA_Opt 3;
BA_ "RoutingFactor" SG_ 2239851011 RSPA_Opt 5;
BA_ "Version" SG_ 2239851011 RSPA_Opt "17.12.03";
BA_ "Description" SG_ 2239851011 RSPA_RmtPrlExitDis "Display remote parallel exit (RSPA II)";
BA_ "UserSigValidity" SG_ 2239851011 RSPA_RmtPrlExitDis 3;
BA_ "RoutingFactor" SG_ 2239851011 RSPA_RmtPrlExitDis 5;
BA_ "Version" SG_ 2239851011 RSPA_RmtPrlExitDis "19.08.08";
BA_ "Description" SG_ 2239851011 RSPA_TrgtTqVal "RSPA request EMS/HCU/VCU/FCU torque value (Nm)

Init value : 00h

If MSB is 1, this signal is - value.

else, this signal is +value.

0~10bit is used for absolute value.";
BA_ "UserSigValidity" SG_ 2239851011 RSPA_TrgtTqVal 3;
BA_ "RoutingFactor" SG_ 2239851011 RSPA_TrgtTqVal 5;
BA_ "Version" SG_ 2239851011 RSPA_TrgtTqVal "19.06.00";
BA_ "Description" SG_ 2239851011 RSPA_ExtLampReq "ÀüÁ¶µî, ¹æÇâÁö½Ãµî µ¿ÀÛ ¿äÃ» (RSPA ¿ë)

Type1:ºñ»óµî 1È¸ Normal Blinking

Type2:ºñ»óµî 2È¸ Normal Blinking

Type3:ºñ»óµî 3È¸ Normal Blinking

Type4:ºñ»óµî Áö¼ÓÀûÀ¸·Î Normal Blinking";
BA_ "UserSigValidity" SG_ 2239851011 RSPA_ExtLampReq 3;
BA_ "RoutingFactor" SG_ 2239851011 RSPA_ExtLampReq 5;
BA_ "Version" SG_ 2239851011 RSPA_ExtLampReq "17.11.00";
BA_ "Description" SG_ 2239851011 RSPA_UppLtTypDis "Parking type displayed on upper-left of AVN (RSPA II)";
BA_ "UserSigValidity" SG_ 2239851011 RSPA_UppLtTypDis 3;
BA_ "RoutingFactor" SG_ 2239851011 RSPA_UppLtTypDis 5;
BA_ "Version" SG_ 2239851011 RSPA_UppLtTypDis "20.03.04";
BA_ "Description" SG_ 2239851011 RSPA_LwrLtTypDis "Parking type displayed on lower-left of AVN (RSPA II)";
BA_ "UserSigValidity" SG_ 2239851011 RSPA_LwrLtTypDis 3;
BA_ "RoutingFactor" SG_ 2239851011 RSPA_LwrLtTypDis 5;
BA_ "Version" SG_ 2239851011 RSPA_LwrLtTypDis "20.03.04";
BA_ "Description" SG_ 2239851011 RSPA_UppRtTypDis "Parking type displayed on upper-right of AVN (RSPA II)";
BA_ "UserSigValidity" SG_ 2239851011 RSPA_UppRtTypDis 3;
BA_ "RoutingFactor" SG_ 2239851011 RSPA_UppRtTypDis 5;
BA_ "Version" SG_ 2239851011 RSPA_UppRtTypDis "19.08.08";
BA_ "Description" SG_ 2239851011 RSPA_LwrRtTypDis "Parking type displayed on lower-right of AVN (RSPA II)";
BA_ "UserSigValidity" SG_ 2239851011 RSPA_LwrRtTypDis 3;
BA_ "RoutingFactor" SG_ 2239851011 RSPA_LwrRtTypDis 5;
BA_ "Version" SG_ 2239851011 RSPA_LwrRtTypDis "19.08.08";
BA_ "Description" SG_ 2239851011 RSPA_CrankingReq "½Ãµ¿¸ðµå ÃµÀÌ ¿äÃ» (RSPA ¿ë)";
BA_ "UserSigValidity" SG_ 2239851011 RSPA_CrankingReq 3;
BA_ "RoutingFactor" SG_ 2239851011 RSPA_CrankingReq 5;
BA_ "Version" SG_ 2239851011 RSPA_CrankingReq "17.11.00";
BA_ "Description" SG_ 2239851009 ADAS_PRK_Crc3Val "The data area for CRC calculation is based on the data length (DLC) of the message DB.

The CRC shall be calculated over the entire data block (excluding the CRC bytes) including the user data, alive counter and Data ID



- CRC Polynomial (0x1021) , Ini";
BA_ "GenSigStartValue" SG_ 2239851009 ADAS_PRK_Crc3Val 65535;
BA_ "UserSigValidity" SG_ 2239851009 ADAS_PRK_Crc3Val 3;
BA_ "RoutingFactor" SG_ 2239851009 ADAS_PRK_Crc3Val 5;
BA_ "Version" SG_ 2239851009 ADAS_PRK_Crc3Val "21.09.03";
BA_ "Description" SG_ 2239851009 ADAS_PRK_AlvCnt3Val "For the first transmission request for a data element the counter shall be initialized with 0 and shall be incremented by 1 for every subsequent send request. 

When the counter reaches the maximum value(0xFF), then it shall restart with 0 for the next s";
BA_ "UserSigValidity" SG_ 2239851009 ADAS_PRK_AlvCnt3Val 3;
BA_ "RoutingFactor" SG_ 2239851009 ADAS_PRK_AlvCnt3Val 5;
BA_ "Version" SG_ 2239851009 ADAS_PRK_AlvCnt3Val "21.09.03";
BA_ "Description" SG_ 2239851009 RSPA_AvnDis "AVN È­¸é Ãâ·Â ¿äÃ» (RSPA ¿ë)

'-CGW routing ÇÊ¿ä (CCAN to MMCAN)";
BA_ "UserSigValidity" SG_ 2239851009 RSPA_AvnDis 3;
BA_ "RoutingFactor" SG_ 2239851009 RSPA_AvnDis 5;
BA_ "Version" SG_ 2239851009 RSPA_AvnDis "17.11.00";
BA_ "Description" SG_ 2239851009 RSPA_AvnModDis "AVN»óÀÇ ¸ðµå¼±ÅÃ ¸Þ´º Ç¥ÃâÀ» À§ÇÑ ÁÖÂ÷/ÃâÂ÷ ±¸ºÐ Á¤º¸

'-CGW routing ÇÊ¿ä (CCAN to MMCAN)";
BA_ "UserSigValidity" SG_ 2239851009 RSPA_AvnModDis 3;
BA_ "RoutingFactor" SG_ 2239851009 RSPA_AvnModDis 5;
BA_ "Version" SG_ 2239851009 RSPA_AvnModDis "17.11.00";
BA_ "Description" SG_ 2239851009 RSPA_AvnSubViewDis "AVN¿¡¼­ Ç¥ÃâÇØ¾ßÇÒ Topview¿µ¿ª ´ëÃ¼ÀÌ¹ÌÁö Ãâ·Â¿äÃ»

'-CGW routing ÇÊ¿ä (CCAN to MMCAN)";
BA_ "UserSigValidity" SG_ 2239851009 RSPA_AvnSubViewDis 3;
BA_ "RoutingFactor" SG_ 2239851009 RSPA_AvnSubViewDis 5;
BA_ "Version" SG_ 2239851009 RSPA_AvnSubViewDis "17.11.00";
BA_ "Description" SG_ 2239851009 RSPA_AvnHmiDis "AVN¿¡¼­ Ç¥ÃâÇÏ´Â RSPA HMI Ç¥½Ã Á¤º¸

'-CGW routing ÇÊ¿ä (CCAN to MMCAN)";
BA_ "UserSigValidity" SG_ 2239851009 RSPA_AvnHmiDis 3;
BA_ "RoutingFactor" SG_ 2239851009 RSPA_AvnHmiDis 5;
BA_ "Version" SG_ 2239851009 RSPA_AvnHmiDis "19.11.11";
BA_ "Description" SG_ 924 RLPSU_FailState_PopUp "2¿­ ÁÂÃø ½ÃÆ® µ¿ÀÛ ¿Ï·á ¹× ºÒ°¡ »óÈ² Á¤º¸ Ç¥½Ã¸¦ À§ÇÑ ¼Û½Å ½ÅÈ£";
BA_ "GenSigSendType" SG_ 924 RLPSU_FailState_PopUp 4;
BA_ "UserSigValidity" SG_ 924 RLPSU_FailState_PopUp 0;
BA_ "Version" SG_ 924 RLPSU_FailState_PopUp "21.07.06";
BA_ "Description" SG_ 924 RL_TLLnkRtnStop "In the event of an impossible situation during the seat movement in the 2nd row RL side by the 3rd row TL side Folding/UnFolding action.";
BA_ "GenSigSendType" SG_ 924 RL_TLLnkRtnStop 4;
BA_ "UserSigValidity" SG_ 924 RL_TLLnkRtnStop 0;
BA_ "NetworkRequest" SG_ 924 RL_TLLnkRtnStop 0;
BA_ "NetworkRequestHoldingTime" SG_ 924 RL_TLLnkRtnStop 5000;
BA_ "Version" SG_ 924 RL_TLLnkRtnStop "22.05.03";
BA_ "Description" SG_ 924 RL_1stLnkRtnStop "In the event of an impossible situation during the seat movement in the 2nd row RL side by the 1st row Seat Relaxion action.";
BA_ "GenSigSendType" SG_ 924 RL_1stLnkRtnStop 4;
BA_ "UserSigValidity" SG_ 924 RL_1stLnkRtnStop 0;
BA_ "NetworkRequest" SG_ 924 RL_1stLnkRtnStop 0;
BA_ "NetworkRequestHoldingTime" SG_ 924 RL_1stLnkRtnStop 5000;
BA_ "Version" SG_ 924 RL_1stLnkRtnStop "22.05.03";
BA_ "Description" SG_ 924 RLPSU_Folding_State_Popup_EC "Rear LH seat Folding State information";
BA_ "GenSigSendType" SG_ 924 RLPSU_Folding_State_Popup_EC 4;
BA_ "UserSigValidity" SG_ 924 RLPSU_Folding_State_Popup_EC 0;
BA_ "Version" SG_ 924 RLPSU_Folding_State_Popup_EC "21.07.06";
BA_ "Description" SG_ 924 RLPSU_Relax_State_Popup_EC "Rear LH seat Relax State information";
BA_ "GenSigSendType" SG_ 924 RLPSU_Relax_State_Popup_EC 4;
BA_ "UserSigValidity" SG_ 924 RLPSU_Relax_State_Popup_EC 0;
BA_ "Version" SG_ 924 RLPSU_Relax_State_Popup_EC "21.07.06";
BA_ "Description" SG_ 924 RLPSU_Reclining_State_Popup "RLPSU (2¿­ ÁÂÃø ÆÄ¿ö ¸®Å¬¶óÀÌ´×) µ¿ÀÛ ºÒ°¡ »óÅÂÀÇ OSD Ç¥½Ã";
BA_ "GenSigSendType" SG_ 924 RLPSU_Reclining_State_Popup 4;
BA_ "UserSigValidity" SG_ 924 RLPSU_Reclining_State_Popup 0;
BA_ "Version" SG_ 924 RLPSU_Reclining_State_Popup "21.07.06";
BA_ "Description" SG_ 924 RL_AstStStdPosMovReq "ÈÄ¼® LH ½ÃÆ® µ¿ÀÛ¿¡ µû¸¥ µ¿½Â¼® ÀÌµ¿ ¿äÃ» ½ÅÈ£";
BA_ "GenSigSendType" SG_ 924 RL_AstStStdPosMovReq 4;
BA_ "UserSigValidity" SG_ 924 RL_AstStStdPosMovReq 0;
BA_ "NetworkRequest" SG_ 924 RL_AstStStdPosMovReq 0;
BA_ "NetworkRequestHoldingTime" SG_ 924 RL_AstStStdPosMovReq 5000;
BA_ "Version" SG_ 924 RL_AstStStdPosMovReq "21.06.10";
BA_ "Description" SG_ 924 RL_TLStStdPosMovReq "2¿­ RLÃø ¸±·º¼Ç µ¿ÀÛ¿¡ ÀÇÇÑ 3¿­ TLÃø ½ÃÆ® ÀÌµ¿ ¿äÃ» ½ÅÈ£";
BA_ "GenSigSendType" SG_ 924 RL_TLStStdPosMovReq 4;
BA_ "UserSigValidity" SG_ 924 RL_TLStStdPosMovReq 0;
BA_ "NetworkRequest" SG_ 924 RL_TLStStdPosMovReq 0;
BA_ "NetworkRequestHoldingTime" SG_ 924 RL_TLStStdPosMovReq 5000;
BA_ "Version" SG_ 924 RL_TLStStdPosMovReq "22.05.02";
BA_ "Description" SG_ 924 RL_AstStStdPosMovReq_Fold "2¿­ RLÃø Æúµù/¾ðÆúµù µ¿ÀÛ¿¡ ÀÇÇÑ µ¿½Â¼® ½ÃÆ® ÀÌµ¿ ¿äÃ» ½ÅÈ£";
BA_ "GenSigSendType" SG_ 924 RL_AstStStdPosMovReq_Fold 4;
BA_ "UserSigValidity" SG_ 924 RL_AstStStdPosMovReq_Fold 0;
BA_ "NetworkRequest" SG_ 924 RL_AstStStdPosMovReq_Fold 0;
BA_ "NetworkRequestHoldingTime" SG_ 924 RL_AstStStdPosMovReq_Fold 5000;
BA_ "Version" SG_ 924 RL_AstStStdPosMovReq_Fold "22.05.02";
BA_ "Description" SG_ 922 RRPSU_FailState_PopUp "2¿­ ¿ìÃø½ÃÆ® µ¿ÀÛ¿Ï·á ¹× ºÒ°¡ »óÈ² Á¤º¸ Ç¥½Ã¸¦ À§ÇÑ ¼Û½Å ½ÅÈ£";
BA_ "GenSigSendType" SG_ 922 RRPSU_FailState_PopUp 4;
BA_ "UserSigValidity" SG_ 922 RRPSU_FailState_PopUp 0;
BA_ "Version" SG_ 922 RRPSU_FailState_PopUp "20.05.03";
BA_ "Description" SG_ 922 RR_TRLnkRtnStop "In the event of an impossible situation during the seat movement in the 2nd row RR side by the 3rd row TR side Folding/UnFolding action.";
BA_ "GenSigSendType" SG_ 922 RR_TRLnkRtnStop 4;
BA_ "UserSigValidity" SG_ 922 RR_TRLnkRtnStop 0;
BA_ "NetworkRequest" SG_ 922 RR_TRLnkRtnStop 0;
BA_ "NetworkRequestHoldingTime" SG_ 922 RR_TRLnkRtnStop 5000;
BA_ "Version" SG_ 922 RR_TRLnkRtnStop "22.05.03";
BA_ "Description" SG_ 922 RR_1stLnkRtnStop "In the event of an impossible situation during the seat movement in the 2nd row RR side by the 1st row Seat Relaxion action.";
BA_ "GenSigSendType" SG_ 922 RR_1stLnkRtnStop 4;
BA_ "UserSigValidity" SG_ 922 RR_1stLnkRtnStop 0;
BA_ "NetworkRequest" SG_ 922 RR_1stLnkRtnStop 0;
BA_ "NetworkRequestHoldingTime" SG_ 922 RR_1stLnkRtnStop 5000;
BA_ "Version" SG_ 922 RR_1stLnkRtnStop "22.05.03";
BA_ "Description" SG_ 922 RRPSU_Folding_State_Popup_EC "Rear RH seat Folding State information";
BA_ "GenSigSendType" SG_ 922 RRPSU_Folding_State_Popup_EC 4;
BA_ "UserSigValidity" SG_ 922 RRPSU_Folding_State_Popup_EC 0;
BA_ "Version" SG_ 922 RRPSU_Folding_State_Popup_EC "19.06.02";
BA_ "Description" SG_ 922 RRPSU_Relax_State_Popup_EC "Rear RH seat Relax State information";
BA_ "GenSigSendType" SG_ 922 RRPSU_Relax_State_Popup_EC 4;
BA_ "UserSigValidity" SG_ 922 RRPSU_Relax_State_Popup_EC 0;
BA_ "Version" SG_ 922 RRPSU_Relax_State_Popup_EC "19.06.02";
BA_ "Description" SG_ 922 RRPSU_Reclining_State_Popup "RRPSU (2¿­ ¿ìÃø ÆÄ¿ö ¸®Å¬¶óÀÌ´×) µ¿ÀÛ ºÒ°¡ »óÅÂÀÇ OSD Ç¥½Ã";
BA_ "GenSigSendType" SG_ 922 RRPSU_Reclining_State_Popup 4;
BA_ "UserSigValidity" SG_ 922 RRPSU_Reclining_State_Popup 0;
BA_ "Version" SG_ 922 RRPSU_Reclining_State_Popup "19.08.05";
BA_ "Description" SG_ 922 RR_AstStStdPosMovReq "ÈÄ¼® RH ½ÃÆ® µ¿ÀÛ¿¡ µû¸¥ µ¿½Â¼® ÀÌµ¿ ¿äÃ» ½ÅÈ£";
BA_ "GenSigSendType" SG_ 922 RR_AstStStdPosMovReq 4;
BA_ "UserSigValidity" SG_ 922 RR_AstStStdPosMovReq 0;
BA_ "NetworkRequest" SG_ 922 RR_AstStStdPosMovReq 0;
BA_ "NetworkRequestHoldingTime" SG_ 922 RR_AstStStdPosMovReq 5000;
BA_ "Version" SG_ 922 RR_AstStStdPosMovReq "21.06.10";
BA_ "Description" SG_ 922 RR_TRStStdPosMovReq "2¿­ RRÃø ¸±·º¼Ç µ¿ÀÛ¿¡ ÀÇÇÑ 3¿­ TRÃø ½ÃÆ® ÀÌµ¿ ¿äÃ» ½ÅÈ£";
BA_ "GenSigSendType" SG_ 922 RR_TRStStdPosMovReq 4;
BA_ "UserSigValidity" SG_ 922 RR_TRStStdPosMovReq 0;
BA_ "NetworkRequest" SG_ 922 RR_TRStStdPosMovReq 0;
BA_ "NetworkRequestHoldingTime" SG_ 922 RR_TRStStdPosMovReq 5000;
BA_ "Version" SG_ 922 RR_TRStStdPosMovReq "22.05.02";
BA_ "Description" SG_ 922 RR_AstStStdPosMovReq_Fold "2¿­ RRÃø Æúµù/¾ðÆúµù µ¿ÀÛ¿¡ ÀÇÇÑ µ¿½Â¼® ½ÃÆ® ÀÌµ¿ ¿äÃ» ½ÅÈ£";
BA_ "GenSigSendType" SG_ 922 RR_AstStStdPosMovReq_Fold 4;
BA_ "UserSigValidity" SG_ 922 RR_AstStStdPosMovReq_Fold 0;
BA_ "NetworkRequest" SG_ 922 RR_AstStStdPosMovReq_Fold 0;
BA_ "NetworkRequestHoldingTime" SG_ 922 RR_AstStStdPosMovReq_Fold 5000;
BA_ "Version" SG_ 922 RR_AstStStdPosMovReq_Fold "22.05.02";
BA_ "Description" SG_ 2424580609 DATC_Crc13Val "The data area for CRC calculation is based on the data length (DLC) of the message DB.

The CRC shall be calculated over the entire data block (excluding the CRC bytes) including the user data, alive counter and Data ID



- CRC Polynomial (0x1021) , Ini";
BA_ "GenSigSendType" SG_ 2424580609 DATC_Crc13Val 4;
BA_ "GenSigStartValue" SG_ 2424580609 DATC_Crc13Val 65535;
BA_ "UserSigValidity" SG_ 2424580609 DATC_Crc13Val 3;
BA_ "Version" SG_ 2424580609 DATC_Crc13Val "21.09.03";
BA_ "Description" SG_ 2424580609 DATC_AlvCnt13Val "For the first transmission request for a data element the counter shall be initialized with 0 and shall be incremented by 1 for every subsequent send request. 

When the counter reaches the maximum value(0xFF), then it shall restart with 0 for the next s";
BA_ "GenSigSendType" SG_ 2424580609 DATC_AlvCnt13Val 4;
BA_ "UserSigValidity" SG_ 2424580609 DATC_AlvCnt13Val 3;
BA_ "Version" SG_ 2424580609 DATC_AlvCnt13Val "21.09.03";
BA_ "GenSigSendType" SG_ 2424580609 DATC_MltAutoBlrTxt 4;
BA_ "UserSigValidity" SG_ 2424580609 DATC_MltAutoBlrTxt 7;
BA_ "Version" SG_ 2424580609 DATC_MltAutoBlrTxt "20.02.04";
BA_ "GenSigSendType" SG_ 2424580609 DATC_MltAutoBlrTxt_Ps 4;
BA_ "UserSigValidity" SG_ 2424580609 DATC_MltAutoBlrTxt_Ps 7;
BA_ "Version" SG_ 2424580609 DATC_MltAutoBlrTxt_Ps "20.02.04";
BA_ "GenSigSendType" SG_ 2424580609 DATC_MltAutoBlrTxt_Rr 4;
BA_ "UserSigValidity" SG_ 2424580609 DATC_MltAutoBlrTxt_Rr 7;
BA_ "Version" SG_ 2424580609 DATC_MltAutoBlrTxt_Rr "20.02.04";
BA_ "Description" SG_ 2424580609 DATC_RLStTmblrSwReq "Rear Left Seat heater & cooler tumbler S/W";
BA_ "GenSigSendType" SG_ 2424580609 DATC_RLStTmblrSwReq 4;
BA_ "UserSigValidity" SG_ 2424580609 DATC_RLStTmblrSwReq 7;
BA_ "Version" SG_ 2424580609 DATC_RLStTmblrSwReq "20.07.10";
BA_ "Description" SG_ 2424580609 DATC_RRStTmblrSwReq "Rear Right Seat heater & cooler tumbler S/W";
BA_ "GenSigSendType" SG_ 2424580609 DATC_RRStTmblrSwReq 4;
BA_ "UserSigValidity" SG_ 2424580609 DATC_RRStTmblrSwReq 7;
BA_ "Version" SG_ 2424580609 DATC_RRStTmblrSwReq "20.07.10";
BA_ "Description" SG_ 2424580609 DATC_DisPnlState "This signal is used to change the front(rear) climate control panel status to the rear(front) climate control panel state when the REAR button is pressed.";
BA_ "GenSigSendType" SG_ 2424580609 DATC_DisPnlState 4;
BA_ "UserSigValidity" SG_ 2424580609 DATC_DisPnlState 7;
BA_ "Version" SG_ 2424580609 DATC_DisPnlState "20.02.01";
BA_ "Description" SG_ 2424580609 DATC_Opt5Typ "This signal indicates Option of HTR Control.

Bit0 : (After Blow) : 0 - After Blow Not Applied / 1 - After Blow Applied

Bit1 : (Fragrance) : 0 ? Fragrance System Not Applied / 1 ? Fragrance System Applied

Bit2 : (Rear Climate Auto Off) : 0 - Rear Clima";
BA_ "GenSigSendType" SG_ 2424580609 DATC_Opt5Typ 4;
BA_ "UserSigValidity" SG_ 2424580609 DATC_Opt5Typ 7;
BA_ "Version" SG_ 2424580609 DATC_Opt5Typ "22.02.01";
BA_ "Description" SG_ 2424580609 DATC_BattPwrSum_Wh "accumulated energy consumption of battery while driving(200ms)";
BA_ "GenSigSendType" SG_ 2424580609 DATC_BattPwrSum_Wh 4;
BA_ "UserSigValidity" SG_ 2424580609 DATC_BattPwrSum_Wh 4;
BA_ "Version" SG_ 2424580609 DATC_BattPwrSum_Wh "18.09.00";
BA_ "Description" SG_ 2015 GST_ALL_Byte0 "TP Index : 0";
BA_ "UsrSigPurpose" SG_ 2015 GST_ALL_Byte0 0;
BA_ "UserSigValidity" SG_ 2015 GST_ALL_Byte0 0;
BA_ "NetworkRequest" SG_ 2015 GST_ALL_Byte0 0;
BA_ "NetworkRequestHoldingTime" SG_ 2015 GST_ALL_Byte0 5000;
BA_ "Version" SG_ 2015 GST_ALL_Byte0 "22.06.01";
BA_ "Description" SG_ 2015 GST_ALL_Byte2 "TP Index : 0";
BA_ "UsrSigPurpose" SG_ 2015 GST_ALL_Byte2 0;
BA_ "UserSigValidity" SG_ 2015 GST_ALL_Byte2 0;
BA_ "NetworkRequest" SG_ 2015 GST_ALL_Byte2 0;
BA_ "NetworkRequestHoldingTime" SG_ 2015 GST_ALL_Byte2 5000;
BA_ "Version" SG_ 2015 GST_ALL_Byte2 "22.06.01";
BA_ "Description" SG_ 2015 GST_ALL_Byte3 "TP Index : 0";
BA_ "UsrSigPurpose" SG_ 2015 GST_ALL_Byte3 0;
BA_ "UserSigValidity" SG_ 2015 GST_ALL_Byte3 0;
BA_ "NetworkRequest" SG_ 2015 GST_ALL_Byte3 0;
BA_ "NetworkRequestHoldingTime" SG_ 2015 GST_ALL_Byte3 5000;
BA_ "Version" SG_ 2015 GST_ALL_Byte3 "22.06.01";
BA_ "Description" SG_ 2015 GST_ALL_Byte4 "TP Index : 0";
BA_ "UsrSigPurpose" SG_ 2015 GST_ALL_Byte4 0;
BA_ "UserSigValidity" SG_ 2015 GST_ALL_Byte4 0;
BA_ "NetworkRequest" SG_ 2015 GST_ALL_Byte4 0;
BA_ "NetworkRequestHoldingTime" SG_ 2015 GST_ALL_Byte4 5000;
BA_ "Version" SG_ 2015 GST_ALL_Byte4 "22.06.01";
BA_ "Description" SG_ 2015 GST_ALL_Byte5 "TP Index : 0";
BA_ "UsrSigPurpose" SG_ 2015 GST_ALL_Byte5 0;
BA_ "UserSigValidity" SG_ 2015 GST_ALL_Byte5 0;
BA_ "NetworkRequest" SG_ 2015 GST_ALL_Byte5 0;
BA_ "NetworkRequestHoldingTime" SG_ 2015 GST_ALL_Byte5 5000;
BA_ "Version" SG_ 2015 GST_ALL_Byte5 "22.06.01";
BA_ "Description" SG_ 2015 GST_ALL_Byte6 "TP Index : 0";
BA_ "UsrSigPurpose" SG_ 2015 GST_ALL_Byte6 0;
BA_ "UserSigValidity" SG_ 2015 GST_ALL_Byte6 0;
BA_ "NetworkRequest" SG_ 2015 GST_ALL_Byte6 0;
BA_ "NetworkRequestHoldingTime" SG_ 2015 GST_ALL_Byte6 5000;
BA_ "Version" SG_ 2015 GST_ALL_Byte6 "22.06.01";
BA_ "Description" SG_ 2015 GST_ALL_Byte7 "TP Index : 0";
BA_ "UsrSigPurpose" SG_ 2015 GST_ALL_Byte7 0;
BA_ "UserSigValidity" SG_ 2015 GST_ALL_Byte7 0;
BA_ "NetworkRequest" SG_ 2015 GST_ALL_Byte7 0;
BA_ "NetworkRequestHoldingTime" SG_ 2015 GST_ALL_Byte7 5000;
BA_ "Version" SG_ 2015 GST_ALL_Byte7 "22.06.01";
BA_ "Description" SG_ 2015 GST_ALL_Byte1 "TP Index : 0";
BA_ "UsrSigPurpose" SG_ 2015 GST_ALL_Byte1 0;
BA_ "UserSigValidity" SG_ 2015 GST_ALL_Byte1 0;
BA_ "NetworkRequest" SG_ 2015 GST_ALL_Byte1 0;
BA_ "NetworkRequestHoldingTime" SG_ 2015 GST_ALL_Byte1 5000;
BA_ "Version" SG_ 2015 GST_ALL_Byte1 "22.06.01";
BA_ "Description" SG_ 915 BCM_Crc18Val "The data area for CRC calculation is based on the data length (DLC) of the message DB.

The CRC shall be calculated over the entire data block (excluding the CRC bytes) including the user data, alive counter and Data ID 

 

- CRC Polynomial (0x1D) , Ini";
BA_ "GenSigSendType" SG_ 915 BCM_Crc18Val 4;
BA_ "UserSigValidity" SG_ 915 BCM_Crc18Val 0;
BA_ "Version" SG_ 915 BCM_Crc18Val "21.09.03";
BA_ "Description" SG_ 915 BCM_AlvCnt18Val "For the first transmission request for a data element the counter shall be initialized with 0 and shall be incremented by 1

for every subsequent send request. When the counter reaches the maximum value(0xE), then it shall restart with 0 for the next sen";
BA_ "GenSigSendType" SG_ 915 BCM_AlvCnt18Val 4;
BA_ "UserSigValidity" SG_ 915 BCM_AlvCnt18Val 0;
BA_ "Version" SG_ 915 BCM_AlvCnt18Val "21.09.03";
BA_ "Description" SG_ 915 Trunk_IBU_OpnDiagSetSta "Trunk/TailGate open function diagnostic setting



 - Off : Normal mode

 - On : Restrict mode";
BA_ "GenSigSendType" SG_ 915 Trunk_IBU_OpnDiagSetSta 4;
BA_ "UserSigValidity" SG_ 915 Trunk_IBU_OpnDiagSetSta 0;
BA_ "NetworkRequest" SG_ 915 Trunk_IBU_OpnDiagSetSta 0;
BA_ "NetworkRequestHoldingTime" SG_ 915 Trunk_IBU_OpnDiagSetSta 5000;
BA_ "Version" SG_ 915 Trunk_IBU_OpnDiagSetSta "19.07.02";
BA_ "Description" SG_ 915 Trunk_TrnkTlgtReleaseRly "Trunk_TrunkTailgateOpenOutput for ICU

Trunk/Tailgate Release Relay Command

0x0:Off

0x1:On";
BA_ "GenSigSendType" SG_ 915 Trunk_TrnkTlgtReleaseRly 4;
BA_ "UserSigValidity" SG_ 915 Trunk_TrnkTlgtReleaseRly 0;
BA_ "NetworkRequest" SG_ 915 Trunk_TrnkTlgtReleaseRly 0;
BA_ "NetworkRequestHoldingTime" SG_ 915 Trunk_TrnkTlgtReleaseRly 5000;
BA_ "Version" SG_ 915 Trunk_TrnkTlgtReleaseRly "19.07.02";
BA_ "Description" SG_ 915 Trunk_TrnkTlgtOpenOutput_PTGM "Trunk_TrunkTailgateOpenOutput for PTGM

Trunk/Tailgate Open Command

0x0:Off

0x1:On";
BA_ "GenSigSendType" SG_ 915 Trunk_TrnkTlgtOpenOutput_PTGM 4;
BA_ "UserSigValidity" SG_ 915 Trunk_TrnkTlgtOpenOutput_PTGM 0;
BA_ "NetworkRequest" SG_ 915 Trunk_TrnkTlgtOpenOutput_PTGM 0;
BA_ "NetworkRequestHoldingTime" SG_ 915 Trunk_TrnkTlgtOpenOutput_PTGM 5000;
BA_ "Version" SG_ 915 Trunk_TrnkTlgtOpenOutput_PTGM "19.07.02";
BA_ "Description" SG_ 915 Trunk_TrnkTlgtOpenOutput_ICU "Trunk_TrunkTailgateOpenOutput for ICU

Trunk/Tailgate Open Command in PTG

0x0:Off

0x1:On";
BA_ "GenSigSendType" SG_ 915 Trunk_TrnkTlgtOpenOutput_ICU 4;
BA_ "UserSigValidity" SG_ 915 Trunk_TrnkTlgtOpenOutput_ICU 0;
BA_ "NetworkRequest" SG_ 915 Trunk_TrnkTlgtOpenOutput_ICU 0;
BA_ "NetworkRequestHoldingTime" SG_ 915 Trunk_TrnkTlgtOpenOutput_ICU 5000;
BA_ "Version" SG_ 915 Trunk_TrnkTlgtOpenOutput_ICU "19.07.02";
BA_ "Description" SG_ 915 Trunk_TrnkPassiveOpenOutput "Passive Trunk Open Output for ICU

Passive Trunk Release Relay Command

 - Off 

 - On";
BA_ "GenSigSendType" SG_ 915 Trunk_TrnkPassiveOpenOutput 4;
BA_ "UserSigValidity" SG_ 915 Trunk_TrnkPassiveOpenOutput 0;
BA_ "NetworkRequest" SG_ 915 Trunk_TrnkPassiveOpenOutput 0;
BA_ "NetworkRequestHoldingTime" SG_ 915 Trunk_TrnkPassiveOpenOutput 5000;
BA_ "Version" SG_ 915 Trunk_TrnkPassiveOpenOutput "19.07.02";
BA_ "Description" SG_ 915 TiltTele_CurProfileState "Current Profile ID State";
BA_ "GenSigSendType" SG_ 915 TiltTele_CurProfileState 4;
BA_ "UserSigValidity" SG_ 915 TiltTele_CurProfileState 0;
BA_ "NetworkRequest" SG_ 915 TiltTele_CurProfileState 0;
BA_ "NetworkRequestHoldingTime" SG_ 915 TiltTele_CurProfileState 500;
BA_ "Version" SG_ 915 TiltTele_CurProfileState "20.08.02";
BA_ "Description" SG_ 915 TiltTele_USMEsyAcsSetState "Easy Access Option USM Set Response";
BA_ "GenSigSendType" SG_ 915 TiltTele_USMEsyAcsSetState 4;
BA_ "UserSigValidity" SG_ 915 TiltTele_USMEsyAcsSetState 0;
BA_ "NetworkRequest" SG_ 915 TiltTele_USMEsyAcsSetState 0;
BA_ "NetworkRequestHoldingTime" SG_ 915 TiltTele_USMEsyAcsSetState 5000;
BA_ "Version" SG_ 915 TiltTele_USMEsyAcsSetState "20.08.02";
BA_ "Description" SG_ 915 TiltTele_PreEsyAcsProfile "Profile state for PreEasyAccess";
BA_ "GenSigSendType" SG_ 915 TiltTele_PreEsyAcsProfile 4;
BA_ "UserSigValidity" SG_ 915 TiltTele_PreEsyAcsProfile 0;
BA_ "NetworkRequest" SG_ 915 TiltTele_PreEsyAcsProfile 0;
BA_ "NetworkRequestHoldingTime" SG_ 915 TiltTele_PreEsyAcsProfile 5000;
BA_ "Version" SG_ 915 TiltTele_PreEsyAcsProfile "20.08.02";
BA_ "Description" SG_ 915 Tilt_MnlInitCmd "Command for Initialization by Tilt Manual Switch";
BA_ "GenSigSendType" SG_ 915 Tilt_MnlInitCmd 4;
BA_ "UserSigValidity" SG_ 915 Tilt_MnlInitCmd 0;
BA_ "NetworkRequest" SG_ 915 Tilt_MnlInitCmd 0;
BA_ "NetworkRequestHoldingTime" SG_ 915 Tilt_MnlInitCmd 5000;
BA_ "Version" SG_ 915 Tilt_MnlInitCmd "20.08.07";
BA_ "Description" SG_ 915 Tilt_MnlOpCmd "Command for Tilt Manual Operating";
BA_ "GenSigSendType" SG_ 915 Tilt_MnlOpCmd 4;
BA_ "UserSigValidity" SG_ 915 Tilt_MnlOpCmd 0;
BA_ "NetworkRequest" SG_ 915 Tilt_MnlOpCmd 0;
BA_ "NetworkRequestHoldingTime" SG_ 915 Tilt_MnlOpCmd 5000;
BA_ "Version" SG_ 915 Tilt_MnlOpCmd "20.08.07";
BA_ "Description" SG_ 915 Tele_MnlInitCmd "Command for Initialization by Tele Manual Switch";
BA_ "GenSigSendType" SG_ 915 Tele_MnlInitCmd 4;
BA_ "UserSigValidity" SG_ 915 Tele_MnlInitCmd 0;
BA_ "NetworkRequest" SG_ 915 Tele_MnlInitCmd 0;
BA_ "NetworkRequestHoldingTime" SG_ 915 Tele_MnlInitCmd 5000;
BA_ "Version" SG_ 915 Tele_MnlInitCmd "20.08.07";
BA_ "Description" SG_ 915 Tilt_AutoOpCmd "Command for Tilt Auto Operating";
BA_ "GenSigSendType" SG_ 915 Tilt_AutoOpCmd 4;
BA_ "UserSigValidity" SG_ 915 Tilt_AutoOpCmd 0;
BA_ "NetworkRequest" SG_ 915 Tilt_AutoOpCmd 0;
BA_ "NetworkRequestHoldingTime" SG_ 915 Tilt_AutoOpCmd 5000;
BA_ "Version" SG_ 915 Tilt_AutoOpCmd "22.07.05";
BA_ "Description" SG_ 915 TiltTele_PlyBckState "Steering Column Playback Status for IMS";
BA_ "GenSigSendType" SG_ 915 TiltTele_PlyBckState 4;
BA_ "UserSigValidity" SG_ 915 TiltTele_PlyBckState 0;
BA_ "NetworkRequest" SG_ 915 TiltTele_PlyBckState 0;
BA_ "NetworkRequestHoldingTime" SG_ 915 TiltTele_PlyBckState 5000;
BA_ "Version" SG_ 915 TiltTele_PlyBckState "20.08.02";
BA_ "Description" SG_ 915 Tele_MnlOpCmd "Command for Tele Manual Operating";
BA_ "GenSigSendType" SG_ 915 Tele_MnlOpCmd 4;
BA_ "UserSigValidity" SG_ 915 Tele_MnlOpCmd 0;
BA_ "NetworkRequest" SG_ 915 Tele_MnlOpCmd 0;
BA_ "NetworkRequestHoldingTime" SG_ 915 Tele_MnlOpCmd 5000;
BA_ "Version" SG_ 915 Tele_MnlOpCmd "20.08.07";
BA_ "Description" SG_ 915 Tele_AutoOpCmd "Command for Tele Auto Operating";
BA_ "GenSigSendType" SG_ 915 Tele_AutoOpCmd 4;
BA_ "UserSigValidity" SG_ 915 Tele_AutoOpCmd 0;
BA_ "NetworkRequest" SG_ 915 Tele_AutoOpCmd 0;
BA_ "NetworkRequestHoldingTime" SG_ 915 Tele_AutoOpCmd 5000;
BA_ "Version" SG_ 915 Tele_AutoOpCmd "22.07.05";
BA_ "Description" SG_ 912 HU_BLTN_CAM_UI_Mode "Display control of Built-in Cam UI mode. This Signal for Ethernet Type Built-in Cam.";
BA_ "GenSigSendType" SG_ 912 HU_BLTN_CAM_UI_Mode 4;
BA_ "UserSigValidity" SG_ 912 HU_BLTN_CAM_UI_Mode 0;
BA_ "RoutingFactor" SG_ 912 HU_BLTN_CAM_UI_Mode 0;
BA_ "Version" SG_ 912 HU_BLTN_CAM_UI_Mode "22.05.02";
BA_ "Description" SG_ 912 HU_BLTN_CAM_Display "Display control of Built-in Cam UI mode. This Signal for CAN Type Built-in Cam.(with Standard 5th Wide AVNT)";
BA_ "GenSigSendType" SG_ 912 HU_BLTN_CAM_Display 4;
BA_ "UserSigValidity" SG_ 912 HU_BLTN_CAM_Display 1;
BA_ "RoutingFactor" SG_ 912 HU_BLTN_CAM_Display 0;
BA_ "Version" SG_ 912 HU_BLTN_CAM_Display "21.05.02";
BA_REL_ "GenSigTimeoutTime" BU_SG_REL_ RLPSU SG_ 2035 GST_RLMSS_Byte0 0;
BA_REL_ "GenSigTimeoutTime" BU_SG_REL_ RLPSU SG_ 2035 GST_RLMSS_Byte2 0;
BA_REL_ "GenSigTimeoutTime" BU_SG_REL_ RLPSU SG_ 2035 GST_RLMSS_Byte3 0;
BA_REL_ "GenSigTimeoutTime" BU_SG_REL_ RLPSU SG_ 2035 GST_RLMSS_Byte4 0;
BA_REL_ "GenSigTimeoutTime" BU_SG_REL_ RLPSU SG_ 2035 GST_RLMSS_Byte5 0;
BA_REL_ "GenSigTimeoutTime" BU_SG_REL_ RLPSU SG_ 2035 GST_RLMSS_Byte6 0;
BA_REL_ "GenSigTimeoutTime" BU_SG_REL_ RLPSU SG_ 2035 GST_RLMSS_Byte7 0;
BA_REL_ "GenSigTimeoutTime" BU_SG_REL_ RLPSU SG_ 2035 GST_RLMSS_Byte1 0;
BA_REL_ "GenSigTimeoutTime" BU_SG_REL_ CGW_CCU SG_ 952 BLTN_CAM_Set_FR_Ver_Pos 1500;
BA_REL_ "GenSigTimeoutTime" BU_SG_REL_ CGW_CCU SG_ 952 BLTN_CAM_Set_PEV_AppNoti 1500;
BA_REL_ "GenSigTimeoutTime" BU_SG_REL_ CGW_CCU SG_ 952 BLTN_CAM_Set_WiFi_AutoOn 1500;
BA_REL_ "GenSigTimeoutTime" BU_SG_REL_ CGW_CCU SG_ 952 BLTN_CAM_StrgPropSet 1500;
BA_REL_ "GenSigTimeoutTime" BU_SG_REL_ CGW_CCU SG_ 952 BLTN_CAM_File_DEL_CPY_Op_State 1500;
BA_REL_ "GenSigTimeoutTime" BU_SG_REL_ CGW_CCU SG_ 952 BLTN_CAM_File_DEL_CPY_NumTot 1500;
BA_REL_ "GenSigTimeoutTime" BU_SG_REL_ CGW_CCU SG_ 952 BLTN_CAM_File_DEL_CPYed_Num 1500;
BA_REL_ "GenSigTimeoutTime" BU_SG_REL_ CGW_CCU SG_ 952 BLTN_CAM_Set_RR_Ver_Pos 1500;
BA_REL_ "GenSigTimeoutTime" BU_SG_REL_ CGW_CCU SG_ 2040 RRMSU_GST_Byte0 0;
BA_REL_ "GenSigTimeoutTime" BU_SG_REL_ CGW_CCU SG_ 2040 RRMSU_GST_Byte2 0;
BA_REL_ "GenSigTimeoutTime" BU_SG_REL_ CGW_CCU SG_ 2040 RRMSU_GST_Byte3 0;
BA_REL_ "GenSigTimeoutTime" BU_SG_REL_ CGW_CCU SG_ 2040 RRMSU_GST_Byte4 0;
BA_REL_ "GenSigTimeoutTime" BU_SG_REL_ CGW_CCU SG_ 2040 RRMSU_GST_Byte5 0;
BA_REL_ "GenSigTimeoutTime" BU_SG_REL_ CGW_CCU SG_ 2040 RRMSU_GST_Byte6 0;
BA_REL_ "GenSigTimeoutTime" BU_SG_REL_ CGW_CCU SG_ 2040 RRMSU_GST_Byte7 0;
BA_REL_ "GenSigTimeoutTime" BU_SG_REL_ CGW_CCU SG_ 2040 RRMSU_GST_Byte1 0;
BA_REL_ "GenSigTimeoutTime" BU_SG_REL_ CGW_CCU SG_ 2041 RRMSS_GST_Byte0 0;
BA_REL_ "GenSigTimeoutTime" BU_SG_REL_ CGW_CCU SG_ 2041 RRMSS_GST_Byte2 0;
BA_REL_ "GenSigTimeoutTime" BU_SG_REL_ CGW_CCU SG_ 2041 RRMSS_GST_Byte3 0;
BA_REL_ "GenSigTimeoutTime" BU_SG_REL_ CGW_CCU SG_ 2041 RRMSS_GST_Byte4 0;
BA_REL_ "GenSigTimeoutTime" BU_SG_REL_ CGW_CCU SG_ 2041 RRMSS_GST_Byte5 0;
BA_REL_ "GenSigTimeoutTime" BU_SG_REL_ CGW_CCU SG_ 2041 RRMSS_GST_Byte6 0;
BA_REL_ "GenSigTimeoutTime" BU_SG_REL_ CGW_CCU SG_ 2041 RRMSS_GST_Byte7 0;
BA_REL_ "GenSigTimeoutTime" BU_SG_REL_ CGW_CCU SG_ 2041 RRMSS_GST_Byte1 0;
BA_REL_ "GenSigTimeoutTime" BU_SG_REL_ CGW_CCU SG_ 950 BLTN_CAM_State 1500;
BA_REL_ "GenSigTimeoutTime" BU_SG_REL_ CGW_CCU SG_ 950 BLTN_CAM_RecSta_DEV 1500;
BA_REL_ "GenSigTimeoutTime" BU_SG_REL_ CGW_CCU SG_ 950 BLTN_CAM_RecSta_MAR 1500;
BA_REL_ "GenSigTimeoutTime" BU_SG_REL_ CGW_CCU SG_ 950 BLTN_CAM_RecSta_TML 1500;
BA_REL_ "GenSigTimeoutTime" BU_SG_REL_ CGW_CCU SG_ 950 BLTN_CAM_RecSta_OWP 1500;
BA_REL_ "GenSigTimeoutTime" BU_SG_REL_ CGW_CCU SG_ 950 BLTN_CAM_RecSta_PEV 1500;
BA_REL_ "GenSigTimeoutTime" BU_SG_REL_ CGW_CCU SG_ 950 BLTN_CAM_Prk_EV_Cnt 1500;
BA_REL_ "GenSigTimeoutTime" BU_SG_REL_ CGW_CCU SG_ 950 BLTN_CAM_Prk_Oped_Time 1500;
BA_REL_ "GenSigTimeoutTime" BU_SG_REL_ CGW_CCU SG_ 950 BLTN_CAM_Prk_Oprable_Time 1500;
BA_REL_ "GenSigTimeoutTime" BU_SG_REL_ CGW_CCU SG_ 950 BLTN_CAM_SD_Card_State 1500;
BA_REL_ "GenSigTimeoutTime" BU_SG_REL_ CGW_CCU SG_ 950 BLTN_CAM_Prk_Oprable_Time_Max 1500;
BA_REL_ "GenSigTimeoutTime" BU_SG_REL_ CGW_CCU SG_ 950 BLTN_CAM_AuxBat_Conn_State 1500;
BA_REL_ "GenSigTimeoutTime" BU_SG_REL_ CGW_CCU SG_ 950 BLTN_CAM_AuxBat_CapPer 1500;
BA_REL_ "GenSigTimeoutTime" BU_SG_REL_ CGW_CCU SG_ 950 BLTN_CAM_RecSta_OWD 1500;
BA_REL_ "GenSigTimeoutTime" BU_SG_REL_ CGW_CCU SG_ 951 BLTN_CAM_RecSet_OWD 1500;
BA_REL_ "GenSigTimeoutTime" BU_SG_REL_ CGW_CCU SG_ 951 BLTN_CAM_Set_Tim_Stm 1500;
BA_REL_ "GenSigTimeoutTime" BU_SG_REL_ CGW_CCU SG_ 951 BLTN_CAM_Set_Spd_Stm 1500;
BA_REL_ "GenSigTimeoutTime" BU_SG_REL_ CGW_CCU SG_ 951 BLTN_CAM_Set_Locatn_Stm 1500;
BA_REL_ "GenSigTimeoutTime" BU_SG_REL_ CGW_CCU SG_ 951 BLTN_CAM_Set_TrnSig_Stm 1500;
BA_REL_ "GenSigTimeoutTime" BU_SG_REL_ CGW_CCU SG_ 951 BLTN_CAM_Set_AclBrk_Stm 1500;
BA_REL_ "GenSigTimeoutTime" BU_SG_REL_ CGW_CCU SG_ 951 BLTN_CAM_RecSet_DEV 1500;
BA_REL_ "GenSigTimeoutTime" BU_SG_REL_ CGW_CCU SG_ 951 BLTN_CAM_Set_GearPos_Stm 1500;
BA_REL_ "GenSigTimeoutTime" BU_SG_REL_ CGW_CCU SG_ 951 BLTN_CAM_Set_EVSen_Stm 1500;
BA_REL_ "GenSigTimeoutTime" BU_SG_REL_ CGW_CCU SG_ 951 BLTN_CAM_Set_StrAngl_Stm 1500;
BA_REL_ "GenSigTimeoutTime" BU_SG_REL_ CGW_CCU SG_ 951 BLTN_CAM_Set_PrkTime 1500;
BA_REL_ "GenSigTimeoutTime" BU_SG_REL_ CGW_CCU SG_ 951 BLTN_CAM_Set_EV_BfrTime 1500;
BA_REL_ "GenSigTimeoutTime" BU_SG_REL_ CGW_CCU SG_ 951 BLTN_CAM_RecSet_OWP 1500;
BA_REL_ "GenSigTimeoutTime" BU_SG_REL_ CGW_CCU SG_ 951 BLTN_CAM_Set_EV_AftTime 1500;
BA_REL_ "GenSigTimeoutTime" BU_SG_REL_ CGW_CCU SG_ 951 BLTN_CAM_Set_Drv_TML_Int 1500;
BA_REL_ "GenSigTimeoutTime" BU_SG_REL_ CGW_CCU SG_ 951 BLTN_CAM_SenSet_DEV 1500;
BA_REL_ "GenSigTimeoutTime" BU_SG_REL_ CGW_CCU SG_ 951 BLTN_CAM_SenSet_PEV 1500;
BA_REL_ "GenSigTimeoutTime" BU_SG_REL_ CGW_CCU SG_ 951 BLTN_CAM_RecSet_PEV 1500;
BA_REL_ "GenSigTimeoutTime" BU_SG_REL_ CGW_CCU SG_ 951 BLTN_CAM_AudRec_Set 1500;
BA_REL_ "GenSigTimeoutTime" BU_SG_REL_ CGW_CCU SG_ 2045 RLMSU_GST_Byte0 0;
BA_REL_ "GenSigTimeoutTime" BU_SG_REL_ CGW_CCU SG_ 2045 RLMSU_GST_Byte2 0;
BA_REL_ "GenSigTimeoutTime" BU_SG_REL_ CGW_CCU SG_ 2045 RLMSU_GST_Byte3 0;
BA_REL_ "GenSigTimeoutTime" BU_SG_REL_ CGW_CCU SG_ 2045 RLMSU_GST_Byte4 0;
BA_REL_ "GenSigTimeoutTime" BU_SG_REL_ CGW_CCU SG_ 2045 RLMSU_GST_Byte5 0;
BA_REL_ "GenSigTimeoutTime" BU_SG_REL_ CGW_CCU SG_ 2045 RLMSU_GST_Byte6 0;
BA_REL_ "GenSigTimeoutTime" BU_SG_REL_ CGW_CCU SG_ 2045 RLMSU_GST_Byte7 0;
BA_REL_ "GenSigTimeoutTime" BU_SG_REL_ CGW_CCU SG_ 2045 RLMSU_GST_Byte1 0;
BA_REL_ "GenSigTimeoutTime" BU_SG_REL_ OHCL SG_ 2281835009 ACU_Crc1Val 1500;
BA_REL_ "GenSigTimeoutTime" BU_SG_REL_ OHCL SG_ 2281835009 ACU_AlvCnt1Val 1500;
BA_REL_ "GenSigTimeoutTime" BU_SG_REL_ OHCL SG_ 2281835009 ACU_TlltlLmpDis 1500;
BA_REL_ "GenSigTimeoutTime" BU_SG_REL_ PSB SG_ 2281835009 SeatBelt_PassBcklFltSta 1500;
BA_REL_ "GenSigTimeoutTime" BU_SG_REL_ PSB SG_ 2281835009 SeatBelt_DrvrBcklFltSta 1500;
BA_REL_ "GenSigTimeoutTime" BU_SG_REL_ PSB SG_ 2281835009 SeatBelt_PassBcklSta 1500;
BA_REL_ "GenSigTimeoutTime" BU_SG_REL_ APSU SG_ 2281835009 SeatBelt_PassBcklSta 1500;
BA_REL_ "GenSigTimeoutTime" BU_SG_REL_ ATS SG_ 2281835009 SeatBelt_PassBcklSta 1500;
BA_REL_ "GenSigTimeoutTime" BU_SG_REL_ PSB SG_ 2281835009 SeatBelt_DrvrBcklSta 1500;
BA_REL_ "GenSigTimeoutTime" BU_SG_REL_ CGW_CCU SG_ 2046 RLMSS_GST_Byte0 0;
BA_REL_ "GenSigTimeoutTime" BU_SG_REL_ CGW_CCU SG_ 2046 RLMSS_GST_Byte2 0;
BA_REL_ "GenSigTimeoutTime" BU_SG_REL_ CGW_CCU SG_ 2046 RLMSS_GST_Byte3 0;
BA_REL_ "GenSigTimeoutTime" BU_SG_REL_ CGW_CCU SG_ 2046 RLMSS_GST_Byte4 0;
BA_REL_ "GenSigTimeoutTime" BU_SG_REL_ CGW_CCU SG_ 2046 RLMSS_GST_Byte5 0;
BA_REL_ "GenSigTimeoutTime" BU_SG_REL_ CGW_CCU SG_ 2046 RLMSS_GST_Byte6 0;
BA_REL_ "GenSigTimeoutTime" BU_SG_REL_ CGW_CCU SG_ 2046 RLMSS_GST_Byte7 0;
BA_REL_ "GenSigTimeoutTime" BU_SG_REL_ CGW_CCU SG_ 2046 RLMSS_GST_Byte1 0;
BA_REL_ "GenSigTimeoutTime" BU_SG_REL_ ATS SG_ 942 AMP_Beep1VolumeStep 0;
BA_REL_ "GenSigTimeoutTime" BU_SG_REL_ CGW_CCU SG_ 939 PSB_Crc1Val 1500;
BA_REL_ "GenSigTimeoutTime" BU_SG_REL_ CGW_CCU SG_ 939 PSB_AlvCnt1Val 1500;
BA_REL_ "GenSigTimeoutTime" BU_SG_REL_ CGW_CCU SG_ 939 PSB_LHFlrSta 1500;
BA_REL_ "GenSigTimeoutTime" BU_SG_REL_ CGW_CCU SG_ 939 PSB_LHActvSta 1500;
BA_REL_ "GenSigTimeoutTime" BU_SG_REL_ CGW_CCU SG_ 939 PSB_RHFlrSta 1500;
BA_REL_ "GenSigTimeoutTime" BU_SG_REL_ APSU SG_ 939 PSB_RHActvSta 1500;
BA_REL_ "GenSigTimeoutTime" BU_SG_REL_ CGW_CCU SG_ 939 PSB_RHActvSta 1500;
BA_REL_ "GenSigTimeoutTime" BU_SG_REL_ CGW_CCU SG_ 939 PSB_ActForAcu 1500;
BA_REL_ "GenSigTimeoutTime" BU_SG_REL_ CGW_CCU SG_ 939 PSB_HapticWarnSta 1500;
BA_REL_ "GenSigTimeoutTime" BU_SG_REL_ APSU SG_ 939 PSB_RHActForPss 1500;
BA_REL_ "GenSigTimeoutTime" BU_SG_REL_ RLPSU SG_ 939 PSB_RHActForPss 1500;
BA_REL_ "GenSigTimeoutTime" BU_SG_REL_ RRPSU SG_ 939 PSB_RHActForPss 1500;
BA_REL_ "GenSigTimeoutTime" BU_SG_REL_ CGW_CCU SG_ 939 PSB_HDPSpprtSWVer 1500;
BA_REL_ "GenSigTimeoutTime" BU_SG_REL_ RLPSU SG_ 939 PSB_LHActForPss 1500;
BA_REL_ "GenSigTimeoutTime" BU_SG_REL_ RRPSU SG_ 939 PSB_LHActForPss 1500;
BA_REL_ "GenSigTimeoutTime" BU_SG_REL_ APSU SG_ 934 PTGM_ReleaseRlySta 1500;
BA_REL_ "GenSigTimeoutTime" BU_SG_REL_ PFSU SG_ 934 PTGM_ReleaseRlySta 1500;
BA_REL_ "GenSigTimeoutTime" BU_SG_REL_ DPSU SG_ 929 SCM_Opt 1500;
BA_REL_ "GenSigTimeoutTime" BU_SG_REL_ CGW_CCU SG_ 929 SCM_Opt 1500;
BA_REL_ "GenSigTimeoutTime" BU_SG_REL_ CGW_CCU SG_ 929 Tilt_VirtualLimExist 1500;
BA_REL_ "GenSigTimeoutTime" BU_SG_REL_ CGW_CCU SG_ 929 Tele_SnsrErr 1500;
BA_REL_ "GenSigTimeoutTime" BU_SG_REL_ CGW_CCU SG_ 929 Tele_VirtualLim 1500;
BA_REL_ "GenSigTimeoutTime" BU_SG_REL_ CGW_CCU SG_ 929 Tele_VirtualLimExist 1500;
BA_REL_ "GenSigTimeoutTime" BU_SG_REL_ CGW_CCU SG_ 929 TiltTele_Profile1MemoryExist 1500;
BA_REL_ "GenSigTimeoutTime" BU_SG_REL_ CGW_CCU SG_ 929 Tilt_MnlSwSta 1500;
BA_REL_ "GenSigTimeoutTime" BU_SG_REL_ CGW_CCU SG_ 929 TiltTele_Profile2MemoryExist 1500;
BA_REL_ "GenSigTimeoutTime" BU_SG_REL_ CGW_CCU SG_ 929 TiltTele_GuestMemoryExist 1500;
BA_REL_ "GenSigTimeoutTime" BU_SG_REL_ CGW_CCU SG_ 929 TiltTele_IMS1MemoryExist 1500;
BA_REL_ "GenSigTimeoutTime" BU_SG_REL_ CGW_CCU SG_ 929 TiltTele_IMS2MemoryExist 1500;
BA_REL_ "GenSigTimeoutTime" BU_SG_REL_ CGW_CCU SG_ 929 TiltTele_IMS3MemoryExist 1500;
BA_REL_ "GenSigTimeoutTime" BU_SG_REL_ CGW_CCU SG_ 929 TiltTele_ReturnMemoryExist 1500;
BA_REL_ "GenSigTimeoutTime" BU_SG_REL_ CGW_CCU SG_ 929 Tilt_OpSta 1500;
BA_REL_ "GenSigTimeoutTime" BU_SG_REL_ CGW_CCU SG_ 929 Tele_OpSta 1500;
BA_REL_ "GenSigTimeoutTime" BU_SG_REL_ CGW_CCU SG_ 929 Tele_MnlSwSta 1500;
BA_REL_ "GenSigTimeoutTime" BU_SG_REL_ CGW_CCU SG_ 929 Tilt_SnsrErr 1500;
BA_REL_ "GenSigTimeoutTime" BU_SG_REL_ CGW_CCU SG_ 929 Tilt_VirtualLim 1500;
BA_REL_ "GenSigTimeoutTime" BU_SG_REL_ DPSU SG_ 2239851011 RSPA_IdOutWarnReq 1500;
BA_REL_ "GenSigTimeoutTime" BU_SG_REL_ CGW_CCU SG_ 924 RLPSU_FailState_PopUp 0;
BA_REL_ "GenSigTimeoutTime" BU_SG_REL_ PFSU SG_ 924 RL_TLLnkRtnStop 0;
BA_REL_ "GenSigTimeoutTime" BU_SG_REL_ APSU SG_ 924 RL_1stLnkRtnStop 0;
BA_REL_ "GenSigTimeoutTime" BU_SG_REL_ DPSU SG_ 924 RL_1stLnkRtnStop 0;
BA_REL_ "GenSigTimeoutTime" BU_SG_REL_ CGW_CCU SG_ 924 RLPSU_Folding_State_Popup_EC 0;
BA_REL_ "GenSigTimeoutTime" BU_SG_REL_ APSU SG_ 924 RL_AstStStdPosMovReq 0;
BA_REL_ "GenSigTimeoutTime" BU_SG_REL_ PFSU SG_ 924 RL_TLStStdPosMovReq 0;
BA_REL_ "GenSigTimeoutTime" BU_SG_REL_ APSU SG_ 924 RL_AstStStdPosMovReq_Fold 0;
BA_REL_ "GenSigTimeoutTime" BU_SG_REL_ CGW_CCU SG_ 922 RRPSU_FailState_PopUp 0;
BA_REL_ "GenSigTimeoutTime" BU_SG_REL_ PFSU SG_ 922 RR_TRLnkRtnStop 0;
BA_REL_ "GenSigTimeoutTime" BU_SG_REL_ APSU SG_ 922 RR_1stLnkRtnStop 0;
BA_REL_ "GenSigTimeoutTime" BU_SG_REL_ DPSU SG_ 922 RR_1stLnkRtnStop 0;
BA_REL_ "GenSigTimeoutTime" BU_SG_REL_ CGW_CCU SG_ 922 RRPSU_Folding_State_Popup_EC 0;
BA_REL_ "GenSigTimeoutTime" BU_SG_REL_ APSU SG_ 922 RR_AstStStdPosMovReq 0;
BA_REL_ "GenSigTimeoutTime" BU_SG_REL_ PFSU SG_ 922 RR_TRStStdPosMovReq 0;
BA_REL_ "GenSigTimeoutTime" BU_SG_REL_ APSU SG_ 922 RR_AstStStdPosMovReq_Fold 0;
BA_REL_ "GenSigTimeoutTime" BU_SG_REL_ ATS SG_ 2424580609 DATC_MltAutoBlrTxt 1500;
BA_REL_ "GenSigTimeoutTime" BU_SG_REL_ ATS SG_ 2424580609 DATC_MltAutoBlrTxt_Ps 1500;
BA_REL_ "GenSigTimeoutTime" BU_SG_REL_ ATS SG_ 2424580609 DATC_MltAutoBlrTxt_Rr 1500;
BA_REL_ "GenSigTimeoutTime" BU_SG_REL_ RLHV SG_ 2424580609 DATC_RLStTmblrSwReq 1500;
BA_REL_ "GenSigTimeoutTime" BU_SG_REL_ RRHV SG_ 2424580609 DATC_RLStTmblrSwReq 1500;
BA_REL_ "GenSigTimeoutTime" BU_SG_REL_ SHVU_FR SG_ 2424580609 DATC_RLStTmblrSwReq 1500;
BA_REL_ "GenSigTimeoutTime" BU_SG_REL_ SHVU_RR SG_ 2424580609 DATC_RLStTmblrSwReq 1500;
BA_REL_ "GenSigTimeoutTime" BU_SG_REL_ RLPSU SG_ 2424580609 DATC_RLStTmblrSwReq 1500;
BA_REL_ "GenSigTimeoutTime" BU_SG_REL_ RRHV SG_ 2424580609 DATC_RRStTmblrSwReq 1500;
BA_REL_ "GenSigTimeoutTime" BU_SG_REL_ SHVU_FR SG_ 2424580609 DATC_RRStTmblrSwReq 1500;
BA_REL_ "GenSigTimeoutTime" BU_SG_REL_ SHVU_RR SG_ 2424580609 DATC_RRStTmblrSwReq 1500;
BA_REL_ "GenSigTimeoutTime" BU_SG_REL_ RRPSU SG_ 2424580609 DATC_RRStTmblrSwReq 1500;
BA_REL_ "GenSigTimeoutTime" BU_SG_REL_ ATS SG_ 2424580609 DATC_Opt5Typ 1500;
BA_REL_ "GenSigTimeoutTime" BU_SG_REL_ FCS SG_ 2015 GST_ALL_Byte0 0;
BA_REL_ "GenSigTimeoutTime" BU_SG_REL_ SCM SG_ 2015 GST_ALL_Byte0 0;
BA_REL_ "GenSigTimeoutTime" BU_SG_REL_ WPC SG_ 2015 GST_ALL_Byte0 0;
BA_REL_ "GenSigTimeoutTime" BU_SG_REL_ RWPC SG_ 2015 GST_ALL_Byte0 0;
BA_REL_ "GenSigTimeoutTime" BU_SG_REL_ PSB SG_ 2015 GST_ALL_Byte0 0;
BA_REL_ "GenSigTimeoutTime" BU_SG_REL_ SLB SG_ 2015 GST_ALL_Byte0 0;
BA_REL_ "GenSigTimeoutTime" BU_SG_REL_ ARS SG_ 2015 GST_ALL_Byte0 0;
BA_REL_ "GenSigTimeoutTime" BU_SG_REL_ SWRC SG_ 2015 GST_ALL_Byte0 0;
BA_REL_ "GenSigTimeoutTime" BU_SG_REL_ APSU SG_ 2015 GST_ALL_Byte0 0;
BA_REL_ "GenSigTimeoutTime" BU_SG_REL_ RLHV SG_ 2015 GST_ALL_Byte0 0;
BA_REL_ "GenSigTimeoutTime" BU_SG_REL_ RRHV SG_ 2015 GST_ALL_Byte0 0;
BA_REL_ "GenSigTimeoutTime" BU_SG_REL_ SHVU_FR SG_ 2015 GST_ALL_Byte0 0;
BA_REL_ "GenSigTimeoutTime" BU_SG_REL_ SHVU_RR SG_ 2015 GST_ALL_Byte0 0;
BA_REL_ "GenSigTimeoutTime" BU_SG_REL_ DPSU SG_ 2015 GST_ALL_Byte0 0;
BA_REL_ "GenSigTimeoutTime" BU_SG_REL_ DLBCU SG_ 2015 GST_ALL_Byte0 0;
BA_REL_ "GenSigTimeoutTime" BU_SG_REL_ PFSU SG_ 2015 GST_ALL_Byte0 0;
BA_REL_ "GenSigTimeoutTime" BU_SG_REL_ RCS SG_ 2015 GST_ALL_Byte0 0;
BA_REL_ "GenSigTimeoutTime" BU_SG_REL_ RRPSU SG_ 2015 GST_ALL_Byte0 0;
BA_REL_ "GenSigTimeoutTime" BU_SG_REL_ RLPSU SG_ 2015 GST_ALL_Byte0 0;
BA_REL_ "GenSigTimeoutTime" BU_SG_REL_ HOD SG_ 2015 GST_ALL_Byte0 0;
BA_REL_ "GenSigTimeoutTime" BU_SG_REL_ ATS SG_ 2015 GST_ALL_Byte0 0;
BA_REL_ "GenSigTimeoutTime" BU_SG_REL_ DSAU SG_ 2015 GST_ALL_Byte0 0;
BA_REL_ "GenSigTimeoutTime" BU_SG_REL_ ASAU SG_ 2015 GST_ALL_Byte0 0;
BA_REL_ "GenSigTimeoutTime" BU_SG_REL_ RCM SG_ 2015 GST_ALL_Byte0 0;
BA_REL_ "GenSigTimeoutTime" BU_SG_REL_ EMCU SG_ 2015 GST_ALL_Byte0 0;
BA_REL_ "GenSigTimeoutTime" BU_SG_REL_ SGU SG_ 2015 GST_ALL_Byte0 0;
BA_REL_ "GenSigTimeoutTime" BU_SG_REL_ ALBCU SG_ 2015 GST_ALL_Byte0 0;
BA_REL_ "GenSigTimeoutTime" BU_SG_REL_ WPC2 SG_ 2015 GST_ALL_Byte0 0;
BA_REL_ "GenSigTimeoutTime" BU_SG_REL_ FCS SG_ 2015 GST_ALL_Byte2 0;
BA_REL_ "GenSigTimeoutTime" BU_SG_REL_ SCM SG_ 2015 GST_ALL_Byte2 0;
BA_REL_ "GenSigTimeoutTime" BU_SG_REL_ WPC SG_ 2015 GST_ALL_Byte2 0;
BA_REL_ "GenSigTimeoutTime" BU_SG_REL_ RWPC SG_ 2015 GST_ALL_Byte2 0;
BA_REL_ "GenSigTimeoutTime" BU_SG_REL_ PSB SG_ 2015 GST_ALL_Byte2 0;
BA_REL_ "GenSigTimeoutTime" BU_SG_REL_ SLB SG_ 2015 GST_ALL_Byte2 0;
BA_REL_ "GenSigTimeoutTime" BU_SG_REL_ ARS SG_ 2015 GST_ALL_Byte2 0;
BA_REL_ "GenSigTimeoutTime" BU_SG_REL_ SWRC SG_ 2015 GST_ALL_Byte2 0;
BA_REL_ "GenSigTimeoutTime" BU_SG_REL_ APSU SG_ 2015 GST_ALL_Byte2 0;
BA_REL_ "GenSigTimeoutTime" BU_SG_REL_ RLHV SG_ 2015 GST_ALL_Byte2 0;
BA_REL_ "GenSigTimeoutTime" BU_SG_REL_ RRHV SG_ 2015 GST_ALL_Byte2 0;
BA_REL_ "GenSigTimeoutTime" BU_SG_REL_ SHVU_FR SG_ 2015 GST_ALL_Byte2 0;
BA_REL_ "GenSigTimeoutTime" BU_SG_REL_ SHVU_RR SG_ 2015 GST_ALL_Byte2 0;
BA_REL_ "GenSigTimeoutTime" BU_SG_REL_ DPSU SG_ 2015 GST_ALL_Byte2 0;
BA_REL_ "GenSigTimeoutTime" BU_SG_REL_ DLBCU SG_ 2015 GST_ALL_Byte2 0;
BA_REL_ "GenSigTimeoutTime" BU_SG_REL_ PFSU SG_ 2015 GST_ALL_Byte2 0;
BA_REL_ "GenSigTimeoutTime" BU_SG_REL_ RCS SG_ 2015 GST_ALL_Byte2 0;
BA_REL_ "GenSigTimeoutTime" BU_SG_REL_ RRPSU SG_ 2015 GST_ALL_Byte2 0;
BA_REL_ "GenSigTimeoutTime" BU_SG_REL_ RLPSU SG_ 2015 GST_ALL_Byte2 0;
BA_REL_ "GenSigTimeoutTime" BU_SG_REL_ HOD SG_ 2015 GST_ALL_Byte2 0;
BA_REL_ "GenSigTimeoutTime" BU_SG_REL_ ATS SG_ 2015 GST_ALL_Byte2 0;
BA_REL_ "GenSigTimeoutTime" BU_SG_REL_ DSAU SG_ 2015 GST_ALL_Byte2 0;
BA_REL_ "GenSigTimeoutTime" BU_SG_REL_ ASAU SG_ 2015 GST_ALL_Byte2 0;
BA_REL_ "GenSigTimeoutTime" BU_SG_REL_ RCM SG_ 2015 GST_ALL_Byte2 0;
BA_REL_ "GenSigTimeoutTime" BU_SG_REL_ EMCU SG_ 2015 GST_ALL_Byte2 0;
BA_REL_ "GenSigTimeoutTime" BU_SG_REL_ SGU SG_ 2015 GST_ALL_Byte2 0;
BA_REL_ "GenSigTimeoutTime" BU_SG_REL_ ALBCU SG_ 2015 GST_ALL_Byte2 0;
BA_REL_ "GenSigTimeoutTime" BU_SG_REL_ WPC2 SG_ 2015 GST_ALL_Byte2 0;
BA_REL_ "GenSigTimeoutTime" BU_SG_REL_ FCS SG_ 2015 GST_ALL_Byte3 0;
BA_REL_ "GenSigTimeoutTime" BU_SG_REL_ SCM SG_ 2015 GST_ALL_Byte3 0;
BA_REL_ "GenSigTimeoutTime" BU_SG_REL_ WPC SG_ 2015 GST_ALL_Byte3 0;
BA_REL_ "GenSigTimeoutTime" BU_SG_REL_ RWPC SG_ 2015 GST_ALL_Byte3 0;
BA_REL_ "GenSigTimeoutTime" BU_SG_REL_ PSB SG_ 2015 GST_ALL_Byte3 0;
BA_REL_ "GenSigTimeoutTime" BU_SG_REL_ SLB SG_ 2015 GST_ALL_Byte3 0;
BA_REL_ "GenSigTimeoutTime" BU_SG_REL_ ARS SG_ 2015 GST_ALL_Byte3 0;
BA_REL_ "GenSigTimeoutTime" BU_SG_REL_ SWRC SG_ 2015 GST_ALL_Byte3 0;
BA_REL_ "GenSigTimeoutTime" BU_SG_REL_ APSU SG_ 2015 GST_ALL_Byte3 0;
BA_REL_ "GenSigTimeoutTime" BU_SG_REL_ RLHV SG_ 2015 GST_ALL_Byte3 0;
BA_REL_ "GenSigTimeoutTime" BU_SG_REL_ RRHV SG_ 2015 GST_ALL_Byte3 0;
BA_REL_ "GenSigTimeoutTime" BU_SG_REL_ SHVU_FR SG_ 2015 GST_ALL_Byte3 0;
BA_REL_ "GenSigTimeoutTime" BU_SG_REL_ SHVU_RR SG_ 2015 GST_ALL_Byte3 0;
BA_REL_ "GenSigTimeoutTime" BU_SG_REL_ DPSU SG_ 2015 GST_ALL_Byte3 0;
BA_REL_ "GenSigTimeoutTime" BU_SG_REL_ DLBCU SG_ 2015 GST_ALL_Byte3 0;
BA_REL_ "GenSigTimeoutTime" BU_SG_REL_ PFSU SG_ 2015 GST_ALL_Byte3 0;
BA_REL_ "GenSigTimeoutTime" BU_SG_REL_ RCS SG_ 2015 GST_ALL_Byte3 0;
BA_REL_ "GenSigTimeoutTime" BU_SG_REL_ RRPSU SG_ 2015 GST_ALL_Byte3 0;
BA_REL_ "GenSigTimeoutTime" BU_SG_REL_ RLPSU SG_ 2015 GST_ALL_Byte3 0;
BA_REL_ "GenSigTimeoutTime" BU_SG_REL_ HOD SG_ 2015 GST_ALL_Byte3 0;
BA_REL_ "GenSigTimeoutTime" BU_SG_REL_ ATS SG_ 2015 GST_ALL_Byte3 0;
BA_REL_ "GenSigTimeoutTime" BU_SG_REL_ DSAU SG_ 2015 GST_ALL_Byte3 0;
BA_REL_ "GenSigTimeoutTime" BU_SG_REL_ ASAU SG_ 2015 GST_ALL_Byte3 0;
BA_REL_ "GenSigTimeoutTime" BU_SG_REL_ RCM SG_ 2015 GST_ALL_Byte3 0;
BA_REL_ "GenSigTimeoutTime" BU_SG_REL_ EMCU SG_ 2015 GST_ALL_Byte3 0;
BA_REL_ "GenSigTimeoutTime" BU_SG_REL_ SGU SG_ 2015 GST_ALL_Byte3 0;
BA_REL_ "GenSigTimeoutTime" BU_SG_REL_ ALBCU SG_ 2015 GST_ALL_Byte3 0;
BA_REL_ "GenSigTimeoutTime" BU_SG_REL_ WPC2 SG_ 2015 GST_ALL_Byte3 0;
BA_REL_ "GenSigTimeoutTime" BU_SG_REL_ FCS SG_ 2015 GST_ALL_Byte4 0;
BA_REL_ "GenSigTimeoutTime" BU_SG_REL_ SCM SG_ 2015 GST_ALL_Byte4 0;
BA_REL_ "GenSigTimeoutTime" BU_SG_REL_ WPC SG_ 2015 GST_ALL_Byte4 0;
BA_REL_ "GenSigTimeoutTime" BU_SG_REL_ RWPC SG_ 2015 GST_ALL_Byte4 0;
BA_REL_ "GenSigTimeoutTime" BU_SG_REL_ PSB SG_ 2015 GST_ALL_Byte4 0;
BA_REL_ "GenSigTimeoutTime" BU_SG_REL_ SLB SG_ 2015 GST_ALL_Byte4 0;
BA_REL_ "GenSigTimeoutTime" BU_SG_REL_ ARS SG_ 2015 GST_ALL_Byte4 0;
BA_REL_ "GenSigTimeoutTime" BU_SG_REL_ SWRC SG_ 2015 GST_ALL_Byte4 0;
BA_REL_ "GenSigTimeoutTime" BU_SG_REL_ APSU SG_ 2015 GST_ALL_Byte4 0;
BA_REL_ "GenSigTimeoutTime" BU_SG_REL_ RLHV SG_ 2015 GST_ALL_Byte4 0;
BA_REL_ "GenSigTimeoutTime" BU_SG_REL_ RRHV SG_ 2015 GST_ALL_Byte4 0;
BA_REL_ "GenSigTimeoutTime" BU_SG_REL_ SHVU_FR SG_ 2015 GST_ALL_Byte4 0;
BA_REL_ "GenSigTimeoutTime" BU_SG_REL_ SHVU_RR SG_ 2015 GST_ALL_Byte4 0;
BA_REL_ "GenSigTimeoutTime" BU_SG_REL_ DPSU SG_ 2015 GST_ALL_Byte4 0;
BA_REL_ "GenSigTimeoutTime" BU_SG_REL_ DLBCU SG_ 2015 GST_ALL_Byte4 0;
BA_REL_ "GenSigTimeoutTime" BU_SG_REL_ PFSU SG_ 2015 GST_ALL_Byte4 0;
BA_REL_ "GenSigTimeoutTime" BU_SG_REL_ RCS SG_ 2015 GST_ALL_Byte4 0;
BA_REL_ "GenSigTimeoutTime" BU_SG_REL_ RRPSU SG_ 2015 GST_ALL_Byte4 0;
BA_REL_ "GenSigTimeoutTime" BU_SG_REL_ RLPSU SG_ 2015 GST_ALL_Byte4 0;
BA_REL_ "GenSigTimeoutTime" BU_SG_REL_ HOD SG_ 2015 GST_ALL_Byte4 0;
BA_REL_ "GenSigTimeoutTime" BU_SG_REL_ ATS SG_ 2015 GST_ALL_Byte4 0;
BA_REL_ "GenSigTimeoutTime" BU_SG_REL_ DSAU SG_ 2015 GST_ALL_Byte4 0;
BA_REL_ "GenSigTimeoutTime" BU_SG_REL_ ASAU SG_ 2015 GST_ALL_Byte4 0;
BA_REL_ "GenSigTimeoutTime" BU_SG_REL_ RCM SG_ 2015 GST_ALL_Byte4 0;
BA_REL_ "GenSigTimeoutTime" BU_SG_REL_ EMCU SG_ 2015 GST_ALL_Byte4 0;
BA_REL_ "GenSigTimeoutTime" BU_SG_REL_ SGU SG_ 2015 GST_ALL_Byte4 0;
BA_REL_ "GenSigTimeoutTime" BU_SG_REL_ ALBCU SG_ 2015 GST_ALL_Byte4 0;
BA_REL_ "GenSigTimeoutTime" BU_SG_REL_ WPC2 SG_ 2015 GST_ALL_Byte4 0;
BA_REL_ "GenSigTimeoutTime" BU_SG_REL_ FCS SG_ 2015 GST_ALL_Byte5 0;
BA_REL_ "GenSigTimeoutTime" BU_SG_REL_ SCM SG_ 2015 GST_ALL_Byte5 0;
BA_REL_ "GenSigTimeoutTime" BU_SG_REL_ WPC SG_ 2015 GST_ALL_Byte5 0;
BA_REL_ "GenSigTimeoutTime" BU_SG_REL_ RWPC SG_ 2015 GST_ALL_Byte5 0;
BA_REL_ "GenSigTimeoutTime" BU_SG_REL_ PSB SG_ 2015 GST_ALL_Byte5 0;
BA_REL_ "GenSigTimeoutTime" BU_SG_REL_ SLB SG_ 2015 GST_ALL_Byte5 0;
BA_REL_ "GenSigTimeoutTime" BU_SG_REL_ ARS SG_ 2015 GST_ALL_Byte5 0;
BA_REL_ "GenSigTimeoutTime" BU_SG_REL_ SWRC SG_ 2015 GST_ALL_Byte5 0;
BA_REL_ "GenSigTimeoutTime" BU_SG_REL_ APSU SG_ 2015 GST_ALL_Byte5 0;
BA_REL_ "GenSigTimeoutTime" BU_SG_REL_ RLHV SG_ 2015 GST_ALL_Byte5 0;
BA_REL_ "GenSigTimeoutTime" BU_SG_REL_ RRHV SG_ 2015 GST_ALL_Byte5 0;
BA_REL_ "GenSigTimeoutTime" BU_SG_REL_ SHVU_FR SG_ 2015 GST_ALL_Byte5 0;
BA_REL_ "GenSigTimeoutTime" BU_SG_REL_ SHVU_RR SG_ 2015 GST_ALL_Byte5 0;
BA_REL_ "GenSigTimeoutTime" BU_SG_REL_ DPSU SG_ 2015 GST_ALL_Byte5 0;
BA_REL_ "GenSigTimeoutTime" BU_SG_REL_ DLBCU SG_ 2015 GST_ALL_Byte5 0;
BA_REL_ "GenSigTimeoutTime" BU_SG_REL_ PFSU SG_ 2015 GST_ALL_Byte5 0;
BA_REL_ "GenSigTimeoutTime" BU_SG_REL_ RCS SG_ 2015 GST_ALL_Byte5 0;
BA_REL_ "GenSigTimeoutTime" BU_SG_REL_ RRPSU SG_ 2015 GST_ALL_Byte5 0;
BA_REL_ "GenSigTimeoutTime" BU_SG_REL_ RLPSU SG_ 2015 GST_ALL_Byte5 0;
BA_REL_ "GenSigTimeoutTime" BU_SG_REL_ HOD SG_ 2015 GST_ALL_Byte5 0;
BA_REL_ "GenSigTimeoutTime" BU_SG_REL_ ATS SG_ 2015 GST_ALL_Byte5 0;
BA_REL_ "GenSigTimeoutTime" BU_SG_REL_ DSAU SG_ 2015 GST_ALL_Byte5 0;
BA_REL_ "GenSigTimeoutTime" BU_SG_REL_ ASAU SG_ 2015 GST_ALL_Byte5 0;
BA_REL_ "GenSigTimeoutTime" BU_SG_REL_ RCM SG_ 2015 GST_ALL_Byte5 0;
BA_REL_ "GenSigTimeoutTime" BU_SG_REL_ EMCU SG_ 2015 GST_ALL_Byte5 0;
BA_REL_ "GenSigTimeoutTime" BU_SG_REL_ SGU SG_ 2015 GST_ALL_Byte5 0;
BA_REL_ "GenSigTimeoutTime" BU_SG_REL_ ALBCU SG_ 2015 GST_ALL_Byte5 0;
BA_REL_ "GenSigTimeoutTime" BU_SG_REL_ WPC2 SG_ 2015 GST_ALL_Byte5 0;
BA_REL_ "GenSigTimeoutTime" BU_SG_REL_ FCS SG_ 2015 GST_ALL_Byte6 0;
BA_REL_ "GenSigTimeoutTime" BU_SG_REL_ SCM SG_ 2015 GST_ALL_Byte6 0;
BA_REL_ "GenSigTimeoutTime" BU_SG_REL_ WPC SG_ 2015 GST_ALL_Byte6 0;
BA_REL_ "GenSigTimeoutTime" BU_SG_REL_ RWPC SG_ 2015 GST_ALL_Byte6 0;
BA_REL_ "GenSigTimeoutTime" BU_SG_REL_ PSB SG_ 2015 GST_ALL_Byte6 0;
BA_REL_ "GenSigTimeoutTime" BU_SG_REL_ SLB SG_ 2015 GST_ALL_Byte6 0;
BA_REL_ "GenSigTimeoutTime" BU_SG_REL_ ARS SG_ 2015 GST_ALL_Byte6 0;
BA_REL_ "GenSigTimeoutTime" BU_SG_REL_ SWRC SG_ 2015 GST_ALL_Byte6 0;
BA_REL_ "GenSigTimeoutTime" BU_SG_REL_ APSU SG_ 2015 GST_ALL_Byte6 0;
BA_REL_ "GenSigTimeoutTime" BU_SG_REL_ RLHV SG_ 2015 GST_ALL_Byte6 0;
BA_REL_ "GenSigTimeoutTime" BU_SG_REL_ RRHV SG_ 2015 GST_ALL_Byte6 0;
BA_REL_ "GenSigTimeoutTime" BU_SG_REL_ SHVU_FR SG_ 2015 GST_ALL_Byte6 0;
BA_REL_ "GenSigTimeoutTime" BU_SG_REL_ SHVU_RR SG_ 2015 GST_ALL_Byte6 0;
BA_REL_ "GenSigTimeoutTime" BU_SG_REL_ DPSU SG_ 2015 GST_ALL_Byte6 0;
BA_REL_ "GenSigTimeoutTime" BU_SG_REL_ DLBCU SG_ 2015 GST_ALL_Byte6 0;
BA_REL_ "GenSigTimeoutTime" BU_SG_REL_ PFSU SG_ 2015 GST_ALL_Byte6 0;
BA_REL_ "GenSigTimeoutTime" BU_SG_REL_ RCS SG_ 2015 GST_ALL_Byte6 0;
BA_REL_ "GenSigTimeoutTime" BU_SG_REL_ RRPSU SG_ 2015 GST_ALL_Byte6 0;
BA_REL_ "GenSigTimeoutTime" BU_SG_REL_ RLPSU SG_ 2015 GST_ALL_Byte6 0;
BA_REL_ "GenSigTimeoutTime" BU_SG_REL_ HOD SG_ 2015 GST_ALL_Byte6 0;
BA_REL_ "GenSigTimeoutTime" BU_SG_REL_ ATS SG_ 2015 GST_ALL_Byte6 0;
BA_REL_ "GenSigTimeoutTime" BU_SG_REL_ DSAU SG_ 2015 GST_ALL_Byte6 0;
BA_REL_ "GenSigTimeoutTime" BU_SG_REL_ ASAU SG_ 2015 GST_ALL_Byte6 0;
BA_REL_ "GenSigTimeoutTime" BU_SG_REL_ RCM SG_ 2015 GST_ALL_Byte6 0;
BA_REL_ "GenSigTimeoutTime" BU_SG_REL_ EMCU SG_ 2015 GST_ALL_Byte6 0;
BA_REL_ "GenSigTimeoutTime" BU_SG_REL_ SGU SG_ 2015 GST_ALL_Byte6 0;
BA_REL_ "GenSigTimeoutTime" BU_SG_REL_ ALBCU SG_ 2015 GST_ALL_Byte6 0;
BA_REL_ "GenSigTimeoutTime" BU_SG_REL_ WPC2 SG_ 2015 GST_ALL_Byte6 0;
BA_REL_ "GenSigTimeoutTime" BU_SG_REL_ FCS SG_ 2015 GST_ALL_Byte7 0;
BA_REL_ "GenSigTimeoutTime" BU_SG_REL_ SCM SG_ 2015 GST_ALL_Byte7 0;
BA_REL_ "GenSigTimeoutTime" BU_SG_REL_ WPC SG_ 2015 GST_ALL_Byte7 0;
BA_REL_ "GenSigTimeoutTime" BU_SG_REL_ RWPC SG_ 2015 GST_ALL_Byte7 0;
BA_REL_ "GenSigTimeoutTime" BU_SG_REL_ PSB SG_ 2015 GST_ALL_Byte7 0;
BA_REL_ "GenSigTimeoutTime" BU_SG_REL_ SLB SG_ 2015 GST_ALL_Byte7 0;
BA_REL_ "GenSigTimeoutTime" BU_SG_REL_ ARS SG_ 2015 GST_ALL_Byte7 0;
BA_REL_ "GenSigTimeoutTime" BU_SG_REL_ SWRC SG_ 2015 GST_ALL_Byte7 0;
BA_REL_ "GenSigTimeoutTime" BU_SG_REL_ APSU SG_ 2015 GST_ALL_Byte7 0;
BA_REL_ "GenSigTimeoutTime" BU_SG_REL_ RLHV SG_ 2015 GST_ALL_Byte7 0;
BA_REL_ "GenSigTimeoutTime" BU_SG_REL_ RRHV SG_ 2015 GST_ALL_Byte7 0;
BA_REL_ "GenSigTimeoutTime" BU_SG_REL_ SHVU_FR SG_ 2015 GST_ALL_Byte7 0;
BA_REL_ "GenSigTimeoutTime" BU_SG_REL_ SHVU_RR SG_ 2015 GST_ALL_Byte7 0;
BA_REL_ "GenSigTimeoutTime" BU_SG_REL_ DPSU SG_ 2015 GST_ALL_Byte7 0;
BA_REL_ "GenSigTimeoutTime" BU_SG_REL_ DLBCU SG_ 2015 GST_ALL_Byte7 0;
BA_REL_ "GenSigTimeoutTime" BU_SG_REL_ PFSU SG_ 2015 GST_ALL_Byte7 0;
BA_REL_ "GenSigTimeoutTime" BU_SG_REL_ RCS SG_ 2015 GST_ALL_Byte7 0;
BA_REL_ "GenSigTimeoutTime" BU_SG_REL_ RRPSU SG_ 2015 GST_ALL_Byte7 0;
BA_REL_ "GenSigTimeoutTime" BU_SG_REL_ RLPSU SG_ 2015 GST_ALL_Byte7 0;
BA_REL_ "GenSigTimeoutTime" BU_SG_REL_ HOD SG_ 2015 GST_ALL_Byte7 0;
BA_REL_ "GenSigTimeoutTime" BU_SG_REL_ ATS SG_ 2015 GST_ALL_Byte7 0;
BA_REL_ "GenSigTimeoutTime" BU_SG_REL_ DSAU SG_ 2015 GST_ALL_Byte7 0;
BA_REL_ "GenSigTimeoutTime" BU_SG_REL_ ASAU SG_ 2015 GST_ALL_Byte7 0;
BA_REL_ "GenSigTimeoutTime" BU_SG_REL_ RCM SG_ 2015 GST_ALL_Byte7 0;
BA_REL_ "GenSigTimeoutTime" BU_SG_REL_ EMCU SG_ 2015 GST_ALL_Byte7 0;
BA_REL_ "GenSigTimeoutTime" BU_SG_REL_ SGU SG_ 2015 GST_ALL_Byte7 0;
BA_REL_ "GenSigTimeoutTime" BU_SG_REL_ ALBCU SG_ 2015 GST_ALL_Byte7 0;
BA_REL_ "GenSigTimeoutTime" BU_SG_REL_ WPC2 SG_ 2015 GST_ALL_Byte7 0;
BA_REL_ "GenSigTimeoutTime" BU_SG_REL_ FCS SG_ 2015 GST_ALL_Byte1 0;
BA_REL_ "GenSigTimeoutTime" BU_SG_REL_ SCM SG_ 2015 GST_ALL_Byte1 0;
BA_REL_ "GenSigTimeoutTime" BU_SG_REL_ WPC SG_ 2015 GST_ALL_Byte1 0;
BA_REL_ "GenSigTimeoutTime" BU_SG_REL_ RWPC SG_ 2015 GST_ALL_Byte1 0;
BA_REL_ "GenSigTimeoutTime" BU_SG_REL_ PSB SG_ 2015 GST_ALL_Byte1 0;
BA_REL_ "GenSigTimeoutTime" BU_SG_REL_ SLB SG_ 2015 GST_ALL_Byte1 0;
BA_REL_ "GenSigTimeoutTime" BU_SG_REL_ ARS SG_ 2015 GST_ALL_Byte1 0;
BA_REL_ "GenSigTimeoutTime" BU_SG_REL_ SWRC SG_ 2015 GST_ALL_Byte1 0;
BA_REL_ "GenSigTimeoutTime" BU_SG_REL_ APSU SG_ 2015 GST_ALL_Byte1 0;
BA_REL_ "GenSigTimeoutTime" BU_SG_REL_ RLHV SG_ 2015 GST_ALL_Byte1 0;
BA_REL_ "GenSigTimeoutTime" BU_SG_REL_ RRHV SG_ 2015 GST_ALL_Byte1 0;
BA_REL_ "GenSigTimeoutTime" BU_SG_REL_ SHVU_FR SG_ 2015 GST_ALL_Byte1 0;
BA_REL_ "GenSigTimeoutTime" BU_SG_REL_ SHVU_RR SG_ 2015 GST_ALL_Byte1 0;
BA_REL_ "GenSigTimeoutTime" BU_SG_REL_ DPSU SG_ 2015 GST_ALL_Byte1 0;
BA_REL_ "GenSigTimeoutTime" BU_SG_REL_ DLBCU SG_ 2015 GST_ALL_Byte1 0;
BA_REL_ "GenSigTimeoutTime" BU_SG_REL_ PFSU SG_ 2015 GST_ALL_Byte1 0;
BA_REL_ "GenSigTimeoutTime" BU_SG_REL_ RCS SG_ 2015 GST_ALL_Byte1 0;
BA_REL_ "GenSigTimeoutTime" BU_SG_REL_ RRPSU SG_ 2015 GST_ALL_Byte1 0;
BA_REL_ "GenSigTimeoutTime" BU_SG_REL_ RLPSU SG_ 2015 GST_ALL_Byte1 0;
BA_REL_ "GenSigTimeoutTime" BU_SG_REL_ HOD SG_ 2015 GST_ALL_Byte1 0;
BA_REL_ "GenSigTimeoutTime" BU_SG_REL_ ATS SG_ 2015 GST_ALL_Byte1 0;
BA_REL_ "GenSigTimeoutTime" BU_SG_REL_ DSAU SG_ 2015 GST_ALL_Byte1 0;
BA_REL_ "GenSigTimeoutTime" BU_SG_REL_ ASAU SG_ 2015 GST_ALL_Byte1 0;
BA_REL_ "GenSigTimeoutTime" BU_SG_REL_ RCM SG_ 2015 GST_ALL_Byte1 0;
BA_REL_ "GenSigTimeoutTime" BU_SG_REL_ EMCU SG_ 2015 GST_ALL_Byte1 0;
BA_REL_ "GenSigTimeoutTime" BU_SG_REL_ SGU SG_ 2015 GST_ALL_Byte1 0;
BA_REL_ "GenSigTimeoutTime" BU_SG_REL_ ALBCU SG_ 2015 GST_ALL_Byte1 0;
BA_REL_ "GenSigTimeoutTime" BU_SG_REL_ WPC2 SG_ 2015 GST_ALL_Byte1 0;
BA_REL_ "GenSigTimeoutTime" BU_SG_REL_ SCM SG_ 915 TiltTele_CurProfileState 1500;
BA_REL_ "GenSigTimeoutTime" BU_SG_REL_ DPSU SG_ 915 TiltTele_USMEsyAcsSetState 1500;
BA_REL_ "GenSigTimeoutTime" BU_SG_REL_ SCM SG_ 915 TiltTele_PreEsyAcsProfile 1500;
BA_REL_ "GenSigTimeoutTime" BU_SG_REL_ SCM SG_ 915 Tilt_MnlInitCmd 1500;
BA_REL_ "GenSigTimeoutTime" BU_SG_REL_ SCM SG_ 915 Tilt_MnlOpCmd 1500;
BA_REL_ "GenSigTimeoutTime" BU_SG_REL_ SCM SG_ 915 Tele_MnlInitCmd 1500;
BA_REL_ "GenSigTimeoutTime" BU_SG_REL_ SCM SG_ 915 Tilt_AutoOpCmd 1500;
BA_REL_ "GenSigTimeoutTime" BU_SG_REL_ DPSU SG_ 915 TiltTele_PlyBckState 1500;
BA_REL_ "GenSigTimeoutTime" BU_SG_REL_ SCM SG_ 915 Tele_MnlOpCmd 1500;
BA_REL_ "GenSigTimeoutTime" BU_SG_REL_ SCM SG_ 915 Tele_AutoOpCmd 1500;
BA_REL_ "GenSigTimeoutTime" BU_SG_REL_ BLTN_CAM SG_ 912 HU_BLTN_CAM_UI_Mode 1500;
BA_REL_ "GenSigTimeoutTime" BU_SG_REL_ BLTN_CAM SG_ 912 HU_BLTN_CAM_Display 1500;
VAL_ 952 BLTN_CAM_Set_FR_Ver_Pos 0 "Mid" 1 "Upper Level (1 ~ 10)" 2 "Upper Level (1 ~ 10)" 3 "Upper Level (1 ~ 10)" 4 "Upper Level (1 ~ 10)" 5 "Upper Level (1 ~ 10)" 6 "Upper Level (1 ~ 10)" 7 "Upper Level (1 ~ 10)" 8 "Upper Level (1 ~ 10)" 9 "Upper Level (1 ~ 10)" 10 "Upper Level (1 ~ 10)" 11 "Reserved" 12 "Reserved" 13 "Reserved" 14 "Reserved" 15 "Reserved" 16 "Reserved" 17 "Lower Level (-1 ~ -10)" 18 "Lower Level (-1 ~ -10)" 19 "Lower Level (-1 ~ -10)" 20 "Lower Level (-1 ~ -10)" 21 "Lower Level (-1 ~ -10)" 22 "Lower Level (-1 ~ -10)" 23 "Lower Level (-1 ~ -10)" 24 "Lower Level (-1 ~ -10)" 25 "Lower Level (-1 ~ -10)" 26 "Lower Level (-1 ~ -10)" 27 "Reserved" 28 "Reserved" 29 "Reserved" 30 "Reserved" 31 "Invalid" ;
VAL_ 952 BLTN_CAM_Set_PEV_AppNoti 0 "Default" 1 "Off" 2 "On" 3 "Invalid" ;
VAL_ 952 BLTN_CAM_Set_WiFi_AutoOn 0 "Default" 1 "Off" 2 "On" 3 "Invalid" ;
VAL_ 952 BLTN_CAM_StrgPropSet 0 "Normal" 1 "On While Recordings" 2 "On While Parked" 3 "Driving Events" 4 "Parked Events" 5 "Reserved" 6 "Reserved" 7 "Reserved" 8 "Reserved" 9 "Reserved" 10 "Reserved" 11 "Reserved" 12 "Reserved" 13 "Reserved" 14 "Reserved" 15 "Invalid" ;
VAL_ 952 BLTN_CAM_File_DEL_CPY_Op_State 0 "Default" 1 "On Deleting" 2 "On Copying" 3 "operation completed" 4 "pausing the operation" 5 "operation canceled" 6 "Reserved" 7 "Reserved" 8 "Reserved" 9 "Reserved" 10 "Delete Error, No file(s)" 11 "Copy Error, No file(s)" 12 "Copy Error, Not enough target stroage space." 13 "The space not existed(not mounted)" 14 "the commend file is wrong." 15 "Invalid" ;
VAL_ 952 BLTN_CAM_File_DEL_CPY_NumTot 0 "Default" 1 "0x001~0xFFFB:Number of files" 65531 "0x001~0xFFFB:Number of files" 65532 "not operated" 65533 "The space not existed(not mounted)" 65534 "Not enough space" 65535 "Invalid" ;
VAL_ 952 BLTN_CAM_File_DEL_CPYed_Num 0 "Default" 1 "0x001~0xFFFB:Number of files" 65531 "0x001~0xFFFB:Number of files" 65532 "not operated" 65533 "The space not existed(not mounted)" 65534 "Not enough space" 65535 "Invalid" ;
VAL_ 952 BLTN_CAM_Set_RR_Ver_Pos 0 "Mid" 1 "Upper Level (1 ~ 10)" 2 "Upper Level (1 ~ 10)" 3 "Upper Level (1 ~ 10)" 4 "Upper Level (1 ~ 10)" 5 "Upper Level (1 ~ 10)" 6 "Upper Level (1 ~ 10)" 7 "Upper Level (1 ~ 10)" 8 "Upper Level (1 ~ 10)" 9 "Upper Level (1 ~ 10)" 10 "Upper Level (1 ~ 10)" 11 "Reserved" 12 "Reserved" 13 "Reserved" 14 "Reserved" 15 "Reserved" 16 "Reserved" 17 "Lower Level (-1 ~ -10)" 18 "Lower Level (-1 ~ -10)" 19 "Lower Level (-1 ~ -10)" 20 "Lower Level (-1 ~ -10)" 21 "Lower Level (-1 ~ -10)" 22 "Lower Level (-1 ~ -10)" 23 "Lower Level (-1 ~ -10)" 24 "Lower Level (-1 ~ -10)" 25 "Lower Level (-1 ~ -10)" 26 "Lower Level (-1 ~ -10)" 27 "Reserved" 28 "Reserved" 29 "Reserved" 30 "Reserved" 31 "Invalid" ;
VAL_ 950 BLTN_CAM_State 0 "BLTN_CAM Valid" 1 "BLTN_CAM Front Camera Invalid" 2 "BLTN_CAM Rear Camera Invalid" 3 "BLTN_CAM Front/Rear Camera Inavlid" 4 "BLTN_CAM Record Invalid" 5 "Reserved" 6 "Reserved" 7 "Reserved" 8 "Reserved" 9 "Reserved" 10 "Reserved" 11 "Reserved" 12 "Reserved" 13 "Reserved" 14 "Reserved" 15 "Invalid" ;
VAL_ 950 BLTN_CAM_RecSta_DEV 0 "Off" 1 "Recording" 2 "Reserved" 3 "invalid" ;
VAL_ 950 BLTN_CAM_RecSta_MAR 0 "Off" 1 "Recording" 2 "Reserved" 3 "invalid" ;
VAL_ 950 BLTN_CAM_RecSta_TML 0 "Off" 1 "Recording" 2 "Reserved" 3 "invalid" ;
VAL_ 950 BLTN_CAM_RecSta_OWP 0 "Off" 1 "Recording" 2 "Reserved" 3 "invalid" ;
VAL_ 950 BLTN_CAM_RecSta_PEV 0 "Off" 1 "Recording" 2 "Reserved" 3 "invalid" ;
VAL_ 950 BLTN_CAM_Prk_EV_Cnt 0 "0x0x0~0xC8:the number of the Park Event Record(0~200)" 200 "0x0x0~0xC8:the number of the Park Event Record(0~200)" 201 "Reserved" 202 "Reserved" 203 "Reserved" 204 "Reserved" 205 "Reserved" 206 "Reserved" 207 "Reserved" 208 "Reserved" 209 "Reserved" 210 "Reserved" 211 "Reserved" 212 "Reserved" 213 "Reserved" 214 "Reserved" 215 "Reserved" 216 "Reserved" 217 "Reserved" 218 "Reserved" 219 "Reserved" 220 "Reserved" 221 "Reserved" 222 "Reserved" 223 "Reserved" 224 "Reserved" 225 "Reserved" 226 "Reserved" 227 "Reserved" 228 "Reserved" 229 "Reserved" 230 "Reserved" 231 "Reserved" 232 "Reserved" 233 "Reserved" 234 "Reserved" 235 "Reserved" 236 "Reserved" 237 "Reserved" 238 "Reserved" 239 "Reserved" 240 "Reserved" 241 "Reserved" 242 "Reserved" 243 "Reserved" 244 "Reserved" 245 "Reserved" 246 "Reserved" 247 "Reserved" 248 "Reserved" 249 "Reserved" 250 "Reserved" 251 "Reserved" 252 "Over than 200 count" 253 "Park Mode was not Excuted" 254 "Park Mode was not Supported" 255 "invalid" ;
VAL_ 950 BLTN_CAM_Prk_Oped_Time 0 "Park Mode was not Excuted" 1 "0x1~0xFB:the hours of Park Mode Operated" 251 "0x1~0xFB:the hours of Park Mode Operated" 252 "RESERVED" 253 "RESERVED" 254 "RESERVED" 255 "invalid" ;
VAL_ 950 BLTN_CAM_Prk_Oprable_Time 0 "0x0x0~0xFB:the hours of Park Mode Operatable" 251 "0x0x0~0xFB:the hours of Park Mode Operatable" 252 "RESERVED" 253 "Auxiliary Battery is not connected. - Auxiliary Battery applicable on this vehicle model" 254 "Auxiliary Battery is not connected. ? Auxiliary Battery not applicable on this vehicle model" 255 "Invalid" ;
VAL_ 950 BLTN_CAM_SD_Card_State 0 "Good, SD card is OK.(Green State)" 1 "SD card replacement recommend.(Yallow State)" 2 "SD card replacement required.(Red State)" 3 "SD card unrecognizable or No SD card found." 4 "SD card total capacity spec less than 64GByte (Built-in Cam Support 64GByte or higher)" 5 "SD card file system is not for Built-in Cam(Built-in CAM only support exFAT filesystem)" 6 "SD card not enough free space, need more free space for built-in Cam(less than 32GByte, must be 32GB" 7 "SD card recognized but Health State is not available (Gray State)" 8 "SD card Unmounted" 9 "RESERVED" 10 "RESERVED" 11 "RESERVED" 12 "RESERVED" 13 "RESERVED" 14 "RESERVED" 15 "Invalid(Red State)" ;
VAL_ 950 BLTN_CAM_Prk_Oprable_Time_Max 0 "0x0x0~0xFB:the hours of Park Mode Operatable" 251 "0x0x0~0xFB:the hours of Park Mode Operatable" 252 "RESERVED" 253 "Auxiliary Battery is not connected. - Auxiliary Battery applicable on this vehicle model" 254 "Auxiliary Battery is not connected. ? Auxiliary Battery not applicable on this vehicle model" 255 "Invalid" ;
VAL_ 950 BLTN_CAM_AuxBat_Conn_State 0 "Default" 1 "Auxiliary Battery is connected.(P-LBM or B-LBM)" 2 "Auxiliary Battery is not connected. - Auxiliary Battery applicable on this vehicle model" 3 "Auxiliary Battery is not connected. ? Auxiliary Battery not applicable on this vehicle model" ;
VAL_ 950 BLTN_CAM_AuxBat_CapPer 0 "0x0x0~0x64: Aux Bat Capacity Percent(0~100%)" 100 "0x0x0~0x64: Aux Bat Capacity Percent(0~100%)" 100 "Reserved" 101 "Reserved" 102 "Reserved" 103 "Reserved" 104 "Reserved" 105 "Reserved" 106 "Reserved" 107 "Reserved" 108 "Reserved" 109 "Reserved" 110 "Reserved" 111 "Reserved" 112 "Reserved" 113 "Reserved" 114 "Reserved" 115 "Reserved" 116 "Reserved" 117 "Reserved" 118 "Reserved" 119 "Reserved" 120 "Reserved" 121 "Reserved" 122 "Reserved" 123 "Reserved" 124 "Reserved" 125 "Reserved" 126 "Reserved" 127 "Invalid" ;
VAL_ 950 BLTN_CAM_RecSta_OWD 0 "Off" 1 "Recording" 2 "Reserved" 3 "invalid" ;
VAL_ 951 BLTN_CAM_RecSet_OWD 0 "Default" 1 "Off" 2 "On" 3 "Invalid" ;
VAL_ 951 BLTN_CAM_Set_Tim_Stm 0 "Default" 1 "Off" 2 "On" 3 "Invalid" ;
VAL_ 951 BLTN_CAM_Set_Spd_Stm 0 "Default" 1 "Off" 2 "On" 3 "Invalid" ;
VAL_ 951 BLTN_CAM_Set_Locatn_Stm 0 "Default" 1 "Off" 2 "On" 3 "Invalid" ;
VAL_ 951 BLTN_CAM_Set_TrnSig_Stm 0 "Default" 1 "Off" 2 "On" 3 "Invalid" ;
VAL_ 951 BLTN_CAM_Set_AclBrk_Stm 0 "Default" 1 "Off" 2 "On" 3 "Invalid" ;
VAL_ 951 BLTN_CAM_RecSet_DEV 0 "Default" 1 "Off" 2 "On" 3 "Invalid" ;
VAL_ 951 BLTN_CAM_Set_GearPos_Stm 0 "Default" 1 "Off" 2 "On" 3 "Invalid" ;
VAL_ 951 BLTN_CAM_Set_EVSen_Stm 0 "Default" 1 "Off" 2 "On" 3 "Invalid" ;
VAL_ 951 BLTN_CAM_Set_StrAngl_Stm 0 "Default" 1 "Off" 2 "On" 3 "Invalid" ;
VAL_ 951 BLTN_CAM_Set_PrkTime 0 "Default" 1 "0x01~0xFB: 1~ 251 hr" 251 "0x01~0xFB: 1~ 251 hr" 252 "RESERVED" 253 "RESERVED" 254 "Not Supported" 255 "Invalid" ;
VAL_ 951 BLTN_CAM_Set_EV_BfrTime 0 "10~20 sec" 1 "10~20 sec" 2 "10~20 sec" 3 "10~20 sec" 4 "10~20 sec" 5 "10~20 sec" 6 "10~20 sec" 7 "10~20 sec" 8 "10~20 sec" 9 "10~20 sec" 10 "10~20 sec" 11 "Reserved" 12 "Reserved" 13 "Reserved" 14 "Reserved" 15 "Reserved" 16 "Reserved" 17 "Reserved" 18 "Reserved" 19 "Reserved" 20 "Reserved" 21 "Reserved" 22 "Reserved" 23 "Reserved" 24 "Reserved" 25 "Reserved" 26 "Reserved" 27 "Reserved" 28 "Reserved" 29 "Reserved" 30 "Reserved" 31 "Invalid" ;
VAL_ 951 BLTN_CAM_RecSet_OWP 0 "Default" 1 "Off" 2 "On" 3 "Invalid" ;
VAL_ 951 BLTN_CAM_Set_EV_AftTime 0 "10~20 sec" 1 "10~20 sec" 2 "10~20 sec" 3 "10~20 sec" 4 "10~20 sec" 5 "10~20 sec" 6 "10~20 sec" 7 "10~20 sec" 8 "10~20 sec" 9 "10~20 sec" 10 "10~20 sec" 11 "Reserved" 12 "Reserved" 13 "Reserved" 14 "Reserved" 15 "Reserved" 16 "Reserved" 17 "Reserved" 18 "Reserved" 19 "Reserved" 20 "Reserved" 21 "Reserved" 22 "Reserved" 23 "Reserved" 24 "Reserved" 25 "Reserved" 26 "Reserved" 27 "Reserved" 28 "Reserved" 29 "Reserved" 30 "Reserved" 31 "Invalid" ;
VAL_ 951 BLTN_CAM_Set_Drv_TML_Int 0 "Default" 1 "1~ 10 sec" 2 "1~ 10 sec" 3 "1~ 10 sec" 4 "1~ 10 sec" 5 "1~ 10 sec" 6 "1~ 10 sec" 7 "1~ 10 sec" 8 "1~ 10 sec" 9 "1~ 10 sec" 10 "1~ 10 sec" 11 "Reserved" 12 "Reserved" 13 "Reserved" 14 "Reserved" 15 "Invalid" ;
VAL_ 951 BLTN_CAM_SenSet_DEV 0 "Default" 1 "Level 1" 2 "Level 2" 3 "Level 3" 4 "Level 4" 5 "Level 5" 6 "Reserved" 7 "Reserved" 8 "Reserved" 9 "Reserved" 10 "Reserved" 11 "Reserved" 12 "Reserved" 13 "Reserved" 14 "Reserved" 15 "Invalid" ;
VAL_ 951 BLTN_CAM_SenSet_PEV 0 "Default" 1 "Level 1" 2 "Level 2" 3 "Level 3" 4 "Level 4" 5 "Level 5" 6 "Reserved" 7 "Reserved" 8 "Reserved" 9 "Reserved" 10 "Reserved" 11 "Reserved" 12 "Reserved" 13 "Reserved" 14 "Reserved" 15 "Invalid" ;
VAL_ 951 BLTN_CAM_RecSet_PEV 0 "Default" 1 "Off" 2 "On" 3 "Invalid" ;
VAL_ 951 BLTN_CAM_AudRec_Set 0 "Default" 1 "Off" 2 "On" 3 "Invalid" ;
VAL_ 2281835010 ACU_ActvFltSta 0 "Fault status is active" 1 "Fault status is historic" 2 "Fault does not exist" 3 "Reserved" 4 "Reserved" 5 "Reserved" 6 "Not used" 7 "Error Indicator" ;
VAL_ 2281835010 ACU_SdArbgExtTyp 0 "Side(or Side/Curtain) Airbag doesn't exist." 1 "Side(or Side/Curtain) Airbag exists." 2 "ACU EOL Programming Mode" 3 "Reserved" 4 "Reserved" 5 "Reserved" 6 "Not used" 7 "Error Indicator" ;
VAL_ 2281835010 ACU_PassArbg_SW_Sta 0 "NOT_APPLIED" 1 "PAB_OFF" 2 "PAB_ON" 3 "Invalid" ;
VAL_ 2281835010 ACU_HDPSpprtSWVer 0 "Not Support(init)" 1 "SW Version" 2 "SW Version" 3 "SW Version" 4 "SW Version" 5 "SW Version" 6 "SW Version" 7 "SW Version" 8 "SW Version" 9 "SW Version" 10 "SW Version" 11 "SW Version" 12 "SW Version" 13 "SW Version" 14 "SW Version" 15 "SW Version" 16 "SW Version" 17 "SW Version" 18 "SW Version" 19 "SW Version" 20 "SW Version" 21 "SW Version" ;
VAL_ 2281835010 ACU_EmerModSta 0 "ACU is NOT Emergency mode" 1 "ACU is Emergency mode" ;
VAL_ 2281835010 ACU_EvtTrigSta 0 "EDR Not triggered." 1 "EDR triggered." ;
VAL_ 2281835009 ACU_Crc1Val 0 "0x0x0~0xFFFF:CRCValue" 65535 "0x0x0~0xFFFF:CRCValue" ;
VAL_ 2281835009 ACU_AlvCnt1Val 0 "0x0x0~0xFF:AlvCntValue" 255 "0x0x0~0xFF:AlvCntValue" ;
VAL_ 2281835009 ACU_SysWrngLmpDis 0 "Warning Lamp off" 1 "Warning Lamp on" 2 "Warning Lamp flash" 3 "Reserved" 4 "Reserved" 5 "Reserved" 6 "Not used" 7 "Error Indicator" ;
VAL_ 2281835009 ACU_TlltlLmpDis 0 "ON Lamp off OFF Lamp off" 1 "ON Lamp off  OFF Lamp on" 2 "ON Lamp on OFF Lamp off" 3 "ON Lamp on OFF Lamp on" 4 "Reserved" 5 "Reserved" 6 "Reserved" 7 "Error Indicator" ;
VAL_ 2281835009 ACU_OdsIDReq 0 "Request to send ODS Identifier" 1 "Acknowledgement for the Correct ODS Identifier Received" 2 "Not used" 3 "Error Indicator" ;
VAL_ 2281835009 SeatBelt_PassBcklFltSta 0 "No Fault" 1 "Fault condition exists" 2 "Not used" 3 "Error Indicator" ;
VAL_ 2281835009 SeatBelt_DrvrBcklFltSta 0 "No Fault" 1 "Fault condition exists" 2 "Not used" 3 "Error Indicator" ;
VAL_ 2281835009 SeatBelt_PassBcklSta 0 "Passenger Seat Belt Not Latched" 1 "Passenger Seat Belt Latched" 2 "Not used" 3 "Error Indicator" ;
VAL_ 2281835009 SeatBelt_DrvrBcklSta 0 "Driver Seat Belt Not Latched" 1 "Driver Seat Belt Latched" 2 "Not used" 3 "Error Indicator" ;
VAL_ 2164279809 IMU_Crc1Val 0 "0x0x0~0xFFFF:CRCValue" 65535 "0x0x0~0xFFFF:CRCValue" ;
VAL_ 2164279809 IMU_AlvCnt1Val 0 "0x0x0~0xFF:AlvCntValue" 255 "0x0x0~0xFF:AlvCntValue" ;
VAL_ 942 AMP_Beep1VolumeStep 0 "0x0x0~0xFD:Beep1 Volume" 253 "0x0x0~0xFD:Beep1 Volume" 254 "Req.amp. Beep1 settings" 255 "Invalid" ;
VAL_ 942 AMP_Analog_OutputCh_Select 65535 "Invalid" ;
VAL_ 942 AMP_Beep1_OutputCh_Select 65535 "Invaild" ;
VAL_ 942 AMP_Beep1KBDVolumeStep 0 "0x0x0~0xFE:keyboard Beep Volume" 254 "0x0x0~0xFE:keyboard Beep Volume" 255 "Invalid" ;
VAL_ 942 AMP_SPDIF_OutputCh_Select 65535 "Invaild" ;
VAL_ 939 PSB_LHFlrSta 0 "No failure" 1 "Failure, Service Required" 2 "Defect, PSB warning light off" 3 "Signal not valid" ;
VAL_ 939 PSB_LHActvSta 0 "No PSB motor activation" 1 "PSB retract cycle active" 2 "Reserved" 3 "Reserved" ;
VAL_ 939 PSB_RHFlrSta 0 "No failure" 1 "Failure, Service Required" 2 "Defect, PSB warning light off" 3 "Signal not valid" ;
VAL_ 939 PSB_RHActvSta 0 "No PSB motor activation" 1 "PSB retract cycle active" 2 "Reserved" 3 "Reserved" ;
VAL_ 939 PSB_ActForAcu 0 "Inactive" 1 "Active" 2 "Reserved" 3 "Failure" ;
VAL_ 939 PSB_HapticWarnSta 0 "No PSB activation" 1 "PSB Haptic active-1st step" 2 "PSB Haptic active-2nd step" 3 "RESERVED" 4 "RESERVED" 5 "RESERVED" 6 "RESERVED" 7 "RESERVED" 8 "RESERVED" 9 "RESERVED" 10 "RESERVED" 11 "RESERVED" 12 "RESERVED" 13 "RESERVED" 14 "HDP Request Error" 15 "Invalid" ;
VAL_ 939 PSB_RHActForPss 0 "No PSB motor activation" 1 "PSB retract cycle active" 2 "Reserved" 3 "Reserved" ;
VAL_ 939 PSB_HDPSpprtSWVer 0 "Requirement Spec Version" 1 "Requirement Spec Version" 2 "Requirement Spec Version" 3 "Requirement Spec Version" 4 "Requirement Spec Version" 5 "Requirement Spec Version" 6 "Requirement Spec Version" 7 "Requirement Spec Version" 8 "Requirement Spec Version" 9 "Requirement Spec Version" 10 "Requirement Spec Version" 11 "Requirement Spec Version" 12 "Requirement Spec Version" 13 "Requirement Spec Version" 14 "Requirement Spec Version" 15 "Requirement Spec Version" 16 "Requirement Spec Version" 17 "Requirement Spec Version" 18 "Requirement Spec Version" 19 "Requirement Spec Version" 20 "Requirement Spec Version" 21 "Requirement Spec Version" 22 "Requirement Spec Version" 23 "Requirement Spec Version" 24 "Requirement Spec Version" 25 "Requirement Spec Version" 26 "Requirement Spec Version" 27 "Requirement Spec Version" 28 "Requirement Spec Version" 29 "Requirement Spec Version" 30 "Requirement Spec Version" 31 "Invalid" ;
VAL_ 939 PSB_LHActForPss 0 "No PSB motor activation" 1 "PSB retract cycle active" 2 "Reserved" 3 "Reserved" ;
VAL_ 2239851012 RSPA_HdLmpReq 0 "Initial (Inactive)" 1 "HeadLamp On" 2 "Not Used" 3 "Error Indicator" ;
VAL_ 2239851012 RSPA_OSMirFoldReq 0 "Off" 1 "OS Mirror Fold" 2 "OS Mirror Unfold" 3 "Invalid" ;
VAL_ 934 PTGM_HazardSta 0 "Off" 1 "On" 2 "Inactive" 3 "RESERVED" ;
VAL_ 934 PTGM_ModSta 0 "Power Mode" 1 "Manual Mode" 2 "RESERVED" 3 "Error Indicator" ;
VAL_ 934 PTGM_MovSta 0 "Stop" 1 "Moving" 2 "RESERVED" 3 "Error Indicator" ;
VAL_ 934 PTGM_OptTyp 0 "Off" 1 "On(PTG is applied)" 2 "RESERVED" 3 "Error Indicator" ;
VAL_ 934 PTGM_ReleaseRlySta 0 "Off" 1 "On" 2 "RESERVED" 3 "Error Indicator" ;
VAL_ 934 PTGM_TrnkLkSwSta 0 "Off" 1 "Close & Lock" 2 "RESERVED" 3 "Error Indicator" ;
VAL_ 934 PTGM_UsmSetSta 0 "Default" 1 "Power Mode" 2 "Manual Mode" 3 "Invalid" ;
VAL_ 934 PTGM_HeightRValue 0 "Default" 1 "Level1" 2 "Level2" 3 "Level3" 4 "Level4" 5 "RESERVED" 6 "User Setting" 7 "Invalid" ;
VAL_ 934 PTGM_OpnClsState 0 "Default" 1 "Closed" 2 "1 lvl open" 3 "2 lvl open" 4 "3 lvl open" 5 "4 lvl open" 6 "Full open" 7 "RESERVED" 8 "Closing operation" 9 "Opening operation" 10 "Position Error" 11 "RESERVED" 12 "RESERVED" 13 "RESERVED" 14 "RESERVED" 15 "Invalid" ;
VAL_ 934 PTGM_CmdWarn 0 "Default" 1 "Gear Not P or Vehicle speed" 2 "Obstacle detected" 3 "System temporary error" 4 "Power mode OFF" 5 "RESERVED" 6 "RESERVED" 7 "Invalid" ;
VAL_ 934 PTGM_AntiPinchSnsr 0 "Default" 1 "Applied" 2 "Not applied" 3 "Invalid" ;
VAL_ 934 PTGM_AutoWashModeSta 0 "Default" 1 "PTGM Auto Wash Mode Off (Ready)" 2 "PTGM Auto Wash Mode Off (Error)" 3 "PTGM Auto Wash Mode On" 4 "RESERVED" 5 "RESERVED" 6 "RESERVED" 7 "Invalid" ;
VAL_ 934 PTGM_FobSrch_Req 0 "Off" 1 "Initial Srch Req" 2 "Srch Req After Detect" 3 "Invalid" ;
VAL_ 934 PTGM_TlgtAwayCloseRValue 0 "Default" 1 "Off" 2 "On" 3 "Invalid" ;
VAL_ 934 PTGM_TrnkTlgtOption 0 "Default" 1 "Power Trunk" 2 "Power Tailgate" 3 "Invalid" ;
VAL_ 934 PTGM_LatchType 0 "Default" 1 "Integrated Latch" 2 "Separated Latch" 3 "Invalid" ;
VAL_ 934 PTGM_SpeedRValue 0 "Default" 1 "Fast" 2 "Slow" 3 "Invalid" ;
VAL_ 2239851010 RSPA_Var 0 "init" 1 "RSPA (ENTRY)" 2 "RSPA" 3 "RSPA II" 4 "Reserved" 5 "Reserved" 6 "Reserved" 7 "Reserved" 8 "Reserved" 9 "Reserved" 10 "Reserved" 11 "Reserved" 12 "Reserved" 13 "Reserved" 14 "Reserved" 15 "Invalid" ;
VAL_ 2239851010 RSPA_Sta 0 "RSPA not recognized" 1 "Init" 2 "New Start" 3 "Ready OK" 4 "Assist Req" 5 "Assist OK" 6 "Assist Fail" 7 "Abort" 8 "Ready Fail" ;
VAL_ 2239851010 RSPA_Actv 0 "RSPA Off" 1 "RSPA On" 2 "Reserved" 3 "Reserved" ;
VAL_ 2239851010 RSPA_EvasiveStrBtnDis 0 "Initial" 1 "Do not display evasive steering on/off button" 2 "Display evasive steering on/off button" 3 "Invalid" ;
VAL_ 929 SCM_Opt 0 "Default" 1 "SCM" 2 "Not Used" 3 "Error Indicator" ;
VAL_ 929 Tilt_VirtualLimExist 0 "Off" 1 "On" 2 "Not Used" 3 "Error Indicator" ;
VAL_ 929 Tele_SnsrErr 0 "Off" 1 "On" 2 "Not Used" 3 "Error Indicator" ;
VAL_ 929 Tele_VirtualLim 0 "Off" 1 "Fwd" 2 "Bwd" 3 "Error Indicator" ;
VAL_ 929 Tele_VirtualLimExist 0 "Off" 1 "On" 2 "Not Used" 3 "Error Indicator" ;
VAL_ 929 TiltTele_Profile1MemoryExist 0 "Off" 1 "On" 2 "Not Used" 3 "Error Indicator" ;
VAL_ 929 Tilt_MnlSwSta 0 "Off" 1 "Up" 2 "Down" 3 "Error Indicator" ;
VAL_ 929 TiltTele_Profile2MemoryExist 0 "Off" 1 "On" 2 "Not Used" 3 "Error Indicator" ;
VAL_ 929 TiltTele_GuestMemoryExist 0 "Off" 1 "On" 2 "Not Used" 3 "Error Indicator" ;
VAL_ 929 TiltTele_IMS1MemoryExist 0 "Off" 1 "On" 2 "Not Used" 3 "Error Indicator" ;
VAL_ 929 TiltTele_IMS2MemoryExist 0 "Off" 1 "On" 2 "Not Used" 3 "Error Indicator" ;
VAL_ 929 TiltTele_IMS3MemoryExist 0 "Off" 1 "On" 2 "Not Used" 3 "Error Indicator" ;
VAL_ 929 TiltTele_ReturnMemoryExist 0 "Off" 1 "On" 2 "Not Used" 3 "Error Indicator" ;
VAL_ 929 Tilt_OpSta 0 "Off" 1 "Moving" 2 "MovingInhibit" 3 "AlreadyReached" ;
VAL_ 929 Tele_OpSta 0 "Off" 1 "Moving" 2 "MovingInhibit" 3 "AlreadyReached" ;
VAL_ 929 Tele_MnlSwSta 0 "Off" 1 "Fwd" 2 "Bwd" 3 "Error Indicator" ;
VAL_ 929 Tilt_SnsrErr 0 "Off" 1 "On" 2 "Not Used" 3 "Error Indicator" ;
VAL_ 929 Tilt_VirtualLim 0 "Off" 1 "Up" 2 "Down" 3 "Error Indicator" ;
VAL_ 2239851011 RSPA_TrgtGearSta 0 "Idle" 1 "P" 2 "R" 3 "N" 4 "D" ;
VAL_ 2239851011 RSPA_IdOutWarnReq 0 "No Request" 1 "Change Request" 2 "Not Used" 3 "Error Indicator" ;
VAL_ 2239851011 RSPA_IndBlnkReq 0 "No request" 1 "Type1" 2 "Type2" 3 "Type3" 4 "Type4" 5 "Type5" 6 "Reserved" 7 "Reserved" ;
VAL_ 2239851011 RSPA_SysOff 0 "default" 1 "system off" ;
VAL_ 2239851011 RSPA_DccCmd 0 "No request" 1 "Soft Brake" 2 "Hard 1 Brake" 3 "Hard 2 Brake" ;
VAL_ 2239851011 RSPA_StopReq 0 "No request" 1 "Stop control is required" 2 "Not Used" 3 "Error Indicator" ;
VAL_ 2239851011 RSPA_SelDevInfo 0 "default" 1 "SmartPhone" 2 "Fob" 3 "Reserved" ;
VAL_ 2239851011 RSPA_SelFuncInfo 0 "default" 1 "Parking" 2 "Remote Forward/Backward" 3 "Reserved" ;
VAL_ 2239851011 RSPA_EpbReq 0 "No request" 1 "release request" 2 "normal apply" ;
VAL_ 2239851011 RSPA_AddtnlAccelActv 0 "Inactive" 1 "Active" 2 "Not Used" 3 "Error Indicator" ;
VAL_ 2239851011 RSPA_Opt 0 "RSPA not applied" 1 "RSPA applied" 2 "Not Used" 3 "Error Indicator" ;
VAL_ 2239851011 RSPA_RmtPrlExitDis 0 "Initial" 1 "Do not display remote parallel exit" 2 "Display remote parallel exit" 3 "Invalid" ;
VAL_ 2239851011 RSPA_ExtLampReq 0 "Inactive (No Request)" 1 "Hazard Lamp Active On" 2 "Hazard Lamp Active Off" 3 "Left Turn Signal On" 4 "Right Turn Signal On" 5 "reserved" 6 "reserved" 7 "reserved" ;
VAL_ 2239851011 RSPA_UppLtTypDis 0 "init" 1 "Not found" 2 "Reverse perpendicular" 3 "Reverse parallel" 4 "Reverse diagonal" 5 "Forward diagonal" 6 "Reserved" 7 "Invalid" ;
VAL_ 2239851011 RSPA_LwrLtTypDis 0 "init" 1 "Not found" 2 "Reverse perpendicular" 3 "Reverse parallel" 4 "Reverse diagonal" 5 "Forward diagonal" 6 "Reserved" 7 "Invalid" ;
VAL_ 2239851011 RSPA_UppRtTypDis 0 "init" 1 "Not found" 2 "Reverse perpendicular" 3 "Reverse parallel" 4 "Reverse diagonal" 5 "Forward diagonal" 6 "Reserved" 7 "Invalid" ;
VAL_ 2239851011 RSPA_LwrRtTypDis 0 "init" 1 "Not found" 2 "Reverse perpendicular" 3 "Reverse parallel" 4 "Reverse diagonal" 5 "Forward diagonal" 6 "Reserved" 7 "Invalid" ;
VAL_ 2239851011 RSPA_CrankingReq 0 "Init" 1 "to RSPA Remote Cranking" 2 "to Normal Cranking" 3 "to IG OFF" ;
VAL_ 2239851009 ADAS_PRK_Crc3Val 0 "0x0x0~0xFFFF:CRCValue" 65535 "0x0x0~0xFFFF:CRCValue" ;
VAL_ 2239851009 ADAS_PRK_AlvCnt3Val 0 "0x0x0~0xFF:AlvCntValue" 255 "0x0x0~0xFF:AlvCntValue" ;
VAL_ 2239851009 RSPA_AvnDis 0 "init" 1 "No display" 2 "RSPA È­¸é Ãâ·Â" 3 "invalid" ;
VAL_ 2239851009 RSPA_AvnModDis 0 "init" 1 "ÁÖÂ÷¸ðµå" 2 "ÃâÂ÷¸ðµå" 3 "invalid" ;
VAL_ 2239851009 RSPA_AvnSubViewDis 0 "init" 1 "No display" 2 "´ëÃ¼ÀÌ¹ÌÁö Ãâ·Â" 3 "invalid" ;
VAL_ 2239851009 RSPA_AvnHmiDis 0 "none" 1 "Select operating mode" 2 "SMART Parking" 3 "REMOTE Parking" 4 "Parking completed" 5 "SMART Pull-out" 6 "Pull-out completed" 7 "RSPA cancelled - Read Manual" 8 "RSPA cancelled - Operate vehicle manually" 9 "Not working condition - Exceed Limit Speed" 10 "Searching for Parking space - Reduce speed under 20km" 11 "Check RSPA - Visit Tech Center" 12 "Reserved" 13 "display Front camera - moving forward" 14 "display Rear camera - moving backward" 15 "Reserved" 16 "RSPA paused - Check tailgate closed" 17 "RSPA paused - Remote control range exceeded" 18 "RSPA pasued - Hold down dedicated button on key fob" 19 "Parking completed - manually" 20 "Pull-out completed - manually" 21 "Reserved" 22 "RSPA paused - Check all doors closed" 23 "RSPA paused - Check trunk closed" 24 "RSPA paused - RCCW" 25 "RSPA paused - Fasten seat belt on drivers side" 26 "Operation guide - Release brake" 27 "RSPA paused - Monitor surrounding area" 28 "RSPA cancelled - Trailer mode" 29 "RSPA cancelled - PDW Off" 30 "RSPA cancelled - over 20km" 31 "RSPA cancelled - not stop" 32 "RSPA cancelled - reverse movement" 33 "RSPA cancelled - narrow space" 34 "Not working condition - trailer mode" 35 "RSPA cancelled - Monitor surrounding area" 36 "RSPA cancelled - Check road condition" 37 "RSPA cancelled - Exceed operating distance" 38 "RSPA cancelled - Exceed operation time" 39 "RSPA cancelled - Detect cancel input" 40 "RSPA cancelled - Detect remote start button input" 41 "RSPA cancelled - Detect B" 42 "RSPA cancelled - Detect unfasten S" 43 "RSPA cancelled - Detect T" 44 "RSPA cancelled - Detect EPB operation" 45 "RSPA cancelled - Detect Pedal operation" 46 "RSPA cancelled - Hood open" 47 "RSPA cancelled - Detect S" 48 "RSPA cancelled - USS blockage" 49 "RSPA cancelled - Check SVM Camera" 50 "Reserved" 51 "Reserved" 52 "Reserved" 53 "Reserved" 54 "Reserved" 55 "Reserved" 56 "Reserved" 57 "Reserved" 58 "Reserved" 59 "Reserved" 60 "Reserved" 61 "Reserved" 62 "Reserved" 63 "Reserved" 64 "Reserved" 65 "Reserved" 66 "Reserved" 67 "Reserved" 68 "Reserved" 69 "Reserved" 70 "Reserved" 71 "Reserved" 72 "Reserved" 73 "Reserved" 74 "Reserved" 75 "Reserved" 76 "Reserved" 77 "Reserved" 78 "Reserved" 79 "Reserved" 80 "Reserved" 81 "Reserved" 82 "Reserved" 83 "Reserved" 84 "Reserved" 85 "Reserved" 86 "Reserved" 87 "Reserved" 88 "Reserved" 89 "Reserved" 90 "Reserved" 91 "Reserved" 92 "Reserved" 93 "Reserved" 94 "Reserved" 95 "Reserved" 96 "Reserved" 97 "Reserved" 98 "Reserved" 99 "Reserved" 100 "Reserved" 101 "Reserved" 102 "Reserved" 103 "Reserved" 104 "Reserved" 105 "Reserved" 106 "Reserved" 107 "Reserved" 108 "Reserved" 109 "Reserved" 110 "Reserved" 111 "Reserved" 112 "Reserved" 113 "Reserved" 114 "Reserved" 115 "Reserved" 116 "Reserved" 117 "Reserved" 118 "Reserved" 119 "Reserved" 120 "Reserved" 121 "Reserved" 122 "Reserved" 123 "Reserved" 124 "Reserved" 125 "Reserved" 126 "Reserved" 127 "Reserved" 128 "Searching for Parking space - Drive forwards" 129 "Searching Completed - Stop vehicle to park or Move forward" 130 "Select parking mode" 131 "Checking space - Stop the vehicle to check space" 132 "Checking completed - Select pull-out mode" 133 "Remote Moving F" 134 "under Remote Control" 135 "Remote Moving F" 136 "Operation guide - Reinput Parking Button" 137 "Operation guide - Reinput SMART Key Button" 138 "Not working condition - Read Manual" 139 "Not working condition - Steep road slope up" 140 "Not working condition - Steep road slope down" 141 "RSPA cancelled - Steep road slope up" 142 "RSPA cancelled - Steep road slope down" 143 "Not working condition - USS blockage" 144 "RSPA Guide Pop - up" 145 "RSPA cancelled ? DCT overtemp" 146 "Not working condition ? DCT overtemp" 147 "Checking Completed - Remote exit control" 148 "0x94~0xFE:Reserved" 254 "0x94~0xFE:Reserved" 255 "Invalid" ;
VAL_ 924 RLPSU_FailState_PopUp 0 "Default" 1 "Relax Mode Position" 2 "Return Mode Position" 3 "Monitor Mode Position" 4 "Reading Mode Position" 5 "RESERVED" 6 "RESERVED" 7 "RESERVED" 8 "RESERVED" 9 "Mode-Fail (1st Seat Condition)" 10 "Mode-Fail (Side Sliding Limit SW Condition)" 11 "Mode-Fail (Vehicle Condition)" 12 "Mode-Fail (3rd Seat Condition)" 13 "Mode-Fail (Anti-Pinch)" 14 "Mode-Fail (Seat System Error)" 15 "Invalid" ;
VAL_ 924 RL_TLLnkRtnStop 0 "Default" 1 "Return Stop" 2 "Return Fail" 3 "Invalid" ;
VAL_ 924 RL_1stLnkRtnStop 0 "Default" 1 "Return Stop" 2 "Return Fail" 3 "Invalid" ;
VAL_ 924 RLPSU_Folding_State_Popup_EC 0 "Default" 1 "Folded(Finished)" 2 "Unfolded(Finished)" 3 "Mode-Fail(Anti-Pinch)" 4 "Mode-Fail(TGS&Break Condition)" 5 "Mode-Fail(System Error)" 6 "RESERVED" 7 "Invalid" ;
VAL_ 924 RLPSU_Relax_State_Popup_EC 0 "Default" 1 "Relaxed(Finished)" 2 "Unrelaxed(Finished)" 3 "Relax (Relaxing)" 4 "Return (Returning)" 5 "RESERVED" 6 "RESERVED" 7 "Invalid" ;
VAL_ 924 RLPSU_Reclining_State_Popup 0 "Default" 1 "Front Ended Position(Finished)" 2 "Rear Ended Position(Finished)" 3 "Mode-Fail(Anti-Pinch)" 4 "Mode-Fail(TGS & Break Condition)" 5 "Mode-Fail(System Error)" 6 "RESERVED" 7 "Invalid" ;
VAL_ 924 RL_AstStStdPosMovReq 0 "Default" 1 "ON" 2 "Reserved" 3 "Invalid" ;
VAL_ 924 RL_TLStStdPosMovReq 0 "Default" 1 "ON" 2 "Reserved" 3 "Invalid" ;
VAL_ 924 RL_AstStStdPosMovReq_Fold 0 "Default" 1 "ON" 2 "Reserved" 3 "Invalid" ;
VAL_ 922 RRPSU_FailState_PopUp 0 "Default" 1 "Relax Mode Position" 2 "Retrun Mode Position" 3 "Monitor Mode Position" 4 "Reading Mode Position" 5 "Unused" 6 "Unused" 7 "Unused" 8 "Unused" 9 "Mode-Fail (1st Seat Condition)" 10 "Mode-Fail (Side Sliding Limit SW Unlocked)" 11 "Mode-Fail (Vehicle Condition)" 12 "Mode-Fail (3rd Seat Condition)" 13 "Mode-Fail (Anti-Pinch)" 14 "Mode-Fail (Seat System Error)" 15 "Invalid" ;
VAL_ 922 RR_TRLnkRtnStop 0 "Default" 1 "Return Stop" 2 "Return Fail" 3 "Invalid" ;
VAL_ 922 RR_1stLnkRtnStop 0 "Default" 1 "Return Stop" 2 "Return Fail" 3 "Invalid" ;
VAL_ 922 RRPSU_Folding_State_Popup_EC 0 "Default" 1 "Relaxed(Finished)" 2 "Unfolded(Finished)" 3 "Mode-Fail(Anti-Pinch)" 4 "Mode-Fail(TGS&Break Condition)" 5 "Mode-Fail(System Error)" 6 "Unused" 7 "Invalid" ;
VAL_ 922 RRPSU_Relax_State_Popup_EC 0 "Default" 1 "Relaxed(Finished)" 2 "UnRelaxed(Finished)" 3 "Relax (Relaxing)" 4 "Return(Returning)" 5 "Unused" 6 "Unused" 7 "Invalid" ;
VAL_ 922 RRPSU_Reclining_State_Popup 0 "Default" 1 "Front Ended Position(Finished)" 2 "Rear Eeded Position(Finished)" 3 "Mode-Fail(Anti-Pinch)" 4 "Mode-Fail(TGS & Brake Condition)" 5 "Mode-Fail(System Error)" 6 "Unused" 7 "Invalid" ;
VAL_ 922 RR_AstStStdPosMovReq 0 "Default" 1 "ON" 2 "Reserved" 3 "Invalid" ;
VAL_ 922 RR_TRStStdPosMovReq 0 "Default" 1 "ON" 2 "Reserved" 3 "Invalid" ;
VAL_ 922 RR_AstStStdPosMovReq_Fold 0 "Default" 1 "ON" 2 "Reserved" 3 "Invalid" ;
VAL_ 2424580609 DATC_Crc13Val 0 "0x0x0~0xFFFF:CRCValue" 65535 "0x0x0~0xFFFF:CRCValue" ;
VAL_ 2424580609 DATC_AlvCnt13Val 0 "0x0x0~0xFF:AlvCntValue" 255 "0x0x0~0xFF:AlvCntValue" ;
VAL_ 2424580609 DATC_MltAutoBlrTxt 0 "Default" 1 "Blank" 2 "LOW" 3 "MEDIUM" 4 "HIGH" 5 "Reserved" 6 "Reserved" 7 "ErrorIndicaor" ;
VAL_ 2424580609 DATC_MltAutoBlrTxt_Ps 0 "Default" 1 "Blank" 2 "LOW" 3 "MEDIUM" 4 "HIGH" 5 "Reserved" 6 "Reserved" 7 "ErrorIndicaor" ;
VAL_ 2424580609 DATC_MltAutoBlrTxt_Rr 0 "Default" 1 "Blank" 2 "LOW" 3 "MEDIUM" 4 "HIGH" 5 "Reserved" 6 "Reserved" 7 "ErrorIndicaor" ;
VAL_ 2424580609 DATC_RLStTmblrSwReq 0 "Default" 1 "Up" 2 "Down" 3 "Error Indicator" ;
VAL_ 2424580609 DATC_RRStTmblrSwReq 0 "Default" 1 "Up" 2 "Down" 3 "Error Indicator" ;
VAL_ 2424580609 DATC_DisPnlState 0 "Front Display State" 1 "Rear Display State" 2 "Not used" 3 "Error Indicator" ;
VAL_ 2424580609 DATC_Opt5Typ 0 "applied options (See Description)" 1 "applied options (See Description)" 2 "applied options (See Description)" 3 "applied options (See Description)" 4 "applied options (See Description)" 5 "applied options (See Description)" 6 "applied options (See Description)" 7 "applied options (See Description)" 8 "applied options (See Description)" 9 "applied options (See Description)" 10 "applied options (See Description)" 11 "applied options (See Description)" 12 "applied options (See Description)" 13 "applied options (See Description)" 14 "applied options (See Description)" 15 "applied options (See Description)" ;
VAL_ 915 BCM_Crc18Val 0 "0x0x0~0xFF:CRCValue" 255 "0x0x0~0xFF:CRCValue" ;
VAL_ 915 BCM_AlvCnt18Val 0 "AlvCntValue" 1 "AlvCntValue" 2 "AlvCntValue" 3 "AlvCntValue" 4 "AlvCntValue" 5 "AlvCntValue" 6 "AlvCntValue" 7 "AlvCntValue" 8 "AlvCntValue" 9 "AlvCntValue" 10 "AlvCntValue" 11 "AlvCntValue" 12 "AlvCntValue" 13 "AlvCntValue" 14 "AlvCntValue" 15 "AlvCntValue" ;
VAL_ 915 Trunk_IBU_OpnDiagSetSta 0 "OFF" 1 "ON" 2 "Not Used" 3 "Error Indicator" ;
VAL_ 915 Trunk_TrnkTlgtReleaseRly 0 "Off" 1 "On" 2 "Invalid" 3 "Error Indicator" ;
VAL_ 915 Trunk_TrnkTlgtOpenOutput_PTGM 0 "Off" 1 "On" 2 "Invalid" 3 "Error Indicator" ;
VAL_ 915 Trunk_TrnkTlgtOpenOutput_ICU 0 "Off" 1 "On" 2 "Invalid" 3 "Error Indicator" ;
VAL_ 915 Trunk_TrnkPassiveOpenOutput 0 "Off" 1 "On" 2 "Invalid" 3 "Error Indicator" ;
VAL_ 915 TiltTele_CurProfileState 0 "Dafault" 1 "Guest" 2 "Profile 1" 3 "Profile 2" 4 "Not Used" 5 "Not Used" 6 "Not Used" 7 "Error Indicator" ;
VAL_ 915 TiltTele_USMEsyAcsSetState 0 "Default" 1 "Steering Off" 2 "Steering On" 3 "Error Indicator" ;
VAL_ 915 TiltTele_PreEsyAcsProfile 0 "Default" 1 "Profile 1" 2 "Profile 2" 3 "Guest" 4 "Not Used" 5 "Not Used" 6 "Not Used" 7 "Error Indicator" ;
VAL_ 915 Tilt_MnlInitCmd 0 "Off" 1 "Up" 2 "Down" 3 "Error Indicator" ;
VAL_ 915 Tilt_MnlOpCmd 0 "Off" 1 "Up" 2 "Down" 3 "Error Indicator" ;
VAL_ 915 Tele_MnlInitCmd 0 "Off" 1 "Fwd" 2 "Bwd" 3 "Error Indicator" ;
VAL_ 915 Tilt_AutoOpCmd 0 "Off" 1 "GetOn" 2 "GetOff" 3 "IMS 1" 4 "IMS 2" 5 "IMS 3" 6 "SmartIMS" 7 "PersonalizationService" 8 "PreEasyAccessProfileGetOn" 9 "PreEasyAccessProfileLast" 10 "OneTouchRelax" 11 "OneTouchReturn" 12 "Not Used" 13 "Not Used" 14 "Not Used" 15 "Error Indicator" ;
VAL_ 915 TiltTele_PlyBckState 0 "Stop" 1 "Play 1" 2 "Play 2" 3 "Play 3" 4 "SmartIMS" 5 "Profile 1" 6 "Profile 2" 7 "Guest" 8 "Not Used" 9 "Not Used" 10 "Not Used" 11 "Not Used" 12 "Not Used" 13 "Not Used" 14 "Not Used" 15 "Error Indicator" ;
VAL_ 915 Tele_MnlOpCmd 0 "Off" 1 "Fwd" 2 "Bwd" 3 "Error Indicator" ;
VAL_ 915 Tele_AutoOpCmd 0 "Off" 1 "IMS1" 2 "IMS2" 3 "IMS3" 4 "SmartIMS" 5 "PersonalizationService" 6 "PreEasyAccessProfileGetOn" 7 "PreEasyAccessProfileLast" 8 "OneTouchRelax" 9 "OneTouchReturn" 10 "Not Used" 11 "Not Used" 12 "Not Used" 13 "Not Used" 14 "Not Used" 15 "Error Indicator" ;
VAL_ 912 HU_BLTN_CAM_UI_Mode 0 "HU UI mode" 1 "Built-In Cam Mode(GUI or HU File Access)" 2 "Built-In Cam Setting Mode" 3 "Reserved" 4 "Reserved" 5 "Reserved" 6 "Reserved" 7 "Reserved" 8 "Reserved" 9 "Reserved" 10 "Reserved" 11 "Reserved" 12 "Reserved" 13 "Reserved" 14 "Reserved" 15 "Invalid" ;
VAL_ 912 HU_BLTN_CAM_Display 0 "AVN Mode" 1 "DVRS Mode" 2 "Popup Mode" 3 "Reserved" 4 "Reserved" 5 "Built-in Cam update mode" 6 "Reserved" 7 "Invalid" ;
